VERSION ""

NS_ :

BS_:

BU_: SCM BC1 BC2 ECM PSC ABS Brakes__Drive_Axle_1 EPS IC GPS WCM VCM Seat_Control_1 ISC1 HCU IDT GMRS XM RH AUTON LHC CIM IMU BC3 IC2 EPC1 EPC2 EPC3 EPC4 BMC1 BMC2 APU2 APU1 SRVTOOL RHC RCM

BO_ 2566884352 Torque_Data_00: 8 ECM
 SG_ Message_Checksum : 61|4@1+ (1,0) [0|15] "count" Vector__XXX
 SG_ pEstimated_Torque : 16|16@1+ (0.03125,-1024) [-1024|3071] "Nm" Vector__XXX
 SG_ pCurrent_RPM_Rated_Torque : 0|16@1+ (0.03125,-1024) [-1024|3071] "Nm" Vector__XXX
 SG_ Brake_Switch : 56|2@1+ (1,0) [0|3] "bit" Vector__XXX
 SG_ Message_Counter : 58|4@1+ (1,0) [0|15] "count" Vector__XXX

BO_ 2566876928 pER1_00: 8 ECM
 SG_ pSecondary_Air_Valve_Control : 0|2@1+ (1,0) [0|3] "state" Vector__XXX

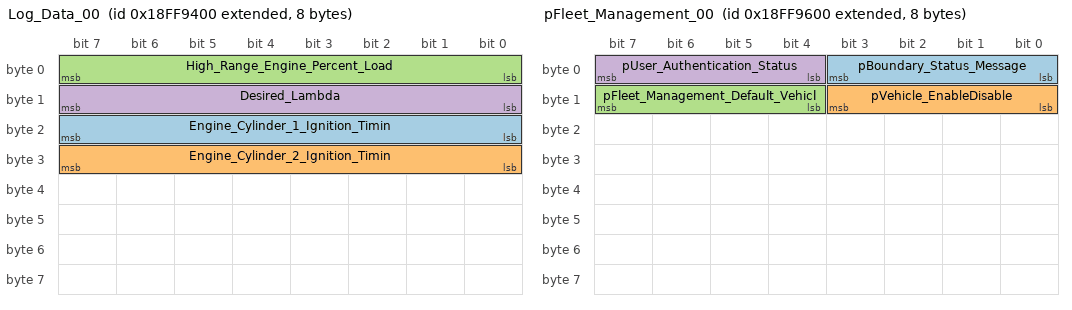
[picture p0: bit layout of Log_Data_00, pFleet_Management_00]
BO_ 2566886400 Log_Data_00: 8 ECM
 SG_ Engine_Cylinder_1_Ignition_Timin : 16|8@1+ (1,-128) [-128|383] "deg" Vector__XXX
 SG_ Engine_Cylinder_2_Ignition_Timin : 24|8@1+ (1,-128) [-128|383] "deg" Vector__XXX
 SG_ High_Range_Engine_Percent_Load : 0|8@1+ (2,0) [0|511] "%" Vector__XXX
 SG_ Desired_Lambda : 8|8@1+ (0.0078125,0) [0|1] "" Vector__XXX

BO_ 2566886912 pFleet_Management_00: 8 ECM
 SG_ pBoundary_Status_Message : 0|4@1+ (1,0) [0|15] "state" Vector__XXX
 SG_ pVehicle_EnableDisable : 8|4@1+ (1,0) [0|15] "state" Vector__XXX
 SG_ pFleet_Management_Default_Vehicl : 12|4@1+ (1,0) [0|15] "state" Vector__XXX
 SG_ pUser_Authentication_Status : 4|4@1+ (1,0) [0|15] "state" Vector__XXX

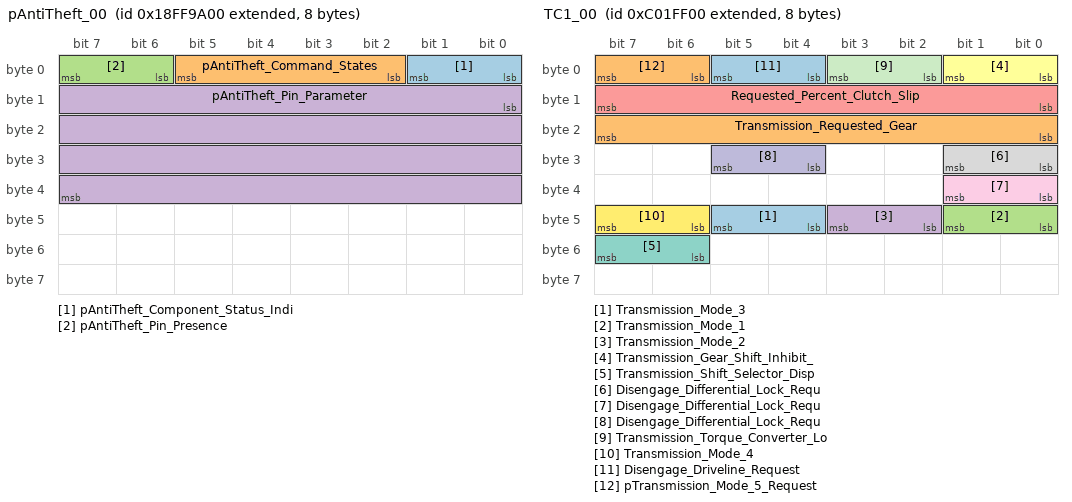
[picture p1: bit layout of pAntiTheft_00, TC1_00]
BO_ 2566887936 pAntiTheft_00: 8 ECM
 SG_ pAntiTheft_Component_Status_Indi : 0|2@1+ (1,0) [0|3] "state" Vector__XXX
 SG_ pAntiTheft_Command_States : 2|4@1+ (1,0) [0|15] "state" Vector__XXX
 SG_ pAntiTheft_Pin_Presence : 6|2@1+ (1,0) [0|3] "state" Vector__XXX
 SG_ pAntiTheft_Pin_Parameter : 8|32@1+ (1,0) [0|4294967295] "ASCII" Vector__XXX

BO_ 2348941056 TC1_00: 8 ECM
 SG_ Transmission_Mode_3 : 44|2@1+ (1,0) [0|3] "bit" TCM
 SG_ Transmission_Requested_Gear : 16|8@1+ (1,-125) [-125|380] "gear_value" TCM
 SG_ Transmission_Mode_1 : 40|2@1+ (1,0) [0|3] "bit" TCM
 SG_ Transmission_Mode_2 : 42|2@1+ (1,0) [0|3] "bit" TCM
 SG_ Requested_Percent_Clutch_Slip : 8|8@1+ (0.4,0) [0|101.4] "%" TCM
 SG_ Transmission_Gear_Shift_Inhibit_ : 0|2@1+ (1,0) [0|3] "bit" TCM
 SG_ Transmission_Shift_Selector_Disp : 54|2@1+ (1,0) [0|3] "bit" TCM
 SG_ Disengage_Differential_Lock_Requ : 24|2@1+ (1,0) [0|3] "bit" TCM
 SG_ Disengage_Differential_Lock_Requ : 32|2@1+ (1,0) [0|3] "bit" TCM
 SG_ Disengage_Differential_Lock_Requ : 28|2@1+ (1,0) [0|3] "bit" TCM
 SG_ Transmission_Torque_Converter_Lo : 2|2@1+ (1,0) [0|3] "bit" TCM
 SG_ Transmission_Mode_4 : 46|2@1+ (1,0) [0|3] "bit" TCM
 SG_ Disengage_Driveline_Request : 4|2@1+ (1,0) [0|3] "bit" TCM
 SG_ pTransmission_Mode_5_Request : 6|2@1+ (1,0) [0|3] "state" TCM

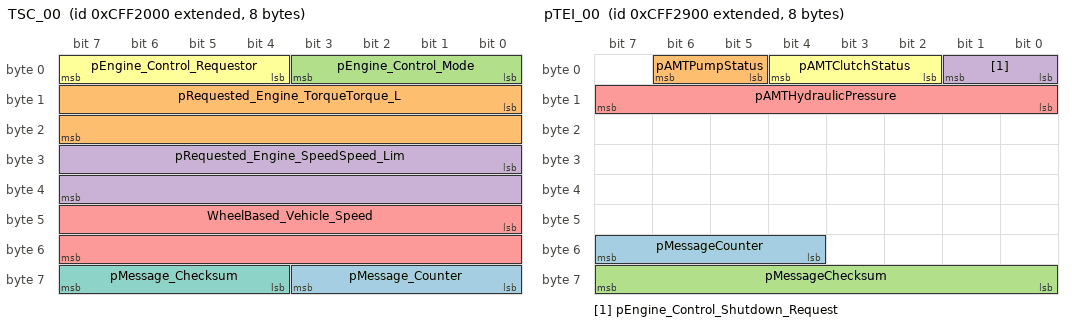
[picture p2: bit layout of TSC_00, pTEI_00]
BO_ 2365530112 TSC_00: 8 ECM
 SG_ pMessage_Counter : 56|4@1+ (1,0) [0|15] "count" TCM
 SG_ pRequested_Engine_TorqueTorque_L : 8|16@1+ (0.03125,-400) [-400|2447] "Nm" TCM
 SG_ pEngine_Control_Mode : 0|4@1+ (1,0) [0|15] "state" TCM
 SG_ pRequested_Engine_SpeedSpeed_Lim : 24|16@1+ (1,0) [0|65535] "rpm" TCM
 SG_ WheelBased_Vehicle_Speed : 40|16@1+ (0.00390625,0) [0|255] "km/h" TCM
 SG_ pEngine_Control_Requestor : 4|4@1+ (1,0) [0|15] "state" TCM
 SG_ pMessage_Checksum : 60|4@1+ (1,0) [0|15] "count" TCM

BO_ 2365532416 pTEI_00: 8 ECM
 SG_ pMessageCounter : 52|4@1+ (1,0) [0|15] "count" TCM
 SG_ pAMTPumpStatus : 5|2@1+ (1,0) [0|3] "state" TCM
 SG_ pMessageChecksum : 56|8@1+ (1,0) [0|255] "count" TCM
 SG_ pEngine_Control_Shutdown_Request : 0|2@1+ (1,0) [0|3] "state" TCM
 SG_ pAMTHydraulicPressure : 8|8@1+ (16,0) [0|4095] "kPa" TCM
 SG_ pAMTClutchStatus : 2|3@1+ (1,0) [0|7] "state" TCM

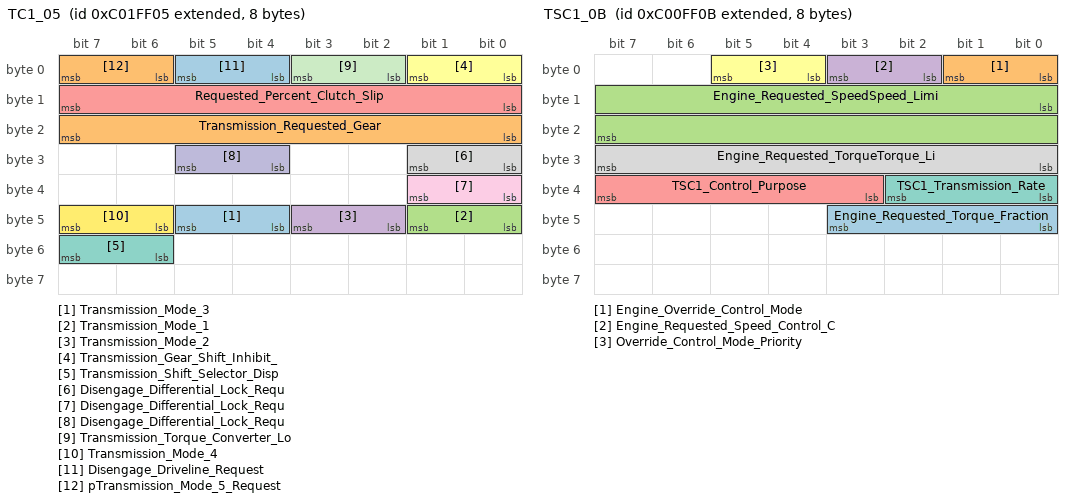
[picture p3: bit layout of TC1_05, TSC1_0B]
BO_ 2348941061 TC1_05: 8 PSC
 SG_ Transmission_Mode_3 : 44|2@1+ (1,0) [0|3] "bit" Vector__XXX
 SG_ Transmission_Requested_Gear : 16|8@1+ (1,-125) [-125|380] "gear_value" Vector__XXX
 SG_ Transmission_Mode_1 : 40|2@1+ (1,0) [0|3] "bit" Vector__XXX
 SG_ Transmission_Mode_2 : 42|2@1+ (1,0) [0|3] "bit" Vector__XXX
 SG_ Requested_Percent_Clutch_Slip : 8|8@1+ (0.4,0) [0|101.4] "%" Vector__XXX
 SG_ Transmission_Gear_Shift_Inhibit_ : 0|2@1+ (1,0) [0|3] "bit" Vector__XXX
 SG_ Transmission_Shift_Selector_Disp : 54|2@1+ (1,0) [0|3] "bit" Vector__XXX
 SG_ Disengage_Differential_Lock_Requ : 24|2@1+ (1,0) [0|3] "bit" Vector__XXX
 SG_ Disengage_Differential_Lock_Requ : 32|2@1+ (1,0) [0|3] "bit" Vector__XXX
 SG_ Disengage_Differential_Lock_Requ : 28|2@1+ (1,0) [0|3] "bit" Vector__XXX
 SG_ Transmission_Torque_Converter_Lo : 2|2@1+ (1,0) [0|3] "bit" Vector__XXX
 SG_ Transmission_Mode_4 : 46|2@1+ (1,0) [0|3] "bit" Vector__XXX
 SG_ Disengage_Driveline_Request : 4|2@1+ (1,0) [0|3] "bit" Vector__XXX
 SG_ pTransmission_Mode_5_Request : 6|2@1+ (1,0) [0|3] "state" Vector__XXX

BO_ 2348875531 TSC1_0B: 8 ABS
 SG_ Engine_Requested_Torque_Fraction : 40|4@1+ (0.125,0) [0|1] "%" Vector__XXX
 SG_ Engine_Override_Control_Mode : 0|2@1+ (1,0) [0|3] "bit" Vector__XXX
 SG_ Engine_Requested_SpeedSpeed_Limi : 8|16@1+ (0.125,0) [0|8191] "rpm" Vector__XXX
 SG_ Engine_Requested_Speed_Control_C : 2|2@1+ (1,0) [0|3] "bit" Vector__XXX
 SG_ TSC1_Control_Purpose : 35|5@1+ (1,0) [0|31] "bit" Vector__XXX
 SG_ Override_Control_Mode_Priority : 4|2@1+ (1,0) [0|3] "bit" Vector__XXX
 SG_ TSC1_Transmission_Rate : 32|3@1+ (1,0) [0|7] "bit" Vector__XXX
 SG_ Engine_Requested_TorqueTorque_Li : 24|8@1+ (1,-125) [-125|380] "%" Vector__XXX

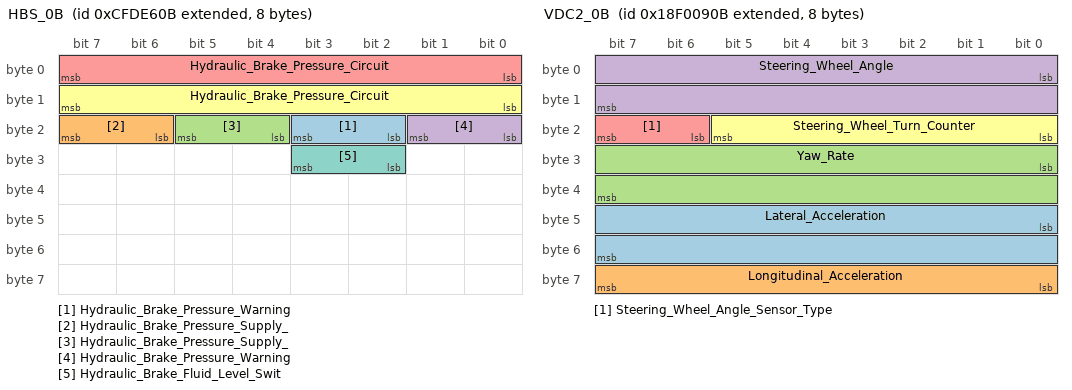
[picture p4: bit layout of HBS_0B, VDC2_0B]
BO_ 2365449739 HBS_0B: 8 ABS
 SG_ Hydraulic_Brake_Pressure_Warning : 18|2@1+ (1,0) [0|3] "bit" Vector__XXX
 SG_ Hydraulic_Brake_Pressure_Supply_ : 22|2@1+ (1,0) [0|3] "bit" Vector__XXX
 SG_ Hydraulic_Brake_Pressure_Supply_ : 20|2@1+ (1,0) [0|3] "bit" Vector__XXX
 SG_ Hydraulic_Brake_Pressure_Warning : 16|2@1+ (1,0) [0|3] "bit" Vector__XXX
 SG_ Hydraulic_Brake_Pressure_Circuit : 0|8@1+ (100,0) [0|25599] "kPa" Vector__XXX
 SG_ Hydraulic_Brake_Pressure_Circuit : 8|8@1+ (100,0) [0|25599] "kPa" Vector__XXX
 SG_ Hydraulic_Brake_Fluid_Level_Swit : 26|2@1+ (1,0) [0|3] "bit" Vector__XXX

BO_ 2565867787 VDC2_0B: 8 ABS
 SG_ Lateral_Acceleration : 40|16@1+ (0.00048828125,-15.687) [-15.687|46.687] "m/s2" Vector__XXX
 SG_ Longitudinal_Acceleration : 56|8@1+ (0.1,-12.5) [-12.5|37.1] "m/s2" Vector__XXX
 SG_ Yaw_Rate : 24|16@1+ (0.0001220703125,-3.92) [-3.92|10.92] "rad/s" Vector__XXX
 SG_ Steering_Wheel_Angle : 0|16@1+ (0.0009765625,-31.374) [-31.374|94.374] "rad" Vector__XXX
 SG_ Steering_Wheel_Angle_Sensor_Type : 22|2@1+ (1,0) [0|3] "bit" Vector__XXX
 SG_ Steering_Wheel_Turn_Counter : 16|6@1+ (1,-32) [-32|95] "turns" Vector__XXX

BO_ 2349465355 SRASI_0B: 8 ABS
 SG_ Static_Roll_Angle : 0|8@1+ (1,-125) [-125|380] "deg" Vector__XXX

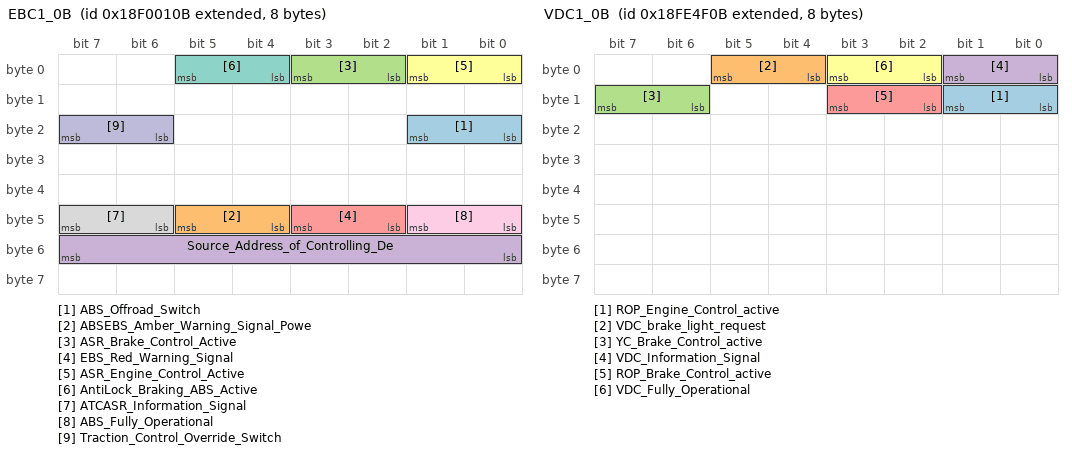
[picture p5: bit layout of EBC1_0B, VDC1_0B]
BO_ 2565865739 EBC1_0B: 8 ABS
 SG_ ABS_Offroad_Switch : 16|2@1+ (1,0) [0|3] "bit" Vector__XXX
 SG_ ABSEBS_Amber_Warning_Signal_Powe : 44|2@1+ (1,0) [0|3] "bit" Vector__XXX
 SG_ ASR_Brake_Control_Active : 2|2@1+ (1,0) [0|3] "bit" Vector__XXX
 SG_ Source_Address_of_Controlling_De : 48|8@1+ (1,0) [0|255] "SA" Vector__XXX
 SG_ EBS_Red_Warning_Signal : 42|2@1+ (1,0) [0|3] "bit" Vector__XXX
 SG_ ASR_Engine_Control_Active : 0|2@1+ (1,0) [0|3] "bit" Vector__XXX
 SG_ AntiLock_Braking_ABS_Active : 4|2@1+ (1,0) [0|3] "bit" Vector__XXX
 SG_ ATCASR_Information_Signal : 46|2@1+ (1,0) [0|3] "bit" Vector__XXX
 SG_ ABS_Fully_Operational : 40|2@1+ (1,0) [0|3] "bit" Vector__XXX
 SG_ Traction_Control_Override_Switch : 22|2@1+ (1,0) [0|3] "bit" Vector__XXX

BO_ 2566803211 VDC1_0B: 8 ABS
 SG_ ROP_Engine_Control_active : 8|2@1+ (1,0) [0|3] "bit" Vector__XXX
 SG_ VDC_brake_light_request : 4|2@1+ (1,0) [0|3] "bit" Vector__XXX
 SG_ YC_Brake_Control_active : 14|2@1+ (1,0) [0|3] "bit" Vector__XXX
 SG_ VDC_Information_Signal : 0|2@1+ (1,0) [0|3] "bit" Vector__XXX
 SG_ ROP_Brake_Control_active : 10|2@1+ (1,0) [0|3] "bit" Vector__XXX
 SG_ VDC_Fully_Operational : 2|2@1+ (1,0) [0|3] "bit" Vector__XXX

BO_ 2566834955 DM2_0B: 42 ABS
 SG_ Protect_Lamp_Status : 0|2@1+ (1,0) [0|3] "" Vector__XXX
 SG_ Amber_Warning_Lamp_Status : 2|2@1+ (1,0) [0|3] "" Vector__XXX
 SG_ Red_Stop_Lamp_Status : 4|2@1+ (1,0) [0|3] "" Vector__XXX
 SG_ Malfunction_Indicator_Lamp_Statu : 6|2@1+ (1,0) [0|3] "" Vector__XXX
 SG_ Flash_Protect_Lamp : 8|2@1+ (1,0) [0|3] "" Vector__XXX
 SG_ Flash_Amber_Warning_Lamp_AWL : 10|2@1+ (1,0) [0|3] "" Vector__XXX
 SG_ Flash_Red_Stop_Lamp_RSL : 12|2@1+ (1,0) [0|3] "" Vector__XXX
 SG_ Flash_Malfunction_Indicator_Lamp : 14|2@1+ (1,0) [0|3] "" Vector__XXX
 SG_ DTC_1 : 16|32@1+ (1,0) [0|4294967295] "value" Vector__XXX
 SG_ DTC_2 : 48|32@1+ (1,0) [0|4294967295] "value" Vector__XXX
 SG_ DTC_3 : 80|32@1+ (1,0) [0|4294967295] "value" Vector__XXX
 SG_ DTC_4 : 112|32@1+ (1,0) [0|4294967295] "value" Vector__XXX
 SG_ DTC_5 : 144|32@1+ (1,0) [0|4294967295] "value" Vector__XXX
 SG_ DTC_6 : 176|32@1+ (1,0) [0|4294967295] "value" Vector__XXX
 SG_ DTC_7 : 208|32@1+ (1,0) [0|4294967295] "value" Vector__XXX
 SG_ DTC_8 : 240|32@1+ (1,0) [0|4294967295] "value" Vector__XXX
 SG_ DTC_9 : 272|32@1+ (1,0) [0|4294967295] "value" Vector__XXX
 SG_ DTC_10 : 304|32@1+ (1,0) [0|4294967295] "value" Vector__XXX

BO_ 2566834699 DM1_0B: 42 ABS
 SG_ Flash_Malfunction_Indicator_Lamp : 14|2@1+ (1,0) [0|3] "" Vector__XXX
 SG_ Malfunction_Indicator_Lamp_Statu : 6|2@1+ (1,0) [0|3] "" Vector__XXX
 SG_ Red_Stop_Lamp_Status : 4|2@1+ (1,0) [0|3] "" Vector__XXX
 SG_ Amber_Warning_Lamp_Status : 2|2@1+ (1,0) [0|3] "" Vector__XXX
 SG_ Flash_Red_Stop_Lamp_RSL : 12|2@1+ (1,0) [0|3] "" Vector__XXX
 SG_ Flash_Amber_Warning_Lamp_AWL : 10|2@1+ (1,0) [0|3] "" Vector__XXX
 SG_ Flash_Protect_Lamp : 8|2@1+ (1,0) [0|3] "" Vector__XXX
 SG_ Protect_Lamp_Status : 0|2@1+ (1,0) [0|3] "" Vector__XXX
 SG_ DTC_1 : 16|32@1+ (1,0) [0|4294967295] "value" Vector__XXX
 SG_ DTC_2 : 48|32@1+ (1,0) [0|4294967295] "value" Vector__XXX
 SG_ DTC_3 : 80|32@1+ (1,0) [0|4294967295] "value" Vector__XXX
 SG_ DTC_4 : 112|32@1+ (1,0) [0|4294967295] "value" Vector__XXX
 SG_ DTC_5 : 144|32@1+ (1,0) [0|4294967295] "value" Vector__XXX
 SG_ DTC_6 : 176|32@1+ (1,0) [0|4294967295] "value" Vector__XXX
 SG_ DTC_7 : 208|32@1+ (1,0) [0|4294967295] "value" Vector__XXX
 SG_ DTC_8 : 240|32@1+ (1,0) [0|4294967295] "value" Vector__XXX
 SG_ DTC_9 : 272|32@1+ (1,0) [0|4294967295] "value" Vector__XXX
 SG_ DTC_10 : 304|32@1+ (1,0) [0|4294967295] "value" Vector__XXX

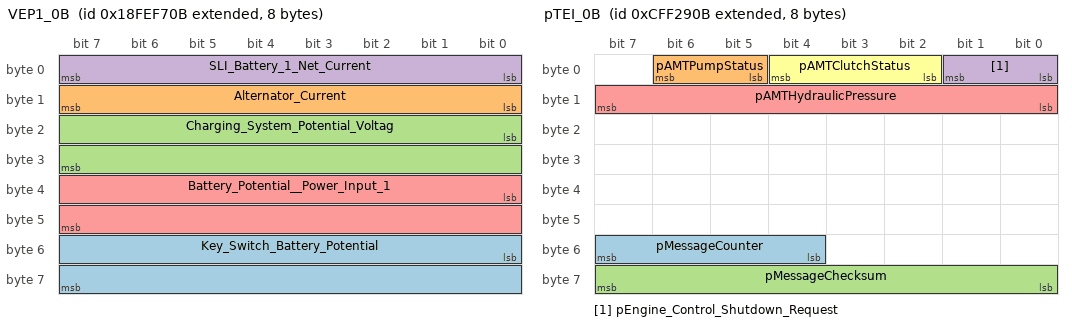
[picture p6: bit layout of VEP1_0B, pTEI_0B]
BO_ 2566846219 VEP1_0B: 8 ABS
 SG_ Key_Switch_Battery_Potential : 48|16@1+ (0.05,0) [0|3275.8] "V" Vector__XXX
 SG_ Alternator_Current : 8|8@1+ (1,0) [0|255] "A" Vector__XXX
 SG_ Charging_System_Potential_Voltag : 16|16@1+ (0.05,0) [0|3275.8] "V" Vector__XXX
 SG_ SLI_Battery_1_Net_Current : 0|8@1+ (1,-125) [-125|380] "A" Vector__XXX
 SG_ Battery_Potential__Power_Input_1 : 32|16@1+ (0.05,0) [0|3275.8] "V" Vector__XXX

BO_ 2365532427 pTEI_0B: 8 ABS
 SG_ pMessageCounter : 52|4@1+ (1,0) [0|15] "count" Vector__XXX
 SG_ pAMTPumpStatus : 5|2@1+ (1,0) [0|3] "state" Vector__XXX
 SG_ pMessageChecksum : 56|8@1+ (1,0) [0|255] "count" Vector__XXX
 SG_ pEngine_Control_Shutdown_Request : 0|2@1+ (1,0) [0|3] "state" Vector__XXX
 SG_ pAMTHydraulicPressure : 8|8@1+ (16,0) [0|4095] "kPa" Vector__XXX
 SG_ pAMTClutchStatus : 2|3@1+ (1,0) [0|7] "state" Vector__XXX

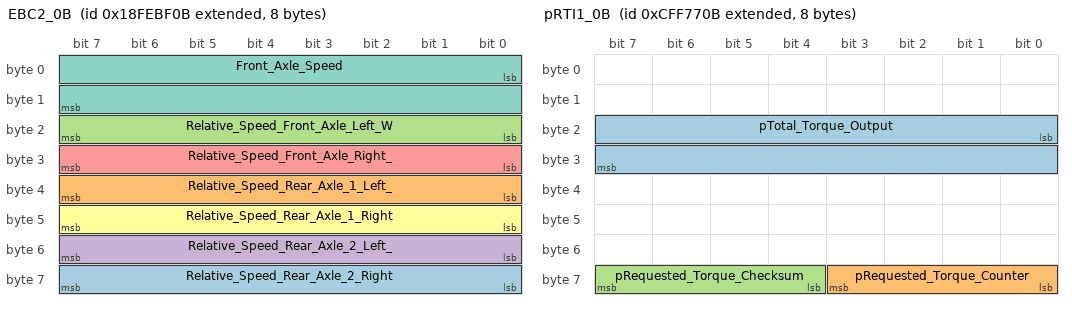
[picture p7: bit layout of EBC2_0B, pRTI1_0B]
BO_ 2566831883 EBC2_0B: 8 ABS
 SG_ Relative_Speed_Rear_Axle_2_Right : 56|8@1+ (0.0625,-7.8125) [-7.8125|22.8125] "km/h" Vector__XXX
 SG_ Relative_Speed_Rear_Axle_1_Left_ : 32|8@1+ (0.0625,-7.8125) [-7.8125|22.8125] "km/h" Vector__XXX
 SG_ Relative_Speed_Front_Axle_Left_W : 16|8@1+ (0.0625,-7.8125) [-7.8125|22.8125] "km/h" Vector__XXX
 SG_ Relative_Speed_Rear_Axle_2_Left_ : 48|8@1+ (0.0625,-7.8125) [-7.8125|22.8125] "km/h" Vector__XXX
 SG_ Relative_Speed_Front_Axle_Right_ : 24|8@1+ (0.0625,-7.8125) [-7.8125|22.8125] "km/h" Vector__XXX
 SG_ Relative_Speed_Rear_Axle_1_Right : 40|8@1+ (0.0625,-7.8125) [-7.8125|22.8125] "km/h" Vector__XXX
 SG_ Front_Axle_Speed : 0|16@1+ (0.00390625,0) [0|255] "km/h" Vector__XXX

BO_ 2566844683 CCVS1_0B: 8 ABS
 SG_ Cruise_Control_Set_Speed : 40|8@1+ (1,0) [0|255] "km/h" Vector__XXX
 SG_ Cruise_Control_Active : 24|2@1+ (1,0) [0|3] "bit" Vector__XXX
 SG_ Clutch_Switch : 30|2@1+ (1,0) [0|3] "bit" Vector__XXX
 SG_ Brake_Switch : 28|2@1+ (1,0) [0|3] "bit" Vector__XXX
 SG_ pCC_Message_Counter : 52|4@1+ (1,0) [0|15] "count" Vector__XXX
 SG_ Cruise_Control_Pause_Switch : 4|2@1+ (1,0) [0|3] "bit" Vector__XXX
 SG_ Cruise_Control_Set_Switch : 32|2@1+ (1,0) [0|3] "bit" Vector__XXX
 SG_ Two_Speed_Axle_Switch : 0|2@1+ (1,0) [0|3] "bit" Vector__XXX
 SG_ Cruise_Control_Enable_Switch : 26|2@1+ (1,0) [0|3] "bit" Vector__XXX
 SG_ pOdometer_Drive_Bit : 6|2@1+ (1,0) [0|3] "state" Vector__XXX
 SG_ pCC_Checksum : 56|8@1+ (1,0) [0|255] "" Vector__XXX
 SG_ WheelBased_Vehicle_Speed : 8|16@1+ (0.00390625,0) [0|255] "km/h" Vector__XXX
 SG_ Cruise_Control_Resume_Switch : 36|2@1+ (1,0) [0|3] "bit" Vector__XXX
 SG_ Cruise_Control_Accelerate_Switch : 38|2@1+ (1,0) [0|3] "bit" Vector__XXX
 SG_ pCruise_Enable_Status : 48|4@1+ (1,0) [0|15] "state" Vector__XXX
 SG_ Parking_Brake_Switch : 2|2@1+ (1,0) [0|3] "bit" Vector__XXX
 SG_ Cruise_Control_Coast_Decelerate_ : 34|2@1+ (1,0) [0|3] "bit" Vector__XXX

BO_ 2365552395 pRTI1_0B: 8 ABS
 SG_ pTotal_Torque_Output : 16|16@1+ (1,0) [0|65535] "Nm" Vector__XXX
 SG_ pRequested_Torque_Counter : 56|4@1+ (1,0) [0|15] "count" Vector__XXX
 SG_ pRequested_Torque_Checksum : 60|4@1+ (1,0) [0|15] "count" Vector__XXX

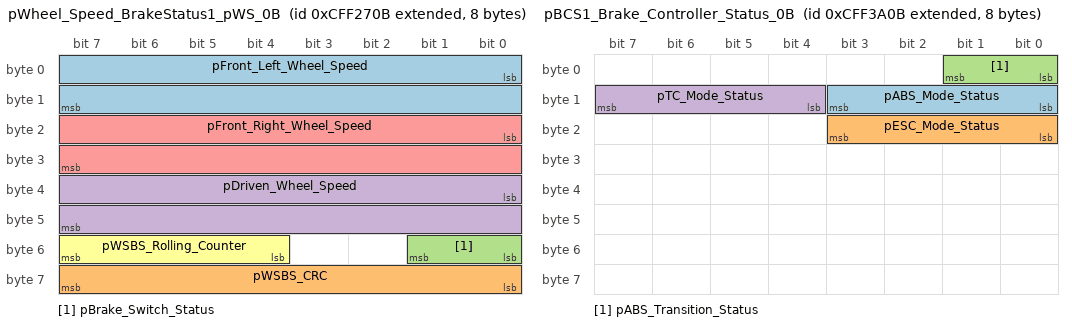
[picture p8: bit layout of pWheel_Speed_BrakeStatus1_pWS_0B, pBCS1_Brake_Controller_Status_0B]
BO_ 2365531915 pWheel_Speed_BrakeStatus1_pWS_0B: 8 ABS
 SG_ pFront_Left_Wheel_Speed : 0|16@1+ (0.1,0) [0|6552.6] "rpm" Vector__XXX
 SG_ pWSBS_CRC : 56|8@1+ (1,0) [0|255] "" Vector__XXX
 SG_ pBrake_Switch_Status : 48|2@1+ (1,0) [0|3] "state" Vector__XXX
 SG_ pDriven_Wheel_Speed : 32|16@1+ (0.1,0) [0|6552.6] "rpm" Vector__XXX
 SG_ pFront_Right_Wheel_Speed : 16|16@1+ (0.1,0) [0|6552.6] "rpm" Vector__XXX
 SG_ pWSBS_Rolling_Counter : 52|4@1+ (1,0) [0|15] "count" Vector__XXX

BO_ 2365536779 pBCS1_Brake_Controller_Status_0B: 8 ABS
 SG_ pABS_Mode_Status : 8|4@1+ (1,0) [0|15] "state" Vector__XXX
 SG_ pESC_Mode_Status : 16|4@1+ (1,0) [0|15] "state" Vector__XXX
 SG_ pABS_Transition_Status : 0|2@1+ (1,0) [0|3] "state" Vector__XXX
 SG_ pTC_Mode_Status : 12|4@1+ (1,0) [0|15] "state" Vector__XXX

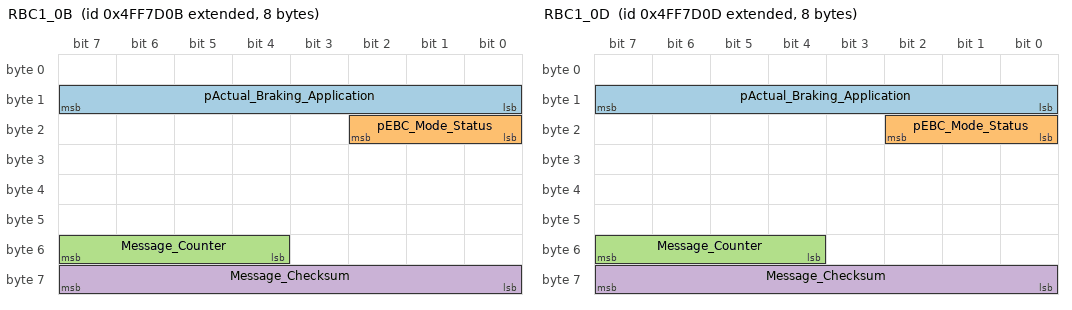
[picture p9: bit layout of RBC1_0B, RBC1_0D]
BO_ 2231336203 RBC1_0B: 8 ABS
 SG_ pActual_Braking_Application : 8|8@1+ (0.4,0) [0|101.4] "" Vector__XXX
 SG_ pEBC_Mode_Status : 16|3@1+ (1,0) [0|7] "state" Vector__XXX
 SG_ Message_Counter : 52|4@1+ (1,0) [0|15] "" Vector__XXX
 SG_ Message_Checksum : 56|8@1+ (1,0) [0|255] "" Vector__XXX

BO_ 2231336205 RBC1_0D: 8 Brakes__Drive_Axle_1
 SG_ pActual_Braking_Application : 8|8@1+ (0.4,0) [0|101.4] "" Vector__XXX
 SG_ pEBC_Mode_Status : 16|3@1+ (1,0) [0|7] "state" Vector__XXX
 SG_ Message_Counter : 52|4@1+ (1,0) [0|15] "" Vector__XXX
 SG_ Message_Checksum : 56|8@1+ (1,0) [0|255] "" Vector__XXX

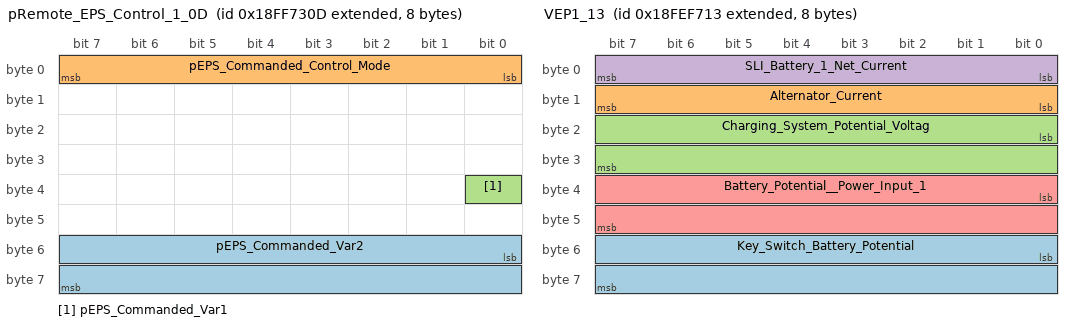
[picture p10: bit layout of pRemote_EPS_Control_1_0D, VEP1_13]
BO_ 2566877965 pRemote_EPS_Control_1_0D: 8 Brakes__Drive_Axle_1
 SG_ pEPS_Commanded_Var2 : 48|16@1+ (1,0) [0|65535] "" Vector__XXX
 SG_ pEPS_Commanded_Control_Mode : 0|8@1+ (1,0) [0|255] "state" Vector__XXX
 SG_ pEPS_Commanded_Var1 : 32|1@1+ (1,0) [0|0] "" Vector__XXX

BO_ 2566846227 VEP1_13: 8 EPS
 SG_ Key_Switch_Battery_Potential : 48|16@1+ (0.05,0) [0|3275.8] "V" Vector__XXX
 SG_ Alternator_Current : 8|8@1+ (1,0) [0|255] "A" Vector__XXX
 SG_ Charging_System_Potential_Voltag : 16|16@1+ (0.05,0) [0|3275.8] "V" Vector__XXX
 SG_ SLI_Battery_1_Net_Current : 0|8@1+ (1,-125) [-125|380] "A" Vector__XXX
 SG_ Battery_Potential__Power_Input_1 : 32|16@1+ (0.05,0) [0|3275.8] "V" Vector__XXX

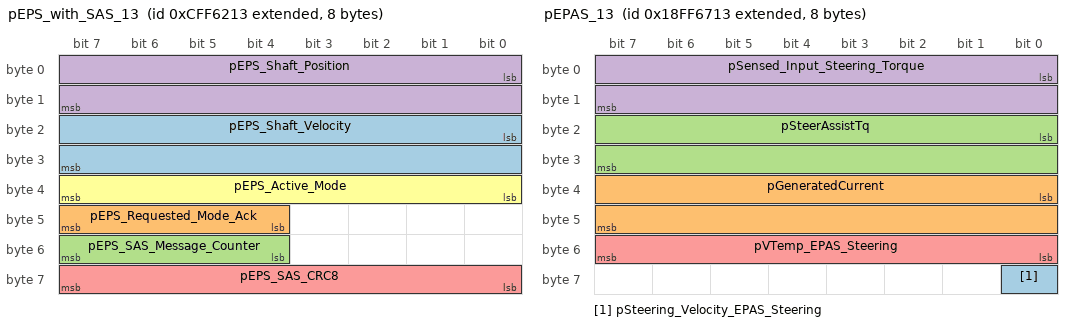
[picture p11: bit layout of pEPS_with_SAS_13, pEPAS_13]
BO_ 2365547027 pEPS_with_SAS_13: 8 EPS
 SG_ pEPS_Shaft_Velocity : 16|16@1+ (0.1,-3276.5) [-3276.5|9829.1] "deg/s" Vector__XXX
 SG_ pEPS_Requested_Mode_Ack : 44|4@1+ (1,0) [0|15] "state" Vector__XXX
 SG_ pEPS_SAS_Message_Counter : 52|4@1+ (1,0) [0|15] "state" Vector__XXX
 SG_ pEPS_Shaft_Position : 0|16@1+ (0.1,-3276.5) [-3276.5|9829.1] "deg" Vector__XXX
 SG_ pEPS_SAS_CRC8 : 56|8@1+ (1,0) [0|255] "count" Vector__XXX
 SG_ pEPS_Active_Mode : 32|8@1+ (1,0) [0|255] "state" Vector__XXX

BO_ 2566874899 pEPAS_13: 8 EPS
 SG_ pSteering_Velocity_EPAS_Steering : 56|1@1+ (1,0) [0|0] "" Vector__XXX
 SG_ pGeneratedCurrent : 32|16@1+ (0.003814697265625,-125) [-125|374] "A" Vector__XXX
 SG_ pSteerAssistTq : 16|16@1+ (0.1,-3200) [-3200|9752.6] "Nm" Vector__XXX
 SG_ pSensed_Input_Steering_Torque : 0|16@1+ (0.1,-3200) [-3200|9752.6] "Nm" Vector__XXX
 SG_ pVTemp_EPAS_Steering : 48|8@1+ (1,-40) [-40|295] "deg C" Vector__XXX

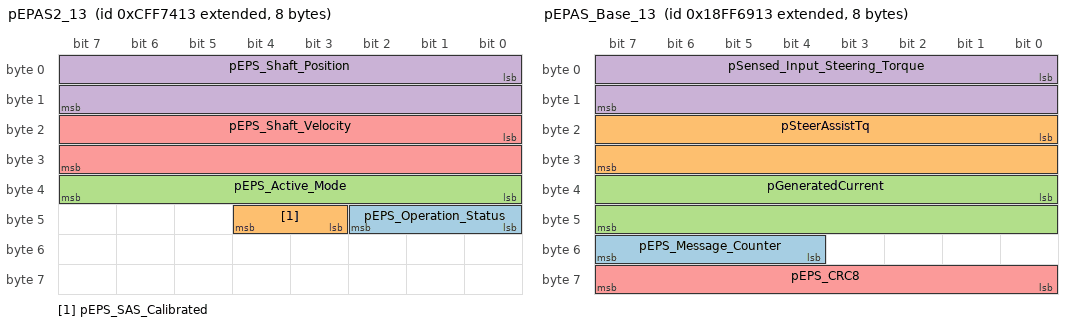
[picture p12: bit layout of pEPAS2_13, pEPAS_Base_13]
BO_ 2365551635 pEPAS2_13: 8 EPS
 SG_ pEPS_Operation_Status : 40|3@1+ (1,0) [0|7] "state" Vector__XXX
 SG_ pEPS_SAS_Calibrated : 43|2@1+ (1,0) [0|3] "state" Vector__XXX
 SG_ pEPS_Active_Mode : 32|8@1+ (1,0) [0|255] "state" Vector__XXX
 SG_ pEPS_Shaft_Position : 0|16@1+ (0.1,-3276.5) [-3276.5|9829.1] "deg" Vector__XXX
 SG_ pEPS_Shaft_Velocity : 16|16@1+ (0.1,-3276.5) [-3276.5|9829.1] "deg/s" Vector__XXX

BO_ 2566875411 pEPAS_Base_13: 8 EPS
 SG_ pEPS_Message_Counter : 52|4@1+ (1,0) [0|15] "" Vector__XXX
 SG_ pSteerAssistTq : 16|16@1+ (0.1,-3200) [-3200|9752.6] "Nm" Vector__XXX
 SG_ pGeneratedCurrent : 32|16@1+ (0.003814697265625,-125) [-125|374] "A" Vector__XXX
 SG_ pSensed_Input_Steering_Torque : 0|16@1+ (0.1,-3200) [-3200|9752.6] "Nm" Vector__XXX
 SG_ pEPS_CRC8 : 56|8@1+ (1,0) [0|255] "count" Vector__XXX

BO_ 2566834707 DM1_13: 42 EPS
 SG_ Flash_Malfunction_Indicator_Lamp : 14|2@1+ (1,0) [0|3] "" Vector__XXX
 SG_ Malfunction_Indicator_Lamp_Statu : 6|2@1+ (1,0) [0|3] "" Vector__XXX
 SG_ Red_Stop_Lamp_Status : 4|2@1+ (1,0) [0|3] "" Vector__XXX
 SG_ Amber_Warning_Lamp_Status : 2|2@1+ (1,0) [0|3] "" Vector__XXX
 SG_ Flash_Red_Stop_Lamp_RSL : 12|2@1+ (1,0) [0|3] "" Vector__XXX
 SG_ Flash_Amber_Warning_Lamp_AWL : 10|2@1+ (1,0) [0|3] "" Vector__XXX
 SG_ Flash_Protect_Lamp : 8|2@1+ (1,0) [0|3] "" Vector__XXX
 SG_ Protect_Lamp_Status : 0|2@1+ (1,0) [0|3] "" Vector__XXX
 SG_ DTC_1 : 16|32@1+ (1,0) [0|4294967295] "value" Vector__XXX
 SG_ DTC_2 : 48|32@1+ (1,0) [0|4294967295] "value" Vector__XXX
 SG_ DTC_3 : 80|32@1+ (1,0) [0|4294967295] "value" Vector__XXX
 SG_ DTC_4 : 112|32@1+ (1,0) [0|4294967295] "value" Vector__XXX
 SG_ DTC_5 : 144|32@1+ (1,0) [0|4294967295] "value" Vector__XXX
 SG_ DTC_6 : 176|32@1+ (1,0) [0|4294967295] "value" Vector__XXX
 SG_ DTC_7 : 208|32@1+ (1,0) [0|4294967295] "value" Vector__XXX
 SG_ DTC_8 : 240|32@1+ (1,0) [0|4294967295] "value" Vector__XXX
 SG_ DTC_9 : 272|32@1+ (1,0) [0|4294967295] "value" Vector__XXX
 SG_ DTC_10 : 304|32@1+ (1,0) [0|4294967295] "value" Vector__XXX

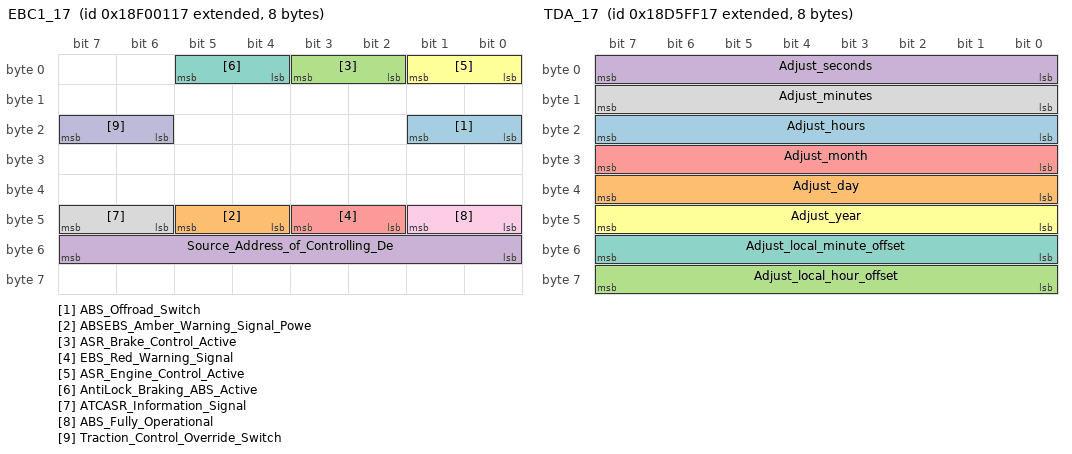
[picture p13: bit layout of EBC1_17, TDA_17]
BO_ 2565865751 EBC1_17: 8 IC
 SG_ ABS_Offroad_Switch : 16|2@1+ (1,0) [0|3] "bit" Vector__XXX
 SG_ ABSEBS_Amber_Warning_Signal_Powe : 44|2@1+ (1,0) [0|3] "bit" Vector__XXX
 SG_ ASR_Brake_Control_Active : 2|2@1+ (1,0) [0|3] "bit" Vector__XXX
 SG_ Source_Address_of_Controlling_De : 48|8@1+ (1,0) [0|255] "SA" Vector__XXX
 SG_ EBS_Red_Warning_Signal : 42|2@1+ (1,0) [0|3] "bit" Vector__XXX
 SG_ ASR_Engine_Control_Active : 0|2@1+ (1,0) [0|3] "bit" Vector__XXX
 SG_ AntiLock_Braking_ABS_Active : 4|2@1+ (1,0) [0|3] "bit" Vector__XXX
 SG_ ATCASR_Information_Signal : 46|2@1+ (1,0) [0|3] "bit" Vector__XXX
 SG_ ABS_Fully_Operational : 40|2@1+ (1,0) [0|3] "bit" Vector__XXX
 SG_ Traction_Control_Override_Switch : 22|2@1+ (1,0) [0|3] "bit" Vector__XXX

BO_ 2631859991 RESET_17: 8 IC
 SG_ Trip_Group_1 : 0|2@1+ (1,0) [0|3] "bit" Vector__XXX
 SG_ Trip_Group_2__Proprietary : 2|2@1+ (1,0) [0|3] "bit" Vector__XXX

BO_ 2566834711 DM1_17: 42 IC
 SG_ Flash_Malfunction_Indicator_Lamp : 14|2@1+ (1,0) [0|3] "" Vector__XXX
 SG_ Malfunction_Indicator_Lamp_Statu : 6|2@1+ (1,0) [0|3] "" Vector__XXX
 SG_ Red_Stop_Lamp_Status : 4|2@1+ (1,0) [0|3] "" Vector__XXX
 SG_ Amber_Warning_Lamp_Status : 2|2@1+ (1,0) [0|3] "" Vector__XXX
 SG_ Flash_Red_Stop_Lamp_RSL : 12|2@1+ (1,0) [0|3] "" Vector__XXX
 SG_ Flash_Amber_Warning_Lamp_AWL : 10|2@1+ (1,0) [0|3] "" Vector__XXX
 SG_ Flash_Protect_Lamp : 8|2@1+ (1,0) [0|3] "" Vector__XXX
 SG_ Protect_Lamp_Status : 0|2@1+ (1,0) [0|3] "" Vector__XXX
 SG_ DTC_1 : 16|32@1+ (1,0) [0|4294967295] "value" Vector__XXX
 SG_ DTC_2 : 48|32@1+ (1,0) [0|4294967295] "value" Vector__XXX
 SG_ DTC_3 : 80|32@1+ (1,0) [0|4294967295] "value" Vector__XXX
 SG_ DTC_4 : 112|32@1+ (1,0) [0|4294967295] "value" Vector__XXX
 SG_ DTC_5 : 144|32@1+ (1,0) [0|4294967295] "value" Vector__XXX
 SG_ DTC_6 : 176|32@1+ (1,0) [0|4294967295] "value" Vector__XXX
 SG_ DTC_7 : 208|32@1+ (1,0) [0|4294967295] "value" Vector__XXX
 SG_ DTC_8 : 240|32@1+ (1,0) [0|4294967295] "value" Vector__XXX
 SG_ DTC_9 : 272|32@1+ (1,0) [0|4294967295] "value" Vector__XXX
 SG_ DTC_10 : 304|32@1+ (1,0) [0|4294967295] "value" Vector__XXX

BO_ 2564161303 TDA_17: 8 IC
 SG_ Adjust_hours : 16|8@1+ (1,0) [0|255] "h" Vector__XXX
 SG_ Adjust_day : 32|8@1+ (0.25,0) [0|63] "days" Vector__XXX
 SG_ Adjust_local_hour_offset : 56|8@1+ (1,-125) [-125|380] "h" Vector__XXX
 SG_ Adjust_seconds : 0|8@1+ (0.25,0) [0|63] "s" Vector__XXX
 SG_ Adjust_month : 24|8@1+ (1,0) [0|255] "months" Vector__XXX
 SG_ Adjust_year : 40|8@1+ (1,1985) [1985|-1730] "years" Vector__XXX
 SG_ Adjust_local_minute_offset : 48|8@1+ (1,-125) [-125|380] "min" Vector__XXX
 SG_ Adjust_minutes : 8|8@1+ (1,0) [0|255] "min" Vector__XXX

BO_ 2563833623 CL_17: 8 IC
 SG_ Illumination_Brightness_Percent : 0|8@1+ (0.4,0) [0|101.4] "%" Vector__XXX

BO_ 2566832407 VDHR_17: 8 IC
 SG_ Total_Vehicle_Distance_High_Reso : 0|32@1+ (5,0) [0|21474836479] "m" Vector__XXX
 SG_ Trip_Distance_High_Resolution : 0|32@1+ (5,0) [0|21474836479] "m" Vector__XXX

BO_ 2566847511 DD_17: 8 IC
 SG_ Fuel_Level_1 : 8|8@1+ (0.4,0) [0|101.4] "%" Vector__XXX

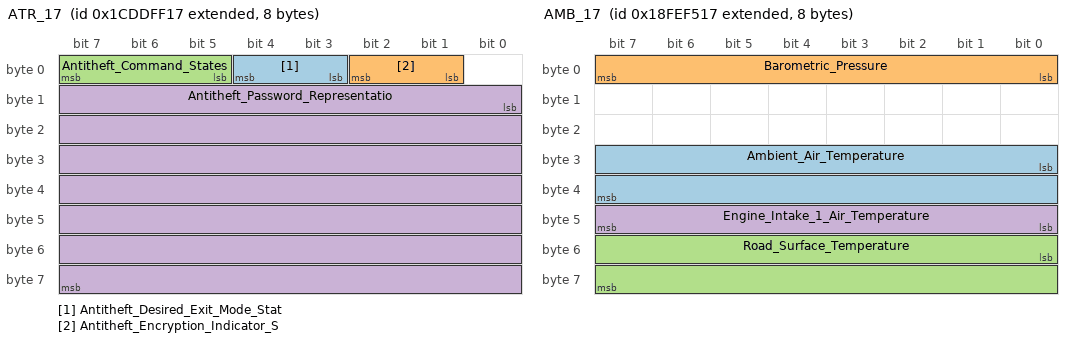
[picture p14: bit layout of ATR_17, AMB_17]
BO_ 2631794455 ATR_17: 8 IC
 SG_ Antitheft_Desired_Exit_Mode_Stat : 3|2@1+ (1,0) [0|3] "bit" Vector__XXX
 SG_ Antitheft_Encryption_Indicator_S : 1|2@1+ (1,0) [0|3] "bit" Vector__XXX
 SG_ Antitheft_Command_States : 5|3@1+ (1,0) [0|7] "bit" Vector__XXX
 SG_ Antitheft_Password_Representatio : 8|56@1+ (0,0) [0|-1] "ASCII" Vector__XXX

BO_ 2566845719 AMB_17: 8 IC
 SG_ Ambient_Air_Temperature : 24|16@1+ (0.03125,-273) [-273|2320] "deg C" Vector__XXX
 SG_ Barometric_Pressure : 0|8@1+ (0.5,0) [0|127] "kPa" Vector__XXX
 SG_ Road_Surface_Temperature : 48|16@1+ (0.03125,-273) [-273|2320] "deg C" Vector__XXX
 SG_ Engine_Intake_1_Air_Temperature : 40|8@1+ (1,-40) [-40|295] "deg C" Vector__XXX

BO_ 2432658455 pOSS2_17: 8 IC
 SG_ pFOCC_Checksum : 56|8@1+ (1,0) [0|255] "" Vector__XXX
 SG_ Drive_Mode__4 : 6|2@1+ (1,0) [0|3] "state" Vector__XXX
 SG_ Drive_Mode__2 : 2|2@1+ (1,0) [0|3] "state" Vector__XXX
 SG_ pFOCC_Message_Counter : 48|4@1+ (1,0) [0|15] "" Vector__XXX
 SG_ Drivers_Net_Engagement : 12|2@1+ (1,0) [0|3] "state" Vector__XXX
 SG_ Foot_On_Cruise_Control_Switch : 22|2@1+ (1,0) [0|3] "state" Vector__XXX
 SG_ Drive_Mode__1 : 0|2@1+ (1,0) [0|3] "state" Vector__XXX
 SG_ Momentary_Driveline_Left_Press : 24|2@1+ (1,0) [0|3] "state" Vector__XXX
 SG_ CylDeAc_Enable : 32|2@1+ (1,0) [0|3] "state" Vector__XXX
 SG_ Work_Group_Lock_Switch : 16|2@1+ (1,0) [0|3] "state" Vector__XXX
 SG_ Drivers_Seatbelt_Engagement : 10|2@1+ (1,0) [0|3] "state" Vector__XXX
 SG_ Drive_Mode__3 : 4|2@1+ (1,0) [0|3] "state" Vector__XXX
 SG_ Work_Mode_Switch : 20|2@1+ (1,0) [0|3] "state" Vector__XXX
 SG_ Momentary_Driveline_Right_Press : 26|2@1+ (1,0) [0|3] "state" Vector__XXX
 SG_ PTO_Mode_Switch_RPM_Control : 8|2@1+ (1,0) [0|3] "state" Vector__XXX
 SG_ Operator_Presence_Switch : 18|2@1+ (1,0) [0|3] "state" Vector__XXX
 SG_ Tilt_Lock_Switch : 14|2@1+ (1,0) [0|3] "state" Vector__XXX
 SG_ Engine_Brake_Enable : 34|2@1+ (1,0) [0|3] "state" Vector__XXX
 SG_ Accessory_Relay : 28|2@1+ (1,0) [0|3] "state" Vector__XXX

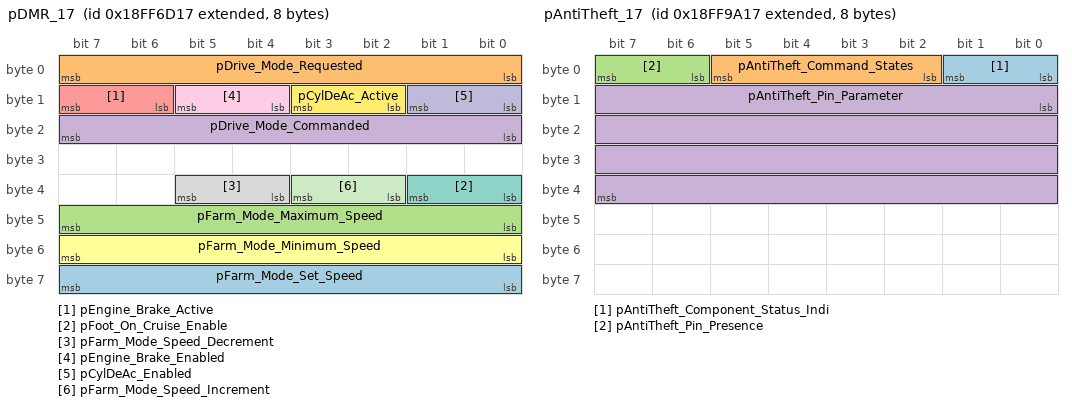
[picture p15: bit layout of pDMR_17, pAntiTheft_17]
BO_ 2566876439 pDMR_17: 8 IC
 SG_ pFarm_Mode_Set_Speed : 56|8@1+ (0.4,0) [0|101.4] "km/h" Vector__XXX
 SG_ pDrive_Mode_Requested : 0|8@1+ (1,0) [0|255] "ASCII" Vector__XXX
 SG_ pFarm_Mode_Maximum_Speed : 40|8@1+ (0.4,0) [0|101.4] "km/h" Vector__XXX
 SG_ pDrive_Mode_Commanded : 16|8@1+ (1,0) [0|255] "ASCII" Vector__XXX
 SG_ pEngine_Brake_Active : 14|2@1+ (1,0) [0|3] "state" Vector__XXX
 SG_ pFarm_Mode_Minimum_Speed : 48|8@1+ (0.4,0) [0|101.4] "km/h" Vector__XXX
 SG_ pFoot_On_Cruise_Enable : 32|2@1+ (1,0) [0|3] "state" Vector__XXX
 SG_ pFarm_Mode_Speed_Decrement : 36|2@1+ (0,0) [0|-1] "state" Vector__XXX
 SG_ pEngine_Brake_Enabled : 12|2@1+ (1,0) [0|3] "state" Vector__XXX
 SG_ pCylDeAc_Enabled : 8|2@1+ (1,0) [0|3] "state" Vector__XXX
 SG_ pFarm_Mode_Speed_Increment : 34|2@1+ (1,0) [0|3] "state" Vector__XXX
 SG_ pCylDeAc_Active : 10|2@1+ (1,0) [0|3] "state" Vector__XXX

BO_ 2566887959 pAntiTheft_17: 8 IC
 SG_ pAntiTheft_Component_Status_Indi : 0|2@1+ (1,0) [0|3] "state" Vector__XXX
 SG_ pAntiTheft_Command_States : 2|4@1+ (1,0) [0|15] "state" Vector__XXX
 SG_ pAntiTheft_Pin_Presence : 6|2@1+ (1,0) [0|3] "state" Vector__XXX
 SG_ pAntiTheft_Pin_Parameter : 8|32@1+ (1,0) [0|4294967295] "ASCII" Vector__XXX

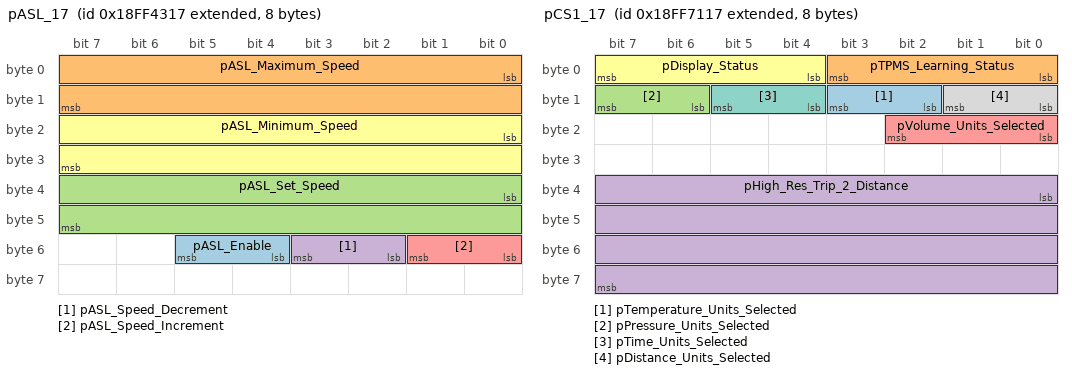
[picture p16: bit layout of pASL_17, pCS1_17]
BO_ 2566865687 pASL_17: 8 IC
 SG_ pASL_Enable : 52|2@1+ (1,0) [0|3] "state" Vector__XXX
 SG_ pASL_Maximum_Speed : 0|16@1+ (0.00390625,0) [0|255] "km/h" Vector__XXX
 SG_ pASL_Set_Speed : 32|16@1+ (0.00390625,0) [0|255] "km/h" Vector__XXX
 SG_ pASL_Speed_Decrement : 50|2@1+ (1,0) [0|3] "state" Vector__XXX
 SG_ pASL_Speed_Increment : 48|2@1+ (1,0) [0|3] "state" Vector__XXX
 SG_ pASL_Minimum_Speed : 16|16@1+ (0.00390625,0) [0|255] "km/h" Vector__XXX

BO_ 2566877463 pCS1_17: 8 IC
 SG_ pTemperature_Units_Selected : 10|2@1+ (1,0) [0|3] "state" Vector__XXX
 SG_ pTPMS_Learning_Status : 0|4@1+ (1,0) [0|15] "state" Vector__XXX
 SG_ pPressure_Units_Selected : 14|2@1+ (1,0) [0|3] "state" Vector__XXX
 SG_ pHigh_Res_Trip_2_Distance : 32|32@1+ (5,0) [0|21474836479] "km" Vector__XXX
 SG_ pVolume_Units_Selected : 16|3@1+ (1,0) [0|7] "state" Vector__XXX
 SG_ pDisplay_Status : 4|4@1+ (1,0) [0|15] "state" Vector__XXX
 SG_ pTime_Units_Selected : 12|2@1+ (1,0) [0|3] "state" Vector__XXX
 SG_ pDistance_Units_Selected : 8|2@1+ (1,0) [0|3] "state" Vector__XXX

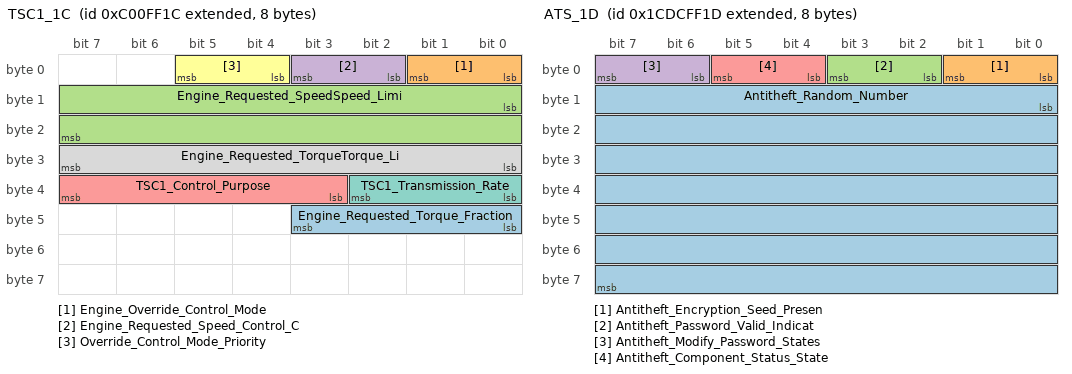
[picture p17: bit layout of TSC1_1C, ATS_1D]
BO_ 2348875548 TSC1_1C: 8 GPS
 SG_ Engine_Requested_Torque_Fraction : 40|4@1+ (0.125,0) [0|1] "%" Vector__XXX
 SG_ Engine_Override_Control_Mode : 0|2@1+ (1,0) [0|3] "bit" Vector__XXX
 SG_ Engine_Requested_SpeedSpeed_Limi : 8|16@1+ (0.125,0) [0|8191] "rpm" Vector__XXX
 SG_ Engine_Requested_Speed_Control_C : 2|2@1+ (1,0) [0|3] "bit" Vector__XXX
 SG_ TSC1_Control_Purpose : 35|5@1+ (1,0) [0|31] "bit" Vector__XXX
 SG_ Override_Control_Mode_Priority : 4|2@1+ (1,0) [0|3] "bit" Vector__XXX
 SG_ TSC1_Transmission_Rate : 32|3@1+ (1,0) [0|7] "bit" Vector__XXX
 SG_ Engine_Requested_TorqueTorque_Li : 24|8@1+ (1,-125) [-125|380] "%" Vector__XXX

BO_ 2566842396 VDS_1C: 8 GPS
 SG_ Compass_Bearing : 0|16@1+ (0.0078125,0) [0|511] "deg" Vector__XXX

BO_ 2631728925 ATS_1D: 8 WCM
 SG_ Antitheft_Random_Number : 8|56@1+ (0,0) [0|-1] "ASCII" Vector__XXX
 SG_ Antitheft_Encryption_Seed_Presen : 0|2@1+ (1,0) [0|3] "bit" Vector__XXX
 SG_ Antitheft_Password_Valid_Indicat : 2|2@1+ (1,0) [0|3] "bit" Vector__XXX
 SG_ Antitheft_Modify_Password_States : 6|2@1+ (1,0) [0|3] "bit" Vector__XXX
 SG_ Antitheft_Component_Status_State : 4|2@1+ (1,0) [0|3] "bit" Vector__XXX

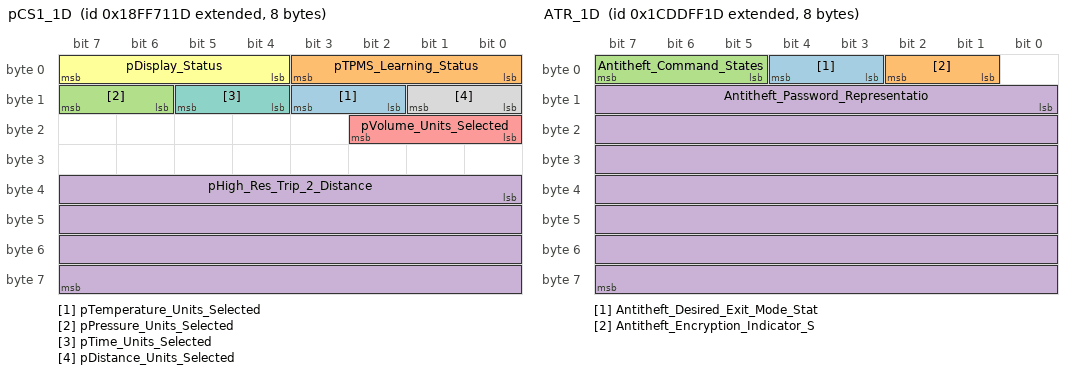
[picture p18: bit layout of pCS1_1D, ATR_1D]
BO_ 2566877469 pCS1_1D: 8 WCM
 SG_ pTemperature_Units_Selected : 10|2@1+ (1,0) [0|3] "state" Vector__XXX
 SG_ pTPMS_Learning_Status : 0|4@1+ (1,0) [0|15] "state" Vector__XXX
 SG_ pPressure_Units_Selected : 14|2@1+ (1,0) [0|3] "state" Vector__XXX
 SG_ pHigh_Res_Trip_2_Distance : 32|32@1+ (5,0) [0|21474836479] "km" Vector__XXX
 SG_ pVolume_Units_Selected : 16|3@1+ (1,0) [0|7] "state" Vector__XXX
 SG_ pDisplay_Status : 4|4@1+ (1,0) [0|15] "state" Vector__XXX
 SG_ pTime_Units_Selected : 12|2@1+ (1,0) [0|3] "state" Vector__XXX
 SG_ pDistance_Units_Selected : 8|2@1+ (1,0) [0|3] "state" Vector__XXX

BO_ 2633984541 pDSS_1D: 8 WCM
 SG_ pHeated_Grip_Enable : 48|2@1+ (1,0) [0|3] "state" Vector__XXX
 SG_ pUser_PIN_Access_Status : 26|2@1+ (1,0) [0|3] "state" Vector__XXX
 SG_ pActive_Descent_Control_ADC_Stat : 0|2@1+ (1,0) [0|3] "state" Vector__XXX
 SG_ pCruise_Control_Set_Status : 24|2@1+ (1,0) [0|3] "state" Vector__XXX
 SG_ pTether_Switch_Status : 46|2@1+ (1,0) [0|3] "state" Vector__XXX
 SG_ pHigh_Beam_Indicator_Status : 8|2@1+ (1,0) [0|3] "state" Vector__XXX
 SG_ pLow_Fuel_Indicator_Status : 10|2@1+ (1,0) [0|3] "state" Vector__XXX
 SG_ pHeated_Grips_Percentage : 16|8@1+ (0.4,0) [0|101.4] "%" Vector__XXX
 SG_ pSide_Stand_Status : 36|2@1+ (1,0) [0|3] "state" Vector__XXX
 SG_ pTurf_Mode_Requested : 28|2@1+ (1,0) [0|3] "state" Vector__XXX
 SG_ pEngine_Idle_Shutdown_Timer : 54|10@1+ (1,0) [0|1023] "state" Vector__XXX
 SG_ Operator_Not_in_Operating_Statio : 38|2@1+ (1,0) [0|3] "state" Vector__XXX
 SG_ pAWD_Mode_Requested : 32|2@1+ (1,0) [0|3] "state" Vector__XXX
 SG_ pHeated_Grips_Up_Switch_Status : 50|2@1+ (1,0) [0|3] "state" Vector__XXX
 SG_ pTreadle_Neutral_Status : 2|2@1+ (1,0) [0|3] "state" Vector__XXX
 SG_ pHeated_Grips_Down_Switch_Status : 52|2@1+ (1,0) [0|3] "state" Vector__XXX
 SG_ pPark_Brake_Indicator_Status : 40|3@1+ (1,0) [0|7] "state" Vector__XXX
 SG_ pRWD_Mode_Requested : 30|2@1+ (1,0) [0|3] "state" Vector__XXX
 SG_ pSeat_Belt_Indicator_Status : 12|3@1+ (1,0) [0|7] "state" Vector__XXX
 SG_ pSecurity_Light_Immobilizer_Stat : 6|2@1+ (1,0) [0|3] "state" Vector__XXX
 SG_ ECU_Security_Status : 43|3@1+ (1,0) [0|7] "state" Vector__XXX
 SG_ pActive_Decent_Control_ADC_Mode_ : 34|2@1+ (1,0) [0|3] "state" Vector__XXX
 SG_ pTreadle_Reverse_Status : 4|2@1+ (1,0) [0|3] "state" Vector__XXX

BO_ 2566834717 DM1_1D: 42 WCM
 SG_ Flash_Malfunction_Indicator_Lamp : 14|2@1+ (1,0) [0|3] "" Vector__XXX
 SG_ Malfunction_Indicator_Lamp_Statu : 6|2@1+ (1,0) [0|3] "" Vector__XXX
 SG_ Red_Stop_Lamp_Status : 4|2@1+ (1,0) [0|3] "" Vector__XXX
 SG_ Amber_Warning_Lamp_Status : 2|2@1+ (1,0) [0|3] "" Vector__XXX
 SG_ Flash_Red_Stop_Lamp_RSL : 12|2@1+ (1,0) [0|3] "" Vector__XXX
 SG_ Flash_Amber_Warning_Lamp_AWL : 10|2@1+ (1,0) [0|3] "" Vector__XXX
 SG_ Flash_Protect_Lamp : 8|2@1+ (1,0) [0|3] "" Vector__XXX
 SG_ Protect_Lamp_Status : 0|2@1+ (1,0) [0|3] "" Vector__XXX
 SG_ DTC_1 : 16|32@1+ (1,0) [0|4294967295] "value" Vector__XXX
 SG_ DTC_2 : 48|32@1+ (1,0) [0|4294967295] "value" Vector__XXX
 SG_ DTC_3 : 80|32@1+ (1,0) [0|4294967295] "value" Vector__XXX
 SG_ DTC_4 : 112|32@1+ (1,0) [0|4294967295] "value" Vector__XXX
 SG_ DTC_5 : 144|32@1+ (1,0) [0|4294967295] "value" Vector__XXX
 SG_ DTC_6 : 176|32@1+ (1,0) [0|4294967295] "value" Vector__XXX
 SG_ DTC_7 : 208|32@1+ (1,0) [0|4294967295] "value" Vector__XXX
 SG_ DTC_8 : 240|32@1+ (1,0) [0|4294967295] "value" Vector__XXX
 SG_ DTC_9 : 272|32@1+ (1,0) [0|4294967295] "value" Vector__XXX
 SG_ DTC_10 : 304|32@1+ (1,0) [0|4294967295] "value" Vector__XXX

BO_ 2631794461 ATR_1D: 8 WCM
 SG_ Antitheft_Desired_Exit_Mode_Stat : 3|2@1+ (1,0) [0|3] "bit" Vector__XXX
 SG_ Antitheft_Encryption_Indicator_S : 1|2@1+ (1,0) [0|3] "bit" Vector__XXX
 SG_ Antitheft_Command_States : 5|3@1+ (1,0) [0|7] "bit" Vector__XXX
 SG_ Antitheft_Password_Representatio : 8|56@1+ (0,0) [0|-1] "ASCII" Vector__XXX

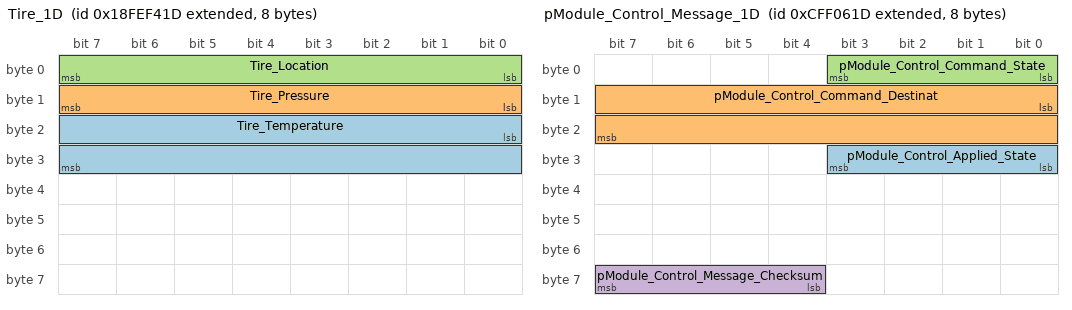
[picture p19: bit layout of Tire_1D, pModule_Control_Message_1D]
BO_ 2566845469 Tire_1D: 8 WCM
 SG_ Tire_Temperature : 16|16@1+ (0.03125,-273) [-273|2320] "deg C" Vector__XXX
 SG_ Tire_Pressure : 8|8@1+ (4,0) [0|1023] "kPa" Vector__XXX
 SG_ Tire_Location : 0|8@1+ (1,0) [0|255] "bit" Vector__XXX

BO_ 2365523485 pModule_Control_Message_1D: 8 WCM
 SG_ pModule_Control_Applied_State : 24|4@1+ (1,0) [0|15] "state" Vector__XXX
 SG_ pModule_Control_Command_Destinat : 8|16@1+ (1,0) [0|65535] "count" Vector__XXX
 SG_ pModule_Control_Command_State : 0|4@1+ (1,0) [0|15] "state" Vector__XXX
 SG_ pModule_Control_Message_Checksum : 60|4@1+ (1,0) [0|15] "bit" Vector__XXX

BO_ 2566834973 DM2_1D: 42 WCM
 SG_ Protect_Lamp_Status : 0|2@1+ (1,0) [0|3] "" Vector__XXX
 SG_ Amber_Warning_Lamp_Status : 2|2@1+ (1,0) [0|3] "" Vector__XXX
 SG_ Red_Stop_Lamp_Status : 4|2@1+ (1,0) [0|3] "" Vector__XXX
 SG_ Malfunction_Indicator_Lamp_Statu : 6|2@1+ (1,0) [0|3] "" Vector__XXX
 SG_ Flash_Protect_Lamp : 8|2@1+ (1,0) [0|3] "" Vector__XXX
 SG_ Flash_Amber_Warning_Lamp_AWL : 10|2@1+ (1,0) [0|3] "" Vector__XXX
 SG_ Flash_Red_Stop_Lamp_RSL : 12|2@1+ (1,0) [0|3] "" Vector__XXX
 SG_ Flash_Malfunction_Indicator_Lamp : 14|2@1+ (1,0) [0|3] "" Vector__XXX
 SG_ DTC_1 : 16|32@1+ (1,0) [0|4294967295] "value" Vector__XXX
 SG_ DTC_2 : 48|32@1+ (1,0) [0|4294967295] "value" Vector__XXX
 SG_ DTC_3 : 80|32@1+ (1,0) [0|4294967295] "value" Vector__XXX
 SG_ DTC_4 : 112|32@1+ (1,0) [0|4294967295] "value" Vector__XXX
 SG_ DTC_5 : 144|32@1+ (1,0) [0|4294967295] "value" Vector__XXX
 SG_ DTC_6 : 176|32@1+ (1,0) [0|4294967295] "value" Vector__XXX
 SG_ DTC_7 : 208|32@1+ (1,0) [0|4294967295] "value" Vector__XXX
 SG_ DTC_8 : 240|32@1+ (1,0) [0|4294967295] "value" Vector__XXX
 SG_ DTC_9 : 272|32@1+ (1,0) [0|4294967295] "value" Vector__XXX
 SG_ DTC_10 : 304|32@1+ (1,0) [0|4294967295] "value" Vector__XXX

BO_ 2432656669 pOSS1_1D: 8 WCM
 SG_ Key_Fob_Unlock_Button_Status : 30|2@1+ (1,0) [0|3] "state" Vector__XXX
 SG_ Homelink_2 : 44|2@1+ (1,0) [0|3] "state" Vector__XXX
 SG_ Side_Stand_Switch : 56|2@1+ (1,0) [0|3] "state" Vector__XXX
 SG_ Key_Fob_Lock_Button_Status : 32|2@1+ (1,0) [0|3] "state" Vector__XXX
 SG_ Windshield__2_Down : 50|2@1+ (1,0) [0|3] "state" Vector__XXX
 SG_ Turn__3_Cancel : 14|2@1+ (1,0) [0|3] "state" Vector__XXX
 SG_ Reverse : 40|2@1+ (1,0) [0|3] "state" Vector__XXX
 SG_ Hazard : 16|2@1+ (1,0) [0|3] "state" Vector__XXX
 SG_ Homelink_1 : 42|2@1+ (1,0) [0|3] "state" Vector__XXX
 SG_ Windshield__1_Up : 48|2@1+ (1,0) [0|3] "state" Vector__XXX
 SG_ Front_Brake_Switch : 52|2@1+ (1,0) [0|3] "state" Vector__XXX
 SG_ Instrument_Cluster_Control__2 : 2|2@1+ (1,0) [0|3] "state" Vector__XXX
 SG_ Chassis_Unlock_Button_Status : 34|2@1+ (1,0) [0|3] "state" Vector__XXX
 SG_ Power_Button : 58|2@1+ (1,0) [0|3] "state" Vector__XXX
 SG_ RunStop_Switch : 38|2@1+ (1,0) [0|3] "state" Vector__XXX
 SG_ Headlamp__2_High : 6|2@1+ (1,0) [0|3] "state" Vector__XXX
 SG_ Instrument_Cluster_Control__1 : 0|2@1+ (1,0) [0|3] "state" Vector__XXX
 SG_ Clutch_Switch : 54|2@1+ (1,0) [0|3] "state" Vector__XXX
 SG_ Start : 26|2@1+ (1,0) [0|3] "state" Vector__XXX
 SG_ Headlamp__3_Driving : 8|2@1+ (1,0) [0|3] "state" Vector__XXX
 SG_ Cruise__2_Set : 20|2@1+ (1,0) [0|3] "state" Vector__XXX
 SG_ Windshield_Wiper : 36|2@1+ (1,0) [0|3] "state" Vector__XXX
 SG_ Fog : 28|2@1+ (1,0) [0|3] "state" Vector__XXX
 SG_ Cruise__3_Accel : 22|2@1+ (1,0) [0|3] "state" Vector__XXX
 SG_ Horn : 24|2@1+ (1,0) [0|3] "state" Vector__XXX
 SG_ Turn__2_Right : 12|2@1+ (1,0) [0|3] "state" Vector__XXX
 SG_ Cruise__1_On : 18|2@1+ (1,0) [0|3] "state" Vector__XXX
 SG_ Turn__1_Left : 10|2@1+ (1,0) [0|3] "state" Vector__XXX
 SG_ Throttle_Safety_Switch__1 : 46|2@1+ (1,0) [0|3] "state" Vector__XXX
 SG_ Headlamp__1_Low : 4|2@1+ (1,0) [0|3] "state" Vector__XXX
 SG_ Chassis_Lock_Switch_Status : 62|2@1+ (1,0) [0|3] "unknown" Vector__XXX
 SG_ Fuel_Door_Unlock_Button_Status : 60|2@1+ (1,0) [0|3] "state" Vector__XXX

CM_ BO_ 2566884352 "Name: Torque Data
Description: Parsed from -014. ";
CM_ SG_ 2566884352 Message_Checksum "Description:The message checksum is used to verify the signal path from the transmitting device to the receiving device. The message checksum is calculated using the first 7 data bytes, the message counter and the bytes of the message id";
CM_ SG_ 2566884352 pEstimated_Torque "Description: Estimated torque value based on current engine conditions.
Could not parse SPN data type, please add:Type: Measured
Parsed from -014. ";
CM_ SG_ 2566884352 pCurrent_RPM_Rated_Torque "Description: Contains the rated torque for the current RPM (un-throttled and optimal spark).
Could not parse SPN data type, please add:Type: Measured
Parsed from -014. ";
CM_ SG_ 2566884352 Brake_Switch "Description:Switch signal which indicates that the driver operated brake foot pedal is being pressed. This brake foot pedal is controlling the vehicles' service brake (total vehicle braking application, not park brakes). It is necessary for ";
CM_ SG_ 2566884352 Message_Counter "Description:The message counter is used to detect situations where the transmitting ECU malfunction repeats the same frame all the time. The receiver of the information may use the counter parameter to detect this situation. The transmitt";
CM_ BO_ 2566876928 "Name: pEngine Requests 1
Description: Parsed from -014. ";
CM_ SG_ 2566876928 pSecondary_Air_Valve_Control "Description: ";
CM_ BO_ 2566886400 "Name: Log Data
Description: Parsed from -014. ";
CM_ SG_ 2566886400 Engine_Cylinder_1_Ignition_Timin "Description: Target ignition timing for cylinder 1.
Could not parse offset, please add:Offset: -128 deg
Could not parse SPN data type, please add:Type: Measured
Parsed from -014. ";
CM_ SG_ 2566886400 Engine_Cylinder_2_Ignition_Timin "Description: Target ignition timing for cylinder 2.
Could not parse offset, please add:Offset: -128 deg
Could not parse SPN data type, please add:Type: Measured
Parsed from -014. ";
CM_ SG_ 2566886400 High_Range_Engine_Percent_Load "Description: Percent engine load but with a range high enough to support boosted applications.
Could not parse SPN data type, please add:Type: Measured
Parsed from -014. ";
CM_ SG_ 2566886400 Desired_Lambda "Description: The target lambda value.
Could not parse SPN data type, please add:Type: Calculated
Parsed from -014. ";
CM_ BO_ 2566886912 "Name: pFleet Management
Description: Parsed from -014. ";
CM_ SG_ 2566886912 pBoundary_Status_Message "Description: Used to communicate information about boundary proximity ";
CM_ SG_ 2566886912 pVehicle_EnableDisable "Description: Used to command vehicle states; i.e. vehicle enabled or disabled. ";
CM_ SG_ 2566886912 pFleet_Management_Default_Vehicl "Description: This contains information as to what the default state of the vehicle will be before a vehicle command is received from the Fleet Management device or in the event of a communication error from the Fleet Mana";
CM_ SG_ 2566886912 pUser_Authentication_Status "Description: Used to indicate user authentication status ";
CM_ BO_ 2566887936 "Name: pAntiTheft
Description: Parsed from -014. ";
CM_ SG_ 2566887936 pAntiTheft_Component_Status_Indi "Description: This state signal is included in the lower functionality proprietary Anti-Theft implementation. The product team&rsquo;s specification did not line up with the J1939 standard Anti-Theft messages, nor the alre";
CM_ SG_ 2566887936 pAntiTheft_Command_States "Description: This command signal is included in the lower functionality proprietary Anti-Theft implementation. The product team&rsquo;s specification did not line up with the J1939 standard Anti-Theft messages, nor the already n";
CM_ SG_ 2566887936 pAntiTheft_Pin_Presence "Description: 
This parameter is used to indicate if a pin is being provided or requested to the component. ";
CM_ SG_ 2566887936 pAntiTheft_Pin_Parameter "Description: 
A four byte numeric code used to represent the user pin in response to a pin request or on pin change. This parameter is sent as a numeric value utilizing the full range of 0 to 0xFFFFFFFF. The most significant byt";
CM_ BO_ 2348941056 "Name: Transmission Control 1
Description: Parsed from -014. ";
CM_ SG_ 2348941056 Transmission_Mode_3 "Description:Indicates whether transmission mode 3 is enabled. Modes are manufacturer specific and are not necessarily mutually exclusive. See also SPN 2538. 00b = Disable 01b = Enable 10b = Reserved 11b = Take no action
Note: Parsed ";
CM_ SG_ 2348941056 Transmission_Requested_Gear "Description:Gear requested by the operator, ABS, or engine. Negative values are reverse gears, positive values are forward gears, zero is neutral, parameter specific indicators are listed below. Parameter specific values for t";
CM_ SG_ 2348941056 Transmission_Mode_1 "Description:Indicates whether transmission mode 1 is enabled. Modes are manufacturer specific and are not necessarily mutually exclusive. See also SPN 2536. 00b = Disable 01b = Enable 10b = Reserved 11b = Take no action
Note: Parsed ";
CM_ SG_ 2348941056 Transmission_Mode_2 "Description:Indicates whether transmission mode 2 is enabled. Modes are manufacturer specific and are not necessarily mutually exclusive. See also SPN 2537. 00b = Disable 01b = Enable 10b = Reserved 11b = Take no action
Note: Parsed ";
CM_ SG_ 2348941056 Requested_Percent_Clutch_Slip "Description:Parameter which represents the percent clutch slip requested by a device.
Note: Parsed from J1939DA.";
CM_ SG_ 2348941056 Transmission_Gear_Shift_Inhibit_ "Description:Command signal to inhibit gear shifts. 00b = Gear shifts are allowed (disable function) 01b = Gear shifts are inhibited (enable function) 10b = Reserved 11b = Take no action (leave function as is)
Note: Parse";
CM_ SG_ 2348941056 Transmission_Shift_Selector_Disp "Description:Status of the operator's switch used to 'toggle' through multiple display modes of a shift selector display. When a shift selector display is capable of displaying more than just range information, this switch";
CM_ SG_ 2348941056 Disengage_Differential_Lock_Requ "Description:Command signal used to disengage the various differential locks, e.g., to allow an undistributed individual wheel control by ABS. The differential locks are located as defined in Figure SPN564_A. 00b = Engage ";
CM_ SG_ 2348941056 Disengage_Differential_Lock_Requ "Description:Command signal used to disengage the various differential locks, e.g., to allow an undistributed individual wheel control by ABS. The differential locks are located as defined in Figure SPN564_A. 00b = Engage ";
CM_ SG_ 2348941056 Disengage_Differential_Lock_Requ "Description:Command signal used to disengage the various differential locks, e.g., to allow an undistributed individual wheel control by ABS. The differential locks are located as defined in Figure SPN564_A. 00b = Engage ";
CM_ SG_ 2348941056 Transmission_Torque_Converter_Lo "Description:Command signal to override normal transmission control of the torque converter lockup clutch. This command may be used to control lockup as needed for different operating modes or environmental conditions. For";
CM_ SG_ 2348941056 Transmission_Mode_4 "Description:Indicates whether transmission mode 4 is enabled. Modes are manufacturer specific and are not necessarily mutually exclusive. See also SPN 2539. 00b = Disable 01b = Enable 10b = Reserved 11b = Take no action
Note: Parsed ";
CM_ SG_ 2348941056 Disengage_Driveline_Request "Description:Command signal used to simply disengage the driveline, e.g., to prevent engine drag torque from causing high wheel slip on slippery surfaces. 00b = Allow driveline engagement 01b = Disengage driveline 10b = Reserve";
CM_ SG_ 2348941056 pTransmission_Mode_5_Request "Description: Indicates whether transmission mode 5 is to be enabled. Modes are manufacturer specific and not necessarily mutually exclusive. See also SPN 523997. ";
CM_ BO_ 2365530112 "Name: pTorque/Speed Control
Description: Used to request/limit torque and speed of an engine or motor. To be used with PGN 65313 and PGN 65314.
Parsed from -014. ";
CM_ SG_ 2365530112 pMessage_Counter "Description: Message counter that increments by one for each transmission from 0 to 15 and then rolls over.
Could not parse SPN data type, please add:Type: Status
Parsed from -014. ";
CM_ SG_ 2365530112 pRequested_Engine_TorqueTorque_L "Description: This is the value used when the pEngine Control Mode is in a torque request or limit mode. This value shall be ignored by the controller when pEngine Control Mode is set to No Control Request, Engine Speed Re";
CM_ SG_ 2365530112 pEngine_Control_Mode "Description: Used to tell the engine or motor controller the type of torque/speed request or limit to use. ";
CM_ SG_ 2365530112 pRequested_Engine_SpeedSpeed_Lim "Description: This is the value used when the pEngine Control Mode is in a speed request or limit mode. This value shall be ignored by the controller when pEngine Control Mode is set to No Control Request, Engine Torque Re";
CM_ SG_ 2365530112 WheelBased_Vehicle_Speed "Description:Speed of the vehicle as calculated from wheel or tailshaft speed.
Note: Parsed from J1939DA.";
CM_ SG_ 2365530112 pEngine_Control_Requestor "Description: Used to tell the engine or motor controller what function is the requestor of the torque/speed request or limit. ";
CM_ SG_ 2365530112 pMessage_Checksum "Description: Message checksum that is calculated as follows:
Intermediate Checksum =
Byte1 + Byte2 + Byte3 + Byte4 + Byte5 + Byte6 + Byte7 + (Message Counter & 0x0F) + Message ID Low Byte + Message ID Mid Low Byte + Message ID Mid Hig";
CM_ BO_ 2365532416 "Name: pTransmission Engine Interface
Description: Used to transmit request to ECM due to TCM errors and sfatey critical events.
Parsed from -014. ";
CM_ SG_ 2365532416 pMessageCounter "Description: Used to verify the signal path from Transmitter up to the Application Software layer of the Receiver.
Transmitter increments the count for every message transmission, automatically rolling over at 15.
Could not parse offset";
CM_ SG_ 2365532416 pAMTPumpStatus "Description: Used to send hydraulic pump status from AMT system. ";
CM_ SG_ 2365532416 pMessageChecksum "Description: Used to verify the signal path from Transmitter up to the Application Software layer of the Receiver.
Calculated using the CRC8 0xEA Polynomial formula. Data used in calculation is [Message ID][Data Bytes 1-7].
Could not p";
CM_ SG_ 2365532416 pEngine_Control_Shutdown_Request "Description: Used to send engine shutdown request with reducing speed from AMT system. ";
CM_ SG_ 2365532416 pAMTHydraulicPressure "Description: Used to send hydraulic pump pressure from AMT system.
Could not parse SPN data type, please add:Type: Calculated
Parsed from -014. ";
CM_ SG_ 2365532416 pAMTClutchStatus "Description: Used to send electronic clutch status from AMT system. ";
CM_ BO_ 2348941061 "Name: Transmission Control 1
Description: Parsed from -014. ";
CM_ SG_ 2348941061 Transmission_Mode_3 "Description:Indicates whether transmission mode 3 is enabled. Modes are manufacturer specific and are not necessarily mutually exclusive. See also SPN 2538. 00b = Disable 01b = Enable 10b = Reserved 11b = Take no action
Note: Parsed ";
CM_ SG_ 2348941061 Transmission_Requested_Gear "Description:Gear requested by the operator, ABS, or engine. Negative values are reverse gears, positive values are forward gears, zero is neutral, parameter specific indicators are listed below. Parameter specific values for t";
CM_ SG_ 2348941061 Transmission_Mode_1 "Description:Indicates whether transmission mode 1 is enabled. Modes are manufacturer specific and are not necessarily mutually exclusive. See also SPN 2536. 00b = Disable 01b = Enable 10b = Reserved 11b = Take no action
Note: Parsed ";
CM_ SG_ 2348941061 Transmission_Mode_2 "Description:Indicates whether transmission mode 2 is enabled. Modes are manufacturer specific and are not necessarily mutually exclusive. See also SPN 2537. 00b = Disable 01b = Enable 10b = Reserved 11b = Take no action
Note: Parsed ";
CM_ SG_ 2348941061 Requested_Percent_Clutch_Slip "Description:Parameter which represents the percent clutch slip requested by a device.
Note: Parsed from J1939DA.";
CM_ SG_ 2348941061 Transmission_Gear_Shift_Inhibit_ "Description:Command signal to inhibit gear shifts. 00b = Gear shifts are allowed (disable function) 01b = Gear shifts are inhibited (enable function) 10b = Reserved 11b = Take no action (leave function as is)
Note: Parse";
CM_ SG_ 2348941061 Transmission_Shift_Selector_Disp "Description:Status of the operator's switch used to 'toggle' through multiple display modes of a shift selector display. When a shift selector display is capable of displaying more than just range information, this switch";
CM_ SG_ 2348941061 Disengage_Differential_Lock_Requ "Description:Command signal used to disengage the various differential locks, e.g., to allow an undistributed individual wheel control by ABS. The differential locks are located as defined in Figure SPN564_A. 00b = Engage ";
CM_ SG_ 2348941061 Disengage_Differential_Lock_Requ "Description:Command signal used to disengage the various differential locks, e.g., to allow an undistributed individual wheel control by ABS. The differential locks are located as defined in Figure SPN564_A. 00b = Engage ";
CM_ SG_ 2348941061 Disengage_Differential_Lock_Requ "Description:Command signal used to disengage the various differential locks, e.g., to allow an undistributed individual wheel control by ABS. The differential locks are located as defined in Figure SPN564_A. 00b = Engage ";
CM_ SG_ 2348941061 Transmission_Torque_Converter_Lo "Description:Command signal to override normal transmission control of the torque converter lockup clutch. This command may be used to control lockup as needed for different operating modes or environmental conditions. For";
CM_ SG_ 2348941061 Transmission_Mode_4 "Description:Indicates whether transmission mode 4 is enabled. Modes are manufacturer specific and are not necessarily mutually exclusive. See also SPN 2539. 00b = Disable 01b = Enable 10b = Reserved 11b = Take no action
Note: Parsed ";
CM_ SG_ 2348941061 Disengage_Driveline_Request "Description:Command signal used to simply disengage the driveline, e.g., to prevent engine drag torque from causing high wheel slip on slippery surfaces. 00b = Allow driveline engagement 01b = Disengage driveline 10b = Reserve";
CM_ SG_ 2348941061 pTransmission_Mode_5_Request "Description: Indicates whether transmission mode 5 is to be enabled. Modes are manufacturer specific and not necessarily mutually exclusive. See also SPN 523997. ";
CM_ BO_ 2348875531 "Name: Torque/Speed Control 1
Description: Parsed from -014. ";
CM_ SG_ 2348875531 Engine_Requested_Torque_Fraction "Description:This parameter displays an additional torque in percent of the reference engine torque. When the MSB is set to 1, this parameter is not available. When the MSB is set to 0, bits 1 to 3 indicate the desired tor";
CM_ SG_ 2348875531 Engine_Override_Control_Mode "Description:The override control mode defines which sort of command is used: 00b = Override disabled - Disable any existing control commanded by the source of this command. 01b = Speed control - Govern speed to the included d";
CM_ SG_ 2348875531 Engine_Requested_SpeedSpeed_Limi "Description:Parameter provided to the engine from external sources in the torque/speed control message. This is the engine speed which the engine is expected to operate at if the speed control mode is active or the engine";
CM_ SG_ 2348875531 Engine_Requested_Speed_Control_C "Description:This mode tells the engine control system the governor characteristics that are desired during speed control. The four characteristics defined are: 00b = Transient Optimized for driveline disengaged and non-lo";
CM_ SG_ 2348875531 TSC1_Control_Purpose "Description:State signal which indicates which control mode the sending device is using to generate the TSC1 command. Note that the modes are not in prioritized order. Not all modes may be relevant for a given device. Some devices ma";
CM_ SG_ 2348875531 Override_Control_Mode_Priority "Description:This field is used as an input to the engine or retarder to determine the priority of the Override Control Mode received in the Torque/Speed Control message (see PGN 0). The default is 11b (Low priority). It is ";
CM_ SG_ 2348875531 TSC1_Transmission_Rate "Description:This parameter indicates the transmission rate at which the sending device will transmit the TSC1 message. The engine shall adjust its timeout for TSC1 messages accordingly. Variable TSC1 transmission rates shall only a";
CM_ SG_ 2348875531 Engine_Requested_TorqueTorque_Li "Description:Parameter provided to the engine or retarder in the torque/speed control message for controlling or limiting the output torque. Requested torque to the engine is measured in indicated torque as a percentage of";
CM_ BO_ 2365449739 "Name: Hydraulic Braking System
Description: Parsed from -014. ";
CM_ SG_ 2365449739 Hydraulic_Brake_Pressure_Warning "Description:Signal which indicates whether the hydraulic brake pressure of circuit 2 is below the warning level 00b = Pressure level sufficient 01b = Pressure level below warning level 10b = Error indicator 11b = Not avai";
CM_ SG_ 2365449739 Hydraulic_Brake_Pressure_Supply_ "Description:Signal which indicates whether the hydraulic brake pressure supply of circuit 2 is reliable; that is, able to support continued braking. 00b = Supply is not reliable 01b = Supply is reliable 10b = Error indica";
CM_ SG_ 2365449739 Hydraulic_Brake_Pressure_Supply_ "Description:Signal which indicates whether the hydraulic brake pressure supply of circuit 1 is reliable; that is, able to support continued braking. 00b = Supply is not reliable 01b = Supply is reliable 10b = Error indica";
CM_ SG_ 2365449739 Hydraulic_Brake_Pressure_Warning "Description:Signal which indicates whether the hydraulic brake pressure of circuit 1 is below the warning level 00b = Pressure level sufficient 01b = Pressure level below warning level 10b = Error indicator 11b = Not avai";
CM_ SG_ 2365449739 Hydraulic_Brake_Pressure_Circuit "Description:Gage hydraulic pressure in circuit 1 of the hydraulic brake system
Note: Parsed from J1939DA.";
CM_ SG_ 2365449739 Hydraulic_Brake_Pressure_Circuit "Description:Gage hydraulic pressure in circuit 2 of the hydraulic brake system
Note: Parsed from J1939DA.";
CM_ SG_ 2365449739 Hydraulic_Brake_Fluid_Level_Swit "Description:Signal which indicates whether the hydraulic fluid level in the reservoir(s) is sufficient. 00b = Fluid level is not sufficient 01b = Fluid level is sufficient 10b = Error indicator 11b = Not available
Note: ";
CM_ BO_ 2565867787 "Name: Vehicle Dynamic Stability Control
Description: Parsed from -014. ";
CM_ SG_ 2565867787 Lateral_Acceleration "Description:Indicates a lateral acceleration of the vehicle (the component of vehicle acceleration vector along the Y-axis). A positive lateral acceleration signal results when the vehicle is accelerated to the left. This parameter i";
CM_ SG_ 2565867787 Longitudinal_Acceleration "Description:Indicates the longitudinal acceleration of the vehicle. A positive longitudinal acceleration signal results when the vehicle speed increases, regardless of driving the vehicle forward or backward. This parameter is a";
CM_ SG_ 2565867787 Yaw_Rate "Description:Indicates the rate of rotation about the vertical axis (i.e. the z-axis). A positive yaw rate signal results when the vehicle turns counter-clockwise. This parameter is defined according to a Z-Up axis system and the sign of the valu";
CM_ SG_ 2565867787 Steering_Wheel_Angle "Description:The main operator`s steering wheel angle (on the steering column, not the actual wheel angle). The vehicle being steered to the left (counterclockwise) results in a positive steering wheel angle. This is the yaw angle of ";
CM_ SG_ 2565867787 Steering_Wheel_Angle_Sensor_Type "Description:Indicates whether the steering wheel angle sensor is capable of absolute measuring of the number of steering wheel turns or not (relative measuring to position at ignition on). 00b = Relative measuring princip";
CM_ SG_ 2565867787 Steering_Wheel_Turn_Counter "Description:Indicates number of steering wheel turns, absolute position or relative position at ignition on. Positive values indicate left turns.
Note: Parsed from J1939DA.";
CM_ BO_ 2349465355 "Name: Static Roll Angle Sensor Information
Description: Parsed from -014. ";
CM_ SG_ 2349465355 Static_Roll_Angle "Description:The measured static roll angle between the vehicle y-axis and the ground plane about the X-axis. The sign of the roll angle is determined in accordance to the right-hand rule about the X-axis, as specified in SAE J670. Roll ";
CM_ BO_ 2565865739 "Name: Electronics Brake Controller 1
Description: Parsed from -014. ";
CM_ SG_ 2565865739 ABS_Offroad_Switch "Description:Switch signal which indicates the position of the ABS off-road switch. 00b = ABS off-road switch passive 01b = ABS off-road switch active 10b = Error 11b = Not available
Note: Parsed from J1939DA.";
CM_ SG_ 2565865739 ABSEBS_Amber_Warning_Signal_Powe "Description:This parameter commands the ABS/EBS amber/yellow optical warning signal 00b = Off 01b = On 10b = Reserved 11b = Take no action
Note: Parsed from J1939DA.";
CM_ SG_ 2565865739 ASR_Brake_Control_Active "Description:State signal which indicates that ASR brake control is active. Active means that ASR actually controls wheel brake pressure at one or more wheels of the driven axle(s). 00b = ASR brake control passive but installed 01";
CM_ SG_ 2565865739 Source_Address_of_Controlling_De "Description:The source address of the SAE J1939 device currently controlling the brake system. Its value may be the source address of the ECU transmitting the message (which means that no external SAE J1939 message is pro";
CM_ SG_ 2565865739 EBS_Red_Warning_Signal "Description:This parameter commands the EBS red optical warning signal 00b = Off 01b = On 10b = Reserved 11b = Take no action
Note: Parsed from J1939DA.";
CM_ SG_ 2565865739 ASR_Engine_Control_Active "Description:State signal which indicates that ASR engine control has been commanded to be active. Active means that ASR actually tries to control the engine. This state signal is independent of other control commands to the engi";
CM_ SG_ 2565865739 AntiLock_Braking_ABS_Active "Description:State signal which indicates that the ABS is active. The signal is set active when wheel brake pressure actually starts to be modulated by ABS and is reset to passive when all wheels are in a stable condition for a";
CM_ SG_ 2565865739 ATCASR_Information_Signal "Description:This parameter commands the ATC/ASR driver information signal, for example a dash lamp. 00b = Off 01b = On 10b = Reserved 11b = Take no action
Note: Parsed from J1939DA.";
CM_ SG_ 2565865739 ABS_Fully_Operational "Description:Signal which indicates whether an ABS system is fully operational or whether its functionality is reduced by a defect or by an intended action (e.g., by activation of an ABS-off-road switch or during special diagnostic p";
CM_ SG_ 2565865739 Traction_Control_Override_Switch "Description:Switch signal which indicates the position of the traction control override switch. The traction control override signal disables the automatic traction control function allowing the wheels to spin. 00b = Off ";
CM_ BO_ 2566803211 "Name: Vehicle Dynamic Stability Control 1
Description: Parsed from -014. ";
CM_ SG_ 2566803211 ROP_Engine_Control_active "Description:State Signal which indicates that the Roll Over Prevention (ROP) has commanded engine control to be active. Within the physical limits, ROP attempts to prevent rolling over of the vehicle. Active means that ROP actua";
CM_ SG_ 2566803211 VDC_brake_light_request "Description:Indicates whether VDC requests to turn the vehicle brake lights on 00b = Turn brake light not on 01b = Turn brake light on 10b = Reserved 11b = Don't care/Take no action
Note: Parsed from J1939DA.";
CM_ SG_ 2566803211 YC_Brake_Control_active "Description:State signal which indicates that Yaw Control (YC) has activated brake control. Active means that YC actually controls wheel brake pressure at one or more wheels of the vehicle or vehicle combination. Within the physic";
CM_ SG_ 2566803211 VDC_Information_Signal "Description:This parameter commands the VDC information signal, for example a dash lamp. 00b = Off 01b = On 10b = Reserved 11b = Don't care/Take no action
Note: Parsed from J1939DA.";
CM_ SG_ 2566803211 ROP_Brake_Control_active "Description:State signal which indicates that Roll over Prevention (ROP) has activated brake control. Active means that ROP actually controls wheel brake pressure at one or more wheels of the vehicle or vehicle combination. Withi";
CM_ SG_ 2566803211 VDC_Fully_Operational "Description:Signal that indicates whether VDC is fully operational or whether its functionality is reduced by a permanent or temporary (e.g. low voltage) defect, by intended action (e.g. disabled by a switch or during special diagno";
CM_ BO_ 2566834955 "Name: Previously Active Diagnostic Trouble Codes
Description:When supported, DM2 provides a list of all previously active (previously detected) DTCs. The list of DTCs must include
all the emissions-related previously active DTCs provided in the device’";
CM_ SG_ 2566834955 Protect_Lamp_Status "Description:Used to relay trouble code information that is reporting a problem with a vehicle system that is most probably not electronic subsystem related. For instance, engine coolant temperature is exceeding its prescribed temperat";
CM_ SG_ 2566834955 Amber_Warning_Lamp_Status "Description:Used to relay trouble code information that is reporting a problem with the vehicle system but the vehicle need not be immediately stopped.
See J1939-71 for complete reference

Parsed from -014.";
CM_ SG_ 2566834955 Red_Stop_Lamp_Status "Description:Used to relay trouble code information that is of a severe enough condition that it warrants stopping the vehicle.
See J1939-71 for complete reference

Parsed from -014.";
CM_ SG_ 2566834955 Malfunction_Indicator_Lamp_Statu "Description:Used to relay only emissions-related trouble code information. This lamp is only illuminated when there is an emission-related trouble code active.
See J1939-71 for complete reference

Parsed from -014.";
CM_ SG_ 2566834955 Flash_Protect_Lamp "Description:This parameter provides the capability to flash the protect lamp. 
See J1939-73 for complete reference
Parsed from -014.";
CM_ SG_ 2566834955 Flash_Amber_Warning_Lamp_AWL "Description:This parameter provides the capability to flash the AWL. 
See J1939-73 for complete reference
Parsed from -014.";
CM_ SG_ 2566834955 Flash_Red_Stop_Lamp_RSL "Description:This parameter provides the capability to flash the RSL.
See J1939-73 for complete reference
Parsed from -014.";
CM_ SG_ 2566834955 Flash_Malfunction_Indicator_Lamp "Description:This parameter provides the capability to flash the MIL. For OBD systems which are required to flash the SPN for specific malfunctions shall use the “slow flash” rate. 
See J1939-73 for complete reference
Pa";
CM_ SG_ 2566834955 DTC_1 "Description:This signal is a combination of 4 SPNs. To decode this signal, navigate to MCS tools.
Byte: 1 bits 8-1 SPN, 8 least significant bits of SPN (most significant at bit 8, SPN 1214)
Byte: 2 bits 8-1 SPN, second byte of SPN (most significa";
CM_ SG_ 2566834955 DTC_2 "Description:This signal is a combination of 4 SPNs. To decode this signal, navigate to MCS tools.
Byte: 1 bits 8-1 SPN, 8 least significant bits of SPN (most significant at bit 8, SPN 1214)
Byte: 2 bits 8-1 SPN, second byte of SPN (most significa";
CM_ SG_ 2566834955 DTC_3 "Description:This signal is a combination of 4 SPNs. To decode this signal, navigate to MCS tools.
Byte: 1 bits 8-1 SPN, 8 least significant bits of SPN (most significant at bit 8, SPN 1214)
Byte: 2 bits 8-1 SPN, second byte of SPN (most significa";
CM_ SG_ 2566834955 DTC_4 "Description:This signal is a combination of 4 SPNs. To decode this signal, navigate to MCS tools.
Byte: 1 bits 8-1 SPN, 8 least significant bits of SPN (most significant at bit 8, SPN 1214)
Byte: 2 bits 8-1 SPN, second byte of SPN (most significa";
CM_ SG_ 2566834955 DTC_5 "Description:This signal is a combination of 4 SPNs. To decode this signal, navigate to MCS tools.
Byte: 1 bits 8-1 SPN, 8 least significant bits of SPN (most significant at bit 8, SPN 1214)
Byte: 2 bits 8-1 SPN, second byte of SPN (most significa";
CM_ SG_ 2566834955 DTC_6 "Description:This signal is a combination of 4 SPNs. To decode this signal, navigate to MCS tools.
Byte: 1 bits 8-1 SPN, 8 least significant bits of SPN (most significant at bit 8, SPN 1214)
Byte: 2 bits 8-1 SPN, second byte of SPN (most significa";
CM_ SG_ 2566834955 DTC_7 "Description:This signal is a combination of 4 SPNs. To decode this signal, navigate to MCS tools.
Byte: 1 bits 8-1 SPN, 8 least significant bits of SPN (most significant at bit 8, SPN 1214)
Byte: 2 bits 8-1 SPN, second byte of SPN (most significa";
CM_ SG_ 2566834955 DTC_8 "Description:This signal is a combination of 4 SPNs. To decode this signal, navigate to MCS tools.
Byte: 1 bits 8-1 SPN, 8 least significant bits of SPN (most significant at bit 8, SPN 1214)
Byte: 2 bits 8-1 SPN, second byte of SPN (most significa";
CM_ SG_ 2566834955 DTC_9 "Description:This signal is a combination of 4 SPNs. To decode this signal, navigate to MCS tools.
Byte: 1 bits 8-1 SPN, 8 least significant bits of SPN (most significant at bit 8, SPN 1214)
Byte: 2 bits 8-1 SPN, second byte of SPN (most significa";
CM_ SG_ 2566834955 DTC_10 "Description:This signal is a combination of 4 SPNs. To decode this signal, navigate to MCS tools.
Byte: 1 bits 8-1 SPN, 8 least significant bits of SPN (most significant at bit 8, SPN 1214)
Byte: 2 bits 8-1 SPN, second byte of SPN (most signific";
CM_ BO_ 2566834699 "Name: Active Diagnostic Trouble Codes
Description:DM1 provides diagnostic lamp status and Diagnostic Trouble Codes (DTCs). Together, the lamp and DTC information
convey the diagnostic condition of the transmitting electronic component to other componen";
CM_ SG_ 2566834699 Flash_Malfunction_Indicator_Lamp "Description:This parameter provides the capability to flash the MIL. For OBD systems which are required to flash the SPN for specific malfunctions shall use the “slow flash” rate. 
See J1939-73 for complete reference
Pa";
CM_ SG_ 2566834699 Malfunction_Indicator_Lamp_Statu "Description:Used to relay only emissions-related trouble code information. This lamp is only illuminated when there is an emission-related trouble code active.
See J1939-71 for complete reference

Parsed from -014.";
CM_ SG_ 2566834699 Red_Stop_Lamp_Status "Description:Used to relay trouble code information that is of a severe enough condition that it warrants stopping the vehicle.
See J1939-71 for complete reference

Parsed from -014.";
CM_ SG_ 2566834699 Amber_Warning_Lamp_Status "Description:Used to relay trouble code information that is reporting a problem with the vehicle system but the vehicle need not be immediately stopped.
See J1939-71 for complete reference

Parsed from -014.";
CM_ SG_ 2566834699 Flash_Red_Stop_Lamp_RSL "Description:This parameter provides the capability to flash the RSL.
See J1939-73 for complete reference
Parsed from -014.";
CM_ SG_ 2566834699 Flash_Amber_Warning_Lamp_AWL "Description:This parameter provides the capability to flash the AWL. 
See J1939-73 for complete reference
Parsed from -014.";
CM_ SG_ 2566834699 Flash_Protect_Lamp "Description:This parameter provides the capability to flash the protect lamp. 
See J1939-73 for complete reference
Parsed from -014.";
CM_ SG_ 2566834699 Protect_Lamp_Status "Description:Used to relay trouble code information that is reporting a problem with a vehicle system that is most probably not electronic subsystem related. For instance, engine coolant temperature is exceeding its prescribed temperat";
CM_ SG_ 2566834699 DTC_1 "Description:This signal is a combination of 4 SPNs. To decode this signal, navigate to MCS tools.
Byte: 1 bits 8-1 SPN, 8 least significant bits of SPN (most significant at bit 8, SPN 1214)
Byte: 2 bits 8-1 SPN, second byte of SPN (most significa";
CM_ SG_ 2566834699 DTC_2 "Description:This signal is a combination of 4 SPNs. To decode this signal, navigate to MCS tools.
Byte: 1 bits 8-1 SPN, 8 least significant bits of SPN (most significant at bit 8, SPN 1214)
Byte: 2 bits 8-1 SPN, second byte of SPN (most significa";
CM_ SG_ 2566834699 DTC_3 "Description:This signal is a combination of 4 SPNs. To decode this signal, navigate to MCS tools.
Byte: 1 bits 8-1 SPN, 8 least significant bits of SPN (most significant at bit 8, SPN 1214)
Byte: 2 bits 8-1 SPN, second byte of SPN (most significa";
CM_ SG_ 2566834699 DTC_4 "Description:This signal is a combination of 4 SPNs. To decode this signal, navigate to MCS tools.
Byte: 1 bits 8-1 SPN, 8 least significant bits of SPN (most significant at bit 8, SPN 1214)
Byte: 2 bits 8-1 SPN, second byte of SPN (most significa";
CM_ SG_ 2566834699 DTC_5 "Description:This signal is a combination of 4 SPNs. To decode this signal, navigate to MCS tools.
Byte: 1 bits 8-1 SPN, 8 least significant bits of SPN (most significant at bit 8, SPN 1214)
Byte: 2 bits 8-1 SPN, second byte of SPN (most significa";
CM_ SG_ 2566834699 DTC_6 "Description:This signal is a combination of 4 SPNs. To decode this signal, navigate to MCS tools.
Byte: 1 bits 8-1 SPN, 8 least significant bits of SPN (most significant at bit 8, SPN 1214)
Byte: 2 bits 8-1 SPN, second byte of SPN (most significa";
CM_ SG_ 2566834699 DTC_7 "Description:This signal is a combination of 4 SPNs. To decode this signal, navigate to MCS tools.
Byte: 1 bits 8-1 SPN, 8 least significant bits of SPN (most significant at bit 8, SPN 1214)
Byte: 2 bits 8-1 SPN, second byte of SPN (most significa";
CM_ SG_ 2566834699 DTC_8 "Description:This signal is a combination of 4 SPNs. To decode this signal, navigate to MCS tools.
Byte: 1 bits 8-1 SPN, 8 least significant bits of SPN (most significant at bit 8, SPN 1214)
Byte: 2 bits 8-1 SPN, second byte of SPN (most significa";
CM_ SG_ 2566834699 DTC_9 "Description:This signal is a combination of 4 SPNs. To decode this signal, navigate to MCS tools.
Byte: 1 bits 8-1 SPN, 8 least significant bits of SPN (most significant at bit 8, SPN 1214)
Byte: 2 bits 8-1 SPN, second byte of SPN (most significa";
CM_ SG_ 2566834699 DTC_10 "Description:This signal is a combination of 4 SPNs. To decode this signal, navigate to MCS tools.
Byte: 1 bits 8-1 SPN, 8 least significant bits of SPN (most significant at bit 8, SPN 1214)
Byte: 2 bits 8-1 SPN, second byte of SPN (most signific";
CM_ BO_ 2566846219 "Name: Vehicle Electrical Power 1
Description: Parsed from -014. ";
CM_ SG_ 2566846219 Key_Switch_Battery_Potential "Description:Battery potential measured at the input of the electronic control unit supplied through a key switch or similar switching device.
Note: Parsed from J1939DA.";
CM_ SG_ 2566846219 Alternator_Current "Description:Measure of electrical current flow from the alternator. Alternator Current (High Range/Resolution) parameter SPN 1795 has a higher range and resolution of the same parameter.
Note: Parsed from J1939DA.";
CM_ SG_ 2566846219 Charging_System_Potential_Voltag "Description:Electrical potential measured at the charging system output. The charging system may be any device charging the batteries. This includes alternators, generators, solid state charger and other charging devices.";
CM_ SG_ 2566846219 SLI_Battery_1_Net_Current "Description:Net flow of electrical current into/out of the first battery or first set of batteries used for starting the engine, for lighting, and for ignition (SLI). If more than one battery is included in the first set of batt";
CM_ SG_ 2566846219 Battery_Potential__Power_Input_1 "Description:This parameter measures the first source of battery potential as measured at the input of the ECU/actuator etc. coming from one or more batteries, irrespective of the distance between the component and the bat";
CM_ BO_ 2365532427 "Name: pTransmission Engine Interface
Description: Used to transmit request to ECM due to TCM errors and sfatey critical events.
Parsed from -014. ";
CM_ SG_ 2365532427 pMessageCounter "Description: Used to verify the signal path from Transmitter up to the Application Software layer of the Receiver.
Transmitter increments the count for every message transmission, automatically rolling over at 15.
Could not parse offset";
CM_ SG_ 2365532427 pAMTPumpStatus "Description: Used to send hydraulic pump status from AMT system. ";
CM_ SG_ 2365532427 pMessageChecksum "Description: Used to verify the signal path from Transmitter up to the Application Software layer of the Receiver.
Calculated using the CRC8 0xEA Polynomial formula. Data used in calculation is [Message ID][Data Bytes 1-7].
Could not p";
CM_ SG_ 2365532427 pEngine_Control_Shutdown_Request "Description: Used to send engine shutdown request with reducing speed from AMT system. ";
CM_ SG_ 2365532427 pAMTHydraulicPressure "Description: Used to send hydraulic pump pressure from AMT system.
Could not parse SPN data type, please add:Type: Calculated
Parsed from -014. ";
CM_ SG_ 2365532427 pAMTClutchStatus "Description: Used to send electronic clutch status from AMT system. ";
CM_ BO_ 2566831883 "Name: Wheel Speed Information
Description: Parsed from -014. ";
CM_ SG_ 2566831883 Relative_Speed_Rear_Axle_2_Right "Description:The speed of the rear axle #2, right wheel relative to the front axle speed, SPN 904.
Note: Parsed from J1939DA.";
CM_ SG_ 2566831883 Relative_Speed_Rear_Axle_1_Left_ "Description:The speed of the rear axle #1, left wheel relative to the front axle speed, SPN 904.
Note: Parsed from J1939DA.";
CM_ SG_ 2566831883 Relative_Speed_Front_Axle_Left_W "Description:The speed of the front axle, left wheel relative to the front axle speed, SPN 904.
Note: Parsed from J1939DA.";
CM_ SG_ 2566831883 Relative_Speed_Rear_Axle_2_Left_ "Description:The speed of the rear axle #2, left wheel relative to the front axle speed, SPN 904.
Note: Parsed from J1939DA.";
CM_ SG_ 2566831883 Relative_Speed_Front_Axle_Right_ "Description:The speed of the front axle, right wheel relative to the front axle speed, SPN 904.
Note: Parsed from J1939DA.";
CM_ SG_ 2566831883 Relative_Speed_Rear_Axle_1_Right "Description:The speed of the rear axle #1, right wheel relative to the front axle speed, SPN 904.
Note: Parsed from J1939DA.";
CM_ SG_ 2566831883 Front_Axle_Speed "Description:The average speed of the two front wheels.
Note: Parsed from J1939DA.";
CM_ BO_ 2566844683 "Name: Cruise Control Vehicle Speed 1
Description: Parsed from -014. ";
CM_ SG_ 2566844683 Cruise_Control_Set_Speed "Description:Value of set (chosen) velocity of velocity control system. See SPN 6809 for an alternate resolution. If an algorithm that can modify the cruise control set point exists in the system, such as Predictive Cruise Control";
CM_ SG_ 2566844683 Cruise_Control_Active "Description:Cruise control is switched on. It is not ensured that the engine is controlled by cruise control, as in the case of a large driver's demand the engine is controlled by the driver while cruise control is active (maximum s";
CM_ SG_ 2566844683 Clutch_Switch "Description:Switch signal which indicates that the clutch pedal is being pressed. It is necessary for a safe drivetrain behavior that the clutch switch is set before the clutch is opened (cruise control function). 00b = Clutch pedal release";
CM_ SG_ 2566844683 Brake_Switch "Description:Switch signal which indicates that the driver operated brake foot pedal is being pressed. This brake foot pedal is controlling the vehicles' service brake (total vehicle braking application, not park brakes). It is necessary for ";
CM_ SG_ 2566844683 pCC_Message_Counter "Description: Rolling Counter (ensures updated message is used).
Could not parse SPN data type, please add:Type: Status
Parsed from -014. ";
CM_ SG_ 2566844683 Cruise_Control_Pause_Switch "Description:Switch signal which indicates the position of the Cruise Control Pause Switch used on Remote Cruise Control applications. The Cruise Control Pause Switch signal temporarily disables the Cruise Control function. 00b";
CM_ SG_ 2566844683 Cruise_Control_Set_Switch "Description:Switch signal of the cruise control activator which indicates that the activator is in the position set. 00b = Cruise control activator not in the position set 01b = Cruise control activator in position set 10b = Err";
CM_ SG_ 2566844683 Two_Speed_Axle_Switch "Description:Switch signal which indicates the current axle range. 00b = Low speed range 01b = High speed range 10b = Error 11b = Not available
Note: Parsed from J1939DA.";
CM_ SG_ 2566844683 Cruise_Control_Enable_Switch "Description:Switch signal which indicates that it is possible to manage the cruise control function. 00b = Cruise control disabled 01b = Cruise control enabled 10b = Error 11b = Not available
Note: Parsed from J1939DA.";
CM_ SG_ 2566844683 pOdometer_Drive_Bit "Description: Each State A->B or B->A change indicates the vehicle has moved 40 m since the previous one. However, since the message is sent at regular 100 ms intervals, State A and B each occur multiple times consecutively (a minimum ";
CM_ SG_ 2566844683 pCC_Checksum "Description: XOR of bytes 0-6 (ensures data is valid before use). 
Could not parse SPN data type, please add:Type: Status
Parsed from -014. ";
CM_ SG_ 2566844683 WheelBased_Vehicle_Speed "Description:Speed of the vehicle as calculated from wheel or tailshaft speed.
Note: Parsed from J1939DA.";
CM_ SG_ 2566844683 Cruise_Control_Resume_Switch "Description:Switch signal of the cruise control activator which indicates that the activator is in the position resume. 00b = Cruise control activator not in the position resume 01b = Cruise control activator in position resu";
CM_ SG_ 2566844683 Cruise_Control_Accelerate_Switch "Description:Switch signal of the cruise control activator which indicates that the activator is in the position accelerate. 00b = Cruise control activator not in the position accelerate 01b = Cruise control activator in p";
CM_ SG_ 2566844683 pCruise_Enable_Status "Description: The Cruise Control System has been enabled by the operator. (Amber Light) ";
CM_ SG_ 2566844683 Parking_Brake_Switch "Description:Switch signal which indicates when the parking brake is set. In general the switch actuated by the operator's park brake control, whether a pedal, lever or other control mechanism (see also SPN 619 and 5275). 00b = Parkin";
CM_ SG_ 2566844683 Cruise_Control_Coast_Decelerate_ "Description:Switch signal of the cruise control activator which indicates that the activator is in the position coast (decelerate). 00b = Cruise control activator not in the position coast 01b = Cruise control activator i";
CM_ BO_ 2365552395 "Name: pRequested Torque Increase 1
Description: Used to allow an external module to request an increase in torque from an engine or motor controller
Parsed from -014. ";
CM_ SG_ 2365552395 pTotal_Torque_Output "Description: Used to transmit the torque being generated by the engine or motor. This signal shall be calculated and sent by the controller that is controlling the engine or motor
Could not parse SPN data type, please add:Type: Meas";
CM_ SG_ 2365552395 pRequested_Torque_Counter "Description: Used to detect situations where the transmitting ECU malfunctions and repeats the same frame all the time.
Could not parse SPN data type, please add:Type: Measured
Parsed from -014. ";
CM_ SG_ 2365552395 pRequested_Torque_Checksum "Description: Used to verify the signal path from the transmitting device to the receiving device. The message checksum is calculated using the first 7 data bytes, the message counter and the bytes of the message identifier
Cou";
CM_ BO_ 2365531915 "Name: pWheel Speed_BrakeStatus1 (pWSBS1)
Description: Used to broadcast High Resolution Wheel Speed Data with Counter and CRC.
Parsed from -014. ";
CM_ SG_ 2365531915 pFront_Left_Wheel_Speed "Description: Measured High Resolution Front Left Wheel Speed Data
Could not parse SPN data type, please add:Type: Measured
Parsed from -014. ";
CM_ SG_ 2365531915 pWSBS_CRC "Description: Used to verify the signal path from Transmitter up to the Application Software layer of the Receiver.
Calculated using the CRC8 0xEA Polynomial formula. Data used in calculation is [Message ID][Data Bytes 1-7].
Could not parse SP";
CM_ SG_ 2365531915 pBrake_Switch_Status "Description: Proprietary High Speed Brake Status signal determined through ESP/ABS Module ";
CM_ SG_ 2365531915 pDriven_Wheel_Speed "Description: Measured High Resolution Driven Wheel Speed Data (In case of only 1 rear wheel, rear wheel speed data)
Could not parse SPN data type, please add:Type: Measured
Parsed from -014. ";
CM_ SG_ 2365531915 pFront_Right_Wheel_Speed "Description: Measured High Resolution Front Right Wheel Speed Data
Could not parse SPN data type, please add:Type: Measured
Parsed from -014. ";
CM_ SG_ 2365531915 pWSBS_Rolling_Counter "Description: Wheel Speed PGN Rolling Counter (ensures updated message is used).
Could not parse SPN data type, please add:Type: Status
Parsed from -014. ";
CM_ BO_ 2365536779 "Name: pBCS1 (Brake Controller Status)
Description: Brake Controller Status Information Message
Parsed from -014. ";
CM_ SG_ 2365536779 pABS_Mode_Status "Description: Status Message used by the ABS Module to broadcast status of the ABS functionality  ";
CM_ SG_ 2365536779 pESC_Mode_Status "Description: Status Message used by the ABS Module to broadcast status of the ESC functionality  ";
CM_ SG_ 2365536779 pABS_Transition_Status "Description: Status Message used by the ABS Module to broadcast permission for the Display to allow user to press ABS OFF/ON ";
CM_ SG_ 2365536779 pTC_Mode_Status "Description: Status Message used by the ABS Module to broadcast status of the TC functionality  ";
CM_ BO_ 2231336203 "Name: Remote Brake Control 1
Description:Communicated on the vehicle communication bus.  Contains signals to command the vehicle’s braking system.";
CM_ SG_ 2231336203 pActual_Braking_Application "Description:Signal to provide information about the current applied braking. 0% is no braking; 100% is full braking.
Units:			%Could not parse offset, please add:Offset:		0
Could not parse SPN data type, please add:Type:			Mea";
CM_ SG_ 2231336203 pEBC_Mode_Status "Description:Signal to provide the current state of the EBC Controller. Parsed from Confidential 014.";
CM_ SG_ 2231336203 Message_Counter "Description:Input Description: The message counter is used to detect situations where the transmitting ECU malfunction repeats the same frame all the time.Could not parse offset, please add:Offset:		0
Could not parse SPN data type, please";
CM_ SG_ 2231336203 Message_Checksum "Description:Used to verify the signal path from Transmitter up to the Application Software layer of the Receiver.
Calculated using the following formula:
<INSERT FORMULA>Could not parse offset, please add:Offset:		0
Could not parse SPN d";
CM_ BO_ 2231336205 "Name: Remote Brake Control 1
Description:Communicated on the vehicle communication bus.  Contains signals to command the vehicle’s braking system.";
CM_ SG_ 2231336205 pActual_Braking_Application "Description:Signal to provide information about the current applied braking. 0% is no braking; 100% is full braking.
Units:			%Could not parse offset, please add:Offset:		0
Could not parse SPN data type, please add:Type:			Mea";
CM_ SG_ 2231336205 pEBC_Mode_Status "Description:Signal to provide the current state of the EBC Controller. Parsed from Confidential 014.";
CM_ SG_ 2231336205 Message_Counter "Description:Input Description: The message counter is used to detect situations where the transmitting ECU malfunction repeats the same frame all the time.Could not parse offset, please add:Offset:		0
Could not parse SPN data type, please";
CM_ SG_ 2231336205 Message_Checksum "Description:Used to verify the signal path from Transmitter up to the Application Software layer of the Receiver.
Calculated using the following formula:
<INSERT FORMULA>Could not parse offset, please add:Offset:		0
Could not parse SPN d";
CM_ BO_ 2566877965 "Name: pRemote EPS Control 1
Description: Information regarding the command mode of an Electric Power Steering Unit (EPS). This contains the mode in which the EPS is commanded as well as two variables pertaining to each individual commanded mode.
Parsed";
CM_ SG_ 2566877965 pEPS_Commanded_Var2 "Description: This is the power steering command variable 2. **Note &ndash; The interpretation of this variable changes based on the EPS commanded control mode, SPN 524111.

For all interpretations:
Could not parse SPN data type, pl";
CM_ SG_ 2566877965 pEPS_Commanded_Control_Mode "Description: The commanded control mode that the EPS unit will operate in. ";
CM_ SG_ 2566877965 pEPS_Commanded_Var1 "Description: This is the power steering command variable 1. **Note &ndash; The interpretation of this variable changes based on the EPS commanded control mode, SPN 524111.

Parsed from -014. SPN 524111 - Mode 3(0x03) Variable Descri";
CM_ BO_ 2566846227 "Name: Vehicle Electrical Power 1
Description: Parsed from -014. ";
CM_ SG_ 2566846227 Key_Switch_Battery_Potential "Description:Battery potential measured at the input of the electronic control unit supplied through a key switch or similar switching device.
Note: Parsed from J1939DA.";
CM_ SG_ 2566846227 Alternator_Current "Description:Measure of electrical current flow from the alternator. Alternator Current (High Range/Resolution) parameter SPN 1795 has a higher range and resolution of the same parameter.
Note: Parsed from J1939DA.";
CM_ SG_ 2566846227 Charging_System_Potential_Voltag "Description:Electrical potential measured at the charging system output. The charging system may be any device charging the batteries. This includes alternators, generators, solid state charger and other charging devices.";
CM_ SG_ 2566846227 SLI_Battery_1_Net_Current "Description:Net flow of electrical current into/out of the first battery or first set of batteries used for starting the engine, for lighting, and for ignition (SLI). If more than one battery is included in the first set of batt";
CM_ SG_ 2566846227 Battery_Potential__Power_Input_1 "Description:This parameter measures the first source of battery potential as measured at the input of the ECU/actuator etc. coming from one or more batteries, irrespective of the distance between the component and the bat";
CM_ BO_ 2365547027 "Name: pEPS with SAS
Description: Contains information which relates to a power steering unit with a steering angle sensor. 
Parsed from -014. ";
CM_ SG_ 2365547027 pEPS_Shaft_Velocity "Description:The rotational velocity of the power steering shaft, positive values when steering to the right";
CM_ SG_ 2365547027 pEPS_Requested_Mode_Ack "Description: This signal represents the commanded Electronic Power Steering functional mode. ";
CM_ SG_ 2365547027 pEPS_SAS_Message_Counter "Description: Message counter to allow detection of data integrity issues.
See J1939-71 for complete reference.
Could not parse SPN data type, please add:Type: Status
Parsed from -014. ";
CM_ SG_ 2365547027 pEPS_Shaft_Position "Description:The position (steering angle) of the EPS output shaft relative to the calibrated center position. Right-of-center positions are positive, per SAE J670 Z-Down coordinate system";
CM_ SG_ 2365547027 pEPS_SAS_CRC8 "Description: Used to verify the signal path from Transmitter up to the Application Software layer of the Receiver.
Calculated using the following formula:

Could not parse offset, please add:Offset:0
Could not parse SPN data type, pleas";
CM_ SG_ 2365547027 pEPS_Active_Mode "Description: The mode that the power steering unit is currently functioning in. ";
CM_ BO_ 2566874899 "Name: pElectric Power Assisted Steering
Description: Parsed from -014. ";
CM_ SG_ 2566874899 pSteering_Velocity_EPAS_Steering "Description: NO LONGER ACTIVE BITS SET to 128
Steering velocity for the EPAS steering motor driver 
Parsed from -014. ";
CM_ SG_ 2566874899 pGeneratedCurrent "Description:Measured current generated by the motor driver 
";
CM_ SG_ 2566874899 pSteerAssistTq "Description: Commanded output torque of the EPAS steering system Type: Calculated

 ";
CM_ SG_ 2566874899 pSensed_Input_Steering_Torque "Description:pMeasured EPS input torque";
CM_ SG_ 2566874899 pVTemp_EPAS_Steering "Description: Temperature of the inverter for the EPAS steering motor driver 
Could not parse SPN data type, please add:Type: Measured
Parsed from -014. ";
CM_ BO_ 2365551635 "Name: pElectronic Power Steering 2
Description: Contains information which relates to a power steering unit with a steering angle sensor. 
Parsed from -014. ";
CM_ SG_ 2365551635 pEPS_Operation_Status "Description: The operational stutas of the EPS unit. ";
CM_ SG_ 2365551635 pEPS_SAS_Calibrated "Description: Indicates the calibration status of the EPS steering angle sensor. ";
CM_ SG_ 2365551635 pEPS_Active_Mode "Description: The mode that the power steering unit is currently functioning in. ";
CM_ SG_ 2365551635 pEPS_Shaft_Position "Description:The position (steering angle) of the EPS output shaft relative to the calibrated center position. Right-of-center positions are positive, per SAE J670 Z-Down coordinate system";
CM_ SG_ 2365551635 pEPS_Shaft_Velocity "Description:The rotational velocity of the power steering shaft, positive values when steering to the right";
CM_ BO_ 2566875411 "Name: pElectric Power Assisted Steering
Description: Parsed from -014. ";
CM_ SG_ 2566875411 pEPS_Message_Counter "Description:Message counter to allow detection of data integrity issues.
See J1939-71 for complete reference.
Could not parse SPN data type, please add:Type: Status
Parsed from -014.";
CM_ SG_ 2566875411 pSteerAssistTq "Description: Commanded output torque of the EPAS steering system Type: Calculated

 ";
CM_ SG_ 2566875411 pGeneratedCurrent "Description:Measured current generated by the motor driver 
";
CM_ SG_ 2566875411 pSensed_Input_Steering_Torque "Description:pMeasured EPS input torque";
CM_ SG_ 2566875411 pEPS_CRC8 "Description: Used to verify the signal path from Transmitter up to the Application Software layer of the Receiver.
Calculated using the following formula:

Could not parse offset, please add:Offset: 0
Could not parse SPN data type, please a";
CM_ BO_ 2566834707 "Name: Active Diagnostic Trouble Codes
Description:DM1 provides diagnostic lamp status and Diagnostic Trouble Codes (DTCs). Together, the lamp and DTC information
convey the diagnostic condition of the transmitting electronic component to other componen";
CM_ SG_ 2566834707 Flash_Malfunction_Indicator_Lamp "Description:This parameter provides the capability to flash the MIL. For OBD systems which are required to flash the SPN for specific malfunctions shall use the “slow flash” rate. 
See J1939-73 for complete reference
Pa";
CM_ SG_ 2566834707 Malfunction_Indicator_Lamp_Statu "Description:Used to relay only emissions-related trouble code information. This lamp is only illuminated when there is an emission-related trouble code active.
See J1939-71 for complete reference

Parsed from -014.";
CM_ SG_ 2566834707 Red_Stop_Lamp_Status "Description:Used to relay trouble code information that is of a severe enough condition that it warrants stopping the vehicle.
See J1939-71 for complete reference

Parsed from -014.";
CM_ SG_ 2566834707 Amber_Warning_Lamp_Status "Description:Used to relay trouble code information that is reporting a problem with the vehicle system but the vehicle need not be immediately stopped.
See J1939-71 for complete reference

Parsed from -014.";
CM_ SG_ 2566834707 Flash_Red_Stop_Lamp_RSL "Description:This parameter provides the capability to flash the RSL.
See J1939-73 for complete reference
Parsed from -014.";
CM_ SG_ 2566834707 Flash_Amber_Warning_Lamp_AWL "Description:This parameter provides the capability to flash the AWL. 
See J1939-73 for complete reference
Parsed from -014.";
CM_ SG_ 2566834707 Flash_Protect_Lamp "Description:This parameter provides the capability to flash the protect lamp. 
See J1939-73 for complete reference
Parsed from -014.";
CM_ SG_ 2566834707 Protect_Lamp_Status "Description:Used to relay trouble code information that is reporting a problem with a vehicle system that is most probably not electronic subsystem related. For instance, engine coolant temperature is exceeding its prescribed temperat";
CM_ SG_ 2566834707 DTC_1 "Description:This signal is a combination of 4 SPNs. To decode this signal, navigate to MCS tools.
Byte: 1 bits 8-1 SPN, 8 least significant bits of SPN (most significant at bit 8, SPN 1214)
Byte: 2 bits 8-1 SPN, second byte of SPN (most significa";
CM_ SG_ 2566834707 DTC_2 "Description:This signal is a combination of 4 SPNs. To decode this signal, navigate to MCS tools.
Byte: 1 bits 8-1 SPN, 8 least significant bits of SPN (most significant at bit 8, SPN 1214)
Byte: 2 bits 8-1 SPN, second byte of SPN (most significa";
CM_ SG_ 2566834707 DTC_3 "Description:This signal is a combination of 4 SPNs. To decode this signal, navigate to MCS tools.
Byte: 1 bits 8-1 SPN, 8 least significant bits of SPN (most significant at bit 8, SPN 1214)
Byte: 2 bits 8-1 SPN, second byte of SPN (most significa";
CM_ SG_ 2566834707 DTC_4 "Description:This signal is a combination of 4 SPNs. To decode this signal, navigate to MCS tools.
Byte: 1 bits 8-1 SPN, 8 least significant bits of SPN (most significant at bit 8, SPN 1214)
Byte: 2 bits 8-1 SPN, second byte of SPN (most significa";
CM_ SG_ 2566834707 DTC_5 "Description:This signal is a combination of 4 SPNs. To decode this signal, navigate to MCS tools.
Byte: 1 bits 8-1 SPN, 8 least significant bits of SPN (most significant at bit 8, SPN 1214)
Byte: 2 bits 8-1 SPN, second byte of SPN (most significa";
CM_ SG_ 2566834707 DTC_6 "Description:This signal is a combination of 4 SPNs. To decode this signal, navigate to MCS tools.
Byte: 1 bits 8-1 SPN, 8 least significant bits of SPN (most significant at bit 8, SPN 1214)
Byte: 2 bits 8-1 SPN, second byte of SPN (most significa";
CM_ SG_ 2566834707 DTC_7 "Description:This signal is a combination of 4 SPNs. To decode this signal, navigate to MCS tools.
Byte: 1 bits 8-1 SPN, 8 least significant bits of SPN (most significant at bit 8, SPN 1214)
Byte: 2 bits 8-1 SPN, second byte of SPN (most significa";
CM_ SG_ 2566834707 DTC_8 "Description:This signal is a combination of 4 SPNs. To decode this signal, navigate to MCS tools.
Byte: 1 bits 8-1 SPN, 8 least significant bits of SPN (most significant at bit 8, SPN 1214)
Byte: 2 bits 8-1 SPN, second byte of SPN (most significa";
CM_ SG_ 2566834707 DTC_9 "Description:This signal is a combination of 4 SPNs. To decode this signal, navigate to MCS tools.
Byte: 1 bits 8-1 SPN, 8 least significant bits of SPN (most significant at bit 8, SPN 1214)
Byte: 2 bits 8-1 SPN, second byte of SPN (most significa";
CM_ SG_ 2566834707 DTC_10 "Description:This signal is a combination of 4 SPNs. To decode this signal, navigate to MCS tools.
Byte: 1 bits 8-1 SPN, 8 least significant bits of SPN (most significant at bit 8, SPN 1214)
Byte: 2 bits 8-1 SPN, second byte of SPN (most signific";
CM_ BO_ 2565865751 "Name: Electronics Brake Controller 1
Description: Parsed from -014. ";
CM_ SG_ 2565865751 ABS_Offroad_Switch "Description:Switch signal which indicates the position of the ABS off-road switch. 00b = ABS off-road switch passive 01b = ABS off-road switch active 10b = Error 11b = Not available
Note: Parsed from J1939DA.";
CM_ SG_ 2565865751 ABSEBS_Amber_Warning_Signal_Powe "Description:This parameter commands the ABS/EBS amber/yellow optical warning signal 00b = Off 01b = On 10b = Reserved 11b = Take no action
Note: Parsed from J1939DA.";
CM_ SG_ 2565865751 ASR_Brake_Control_Active "Description:State signal which indicates that ASR brake control is active. Active means that ASR actually controls wheel brake pressure at one or more wheels of the driven axle(s). 00b = ASR brake control passive but installed 01";
CM_ SG_ 2565865751 Source_Address_of_Controlling_De "Description:The source address of the SAE J1939 device currently controlling the brake system. Its value may be the source address of the ECU transmitting the message (which means that no external SAE J1939 message is pro";
CM_ SG_ 2565865751 EBS_Red_Warning_Signal "Description:This parameter commands the EBS red optical warning signal 00b = Off 01b = On 10b = Reserved 11b = Take no action
Note: Parsed from J1939DA.";
CM_ SG_ 2565865751 ASR_Engine_Control_Active "Description:State signal which indicates that ASR engine control has been commanded to be active. Active means that ASR actually tries to control the engine. This state signal is independent of other control commands to the engi";
CM_ SG_ 2565865751 AntiLock_Braking_ABS_Active "Description:State signal which indicates that the ABS is active. The signal is set active when wheel brake pressure actually starts to be modulated by ABS and is reset to passive when all wheels are in a stable condition for a";
CM_ SG_ 2565865751 ATCASR_Information_Signal "Description:This parameter commands the ATC/ASR driver information signal, for example a dash lamp. 00b = Off 01b = On 10b = Reserved 11b = Take no action
Note: Parsed from J1939DA.";
CM_ SG_ 2565865751 ABS_Fully_Operational "Description:Signal which indicates whether an ABS system is fully operational or whether its functionality is reduced by a defect or by an intended action (e.g., by activation of an ABS-off-road switch or during special diagnostic p";
CM_ SG_ 2565865751 Traction_Control_Override_Switch "Description:Switch signal which indicates the position of the traction control override switch. The traction control override signal disables the automatic traction control function allowing the wheels to spin. 00b = Off ";
CM_ BO_ 2631859991 "Name: Reset
Description:Parsed from -014.";
CM_ SG_ 2631859991 Trip_Group_1 "Description:Command signal used to reset the PGs and parameters as defined in Table SPN988_A. 00b = Take no action 01b = Reset 10b = Reserved 11b = Not applicable
Note: Parsed from J1939DA.";
CM_ SG_ 2631859991 Trip_Group_2__Proprietary "Description:Command signal used to reset proprietary parameters associated with a trip but not defined within this document. 00b = Take no action 01b = Reset 10b = Reserved 11b = Not applicable
Note: Parsed from J1939DA.";
CM_ BO_ 2566834711 "Name: Active Diagnostic Trouble Codes
Description:DM1 provides diagnostic lamp status and Diagnostic Trouble Codes (DTCs). Together, the lamp and DTC information
convey the diagnostic condition of the transmitting electronic component to other componen";
CM_ SG_ 2566834711 Flash_Malfunction_Indicator_Lamp "Description:This parameter provides the capability to flash the MIL. For OBD systems which are required to flash the SPN for specific malfunctions shall use the “slow flash” rate. 
See J1939-73 for complete reference
Pa";
CM_ SG_ 2566834711 Malfunction_Indicator_Lamp_Statu "Description:Used to relay only emissions-related trouble code information. This lamp is only illuminated when there is an emission-related trouble code active.
See J1939-71 for complete reference

Parsed from -014.";
CM_ SG_ 2566834711 Red_Stop_Lamp_Status "Description:Used to relay trouble code information that is of a severe enough condition that it warrants stopping the vehicle.
See J1939-71 for complete reference

Parsed from -014.";
CM_ SG_ 2566834711 Amber_Warning_Lamp_Status "Description:Used to relay trouble code information that is reporting a problem with the vehicle system but the vehicle need not be immediately stopped.
See J1939-71 for complete reference

Parsed from -014.";
CM_ SG_ 2566834711 Flash_Red_Stop_Lamp_RSL "Description:This parameter provides the capability to flash the RSL.
See J1939-73 for complete reference
Parsed from -014.";
CM_ SG_ 2566834711 Flash_Amber_Warning_Lamp_AWL "Description:This parameter provides the capability to flash the AWL. 
See J1939-73 for complete reference
Parsed from -014.";
CM_ SG_ 2566834711 Flash_Protect_Lamp "Description:This parameter provides the capability to flash the protect lamp. 
See J1939-73 for complete reference
Parsed from -014.";
CM_ SG_ 2566834711 Protect_Lamp_Status "Description:Used to relay trouble code information that is reporting a problem with a vehicle system that is most probably not electronic subsystem related. For instance, engine coolant temperature is exceeding its prescribed temperat";
CM_ SG_ 2566834711 DTC_1 "Description:This signal is a combination of 4 SPNs. To decode this signal, navigate to MCS tools.
Byte: 1 bits 8-1 SPN, 8 least significant bits of SPN (most significant at bit 8, SPN 1214)
Byte: 2 bits 8-1 SPN, second byte of SPN (most significa";
CM_ SG_ 2566834711 DTC_2 "Description:This signal is a combination of 4 SPNs. To decode this signal, navigate to MCS tools.
Byte: 1 bits 8-1 SPN, 8 least significant bits of SPN (most significant at bit 8, SPN 1214)
Byte: 2 bits 8-1 SPN, second byte of SPN (most significa";
CM_ SG_ 2566834711 DTC_3 "Description:This signal is a combination of 4 SPNs. To decode this signal, navigate to MCS tools.
Byte: 1 bits 8-1 SPN, 8 least significant bits of SPN (most significant at bit 8, SPN 1214)
Byte: 2 bits 8-1 SPN, second byte of SPN (most significa";
CM_ SG_ 2566834711 DTC_4 "Description:This signal is a combination of 4 SPNs. To decode this signal, navigate to MCS tools.
Byte: 1 bits 8-1 SPN, 8 least significant bits of SPN (most significant at bit 8, SPN 1214)
Byte: 2 bits 8-1 SPN, second byte of SPN (most significa";
CM_ SG_ 2566834711 DTC_5 "Description:This signal is a combination of 4 SPNs. To decode this signal, navigate to MCS tools.
Byte: 1 bits 8-1 SPN, 8 least significant bits of SPN (most significant at bit 8, SPN 1214)
Byte: 2 bits 8-1 SPN, second byte of SPN (most significa";
CM_ SG_ 2566834711 DTC_6 "Description:This signal is a combination of 4 SPNs. To decode this signal, navigate to MCS tools.
Byte: 1 bits 8-1 SPN, 8 least significant bits of SPN (most significant at bit 8, SPN 1214)
Byte: 2 bits 8-1 SPN, second byte of SPN (most significa";
CM_ SG_ 2566834711 DTC_7 "Description:This signal is a combination of 4 SPNs. To decode this signal, navigate to MCS tools.
Byte: 1 bits 8-1 SPN, 8 least significant bits of SPN (most significant at bit 8, SPN 1214)
Byte: 2 bits 8-1 SPN, second byte of SPN (most significa";
CM_ SG_ 2566834711 DTC_8 "Description:This signal is a combination of 4 SPNs. To decode this signal, navigate to MCS tools.
Byte: 1 bits 8-1 SPN, 8 least significant bits of SPN (most significant at bit 8, SPN 1214)
Byte: 2 bits 8-1 SPN, second byte of SPN (most significa";
CM_ SG_ 2566834711 DTC_9 "Description:This signal is a combination of 4 SPNs. To decode this signal, navigate to MCS tools.
Byte: 1 bits 8-1 SPN, 8 least significant bits of SPN (most significant at bit 8, SPN 1214)
Byte: 2 bits 8-1 SPN, second byte of SPN (most significa";
CM_ SG_ 2566834711 DTC_10 "Description:This signal is a combination of 4 SPNs. To decode this signal, navigate to MCS tools.
Byte: 1 bits 8-1 SPN, 8 least significant bits of SPN (most significant at bit 8, SPN 1214)
Byte: 2 bits 8-1 SPN, second byte of SPN (most signific";
CM_ BO_ 2564161303 "Name: Time/Date Adjust
Description: Parsed from -014. ";
CM_ SG_ 2564161303 Adjust_hours "Description:The hours component for setting the current time of day. This should be reported as the hours component of the current time according to the time of day standard indicated with the Local Hour Offset parameter (SPN 1602). The time";
CM_ SG_ 2564161303 Adjust_day "Description:The day component for setting the current calendar date. This should be reported as the day component of the current date according to the calendar date standard indicated with the Local Hour Offset parameter (SPN 1602). The calend";
CM_ SG_ 2564161303 Adjust_local_hour_offset "Description:The hour component for setting the offset between the UTC (Universal Time Coordinate) time and date and a the local time zone time and date. This is the number of minutes to add to UTC, a.k.a. GMT, time and date to co";
CM_ SG_ 2564161303 Adjust_seconds "Description:The seconds component for setting the current time of day. This should be reported as the seconds component of the current time according to the time of day standard indicated with the Local Hour Offset parameter (SPN 1602). Th";
CM_ SG_ 2564161303 Adjust_month "Description:The month component for setting the current calendar date. This should be reported as the month component of the current date according to the calendar date standard indicated with the Local Hour Offset parameter (SPN 1602). The ";
CM_ SG_ 2564161303 Adjust_year "Description:The year component for setting the current calendar date. This should be reported as the year component of the current date according to the calendar date standard indicated with the Local Hour Offset parameter (SPN 1602). The cal";
CM_ SG_ 2564161303 Adjust_local_minute_offset "Description:The minute component for setting the offset between the UTC (Universal Time Coordinate) time and date and a the local time zone time and date. This is the number of minutes to add to UTC, a.k.a. GMT, time and date t";
CM_ SG_ 2564161303 Adjust_minutes "Description:The minutes component for setting the current time of day. This should be reported as the minutes component of the current time according to the time of day standard indicated with the Local Hour Offset parameter (SPN 1602). Th";
CM_ BO_ 2563833623 "Name: Cab Illumination Message
Description: Parsed from -014. ";
CM_ SG_ 2563833623 Illumination_Brightness_Percent "Description:Commanded backlight brightness level for all cab displays. Note: If a separate device is used to independently control the switch backlight brightness level, see SPN 5532.
Note: Parsed from J1939DA.";
CM_ BO_ 2566832407 "Name: High Resolution Vehicle Distance
Description: Parsed from -014. ";
CM_ SG_ 2566832407 Total_Vehicle_Distance_High_Reso "Description:Accumulated distance traveled by the vehicle during its operation. NOTE - See SPN 245 for alternate resolution.
Note: Parsed from J1939DA.";
CM_ SG_ 2566832407 Trip_Distance_High_Resolution "Description:Distance traveled during all or part of a journey. NOTE - See SPN 244 for alternate resolution.
Note: Parsed from J1939DA.";
CM_ BO_ 2566847511 "Name: Dash Display
Description: Parsed from -014. ";
CM_ SG_ 2566847511 Fuel_Level_1 "Description:Ratio of volume of fuel to the total volume of fuel storage container. When Fuel Level 2 (SPN 38) is not used, Fuel Level 1 represents the total fuel in all fuel storage containers. When Fuel Level 2 is used, Fuel Level 1 represe";
CM_ BO_ 2631794455 "Name: Anti-Theft Request
Description: Parsed from -014. ";
CM_ SG_ 2631794455 Antitheft_Desired_Exit_Mode_Stat "Description:This parameter is used to specify the desired triggers that are to be used by the component in deciding when to transition to the Locked state. 00b = Lock_Upon_Operator_Request 01b = Lock_When_Key_Off 10b = No";
CM_ SG_ 2631794455 Antitheft_Encryption_Indicator_S "Description:This parameter is used to indicate if a random number seed is being requested, or if an encrypted password is being provided to the component. 00b = Encryption_Seed_Request 01b = Encrypted_Code_Present 10b = N";
CM_ SG_ 2631794455 Antitheft_Command_States "Description:This parameter is used to identify the specific requests being sent to the component. 000b = Add_Password 001b = Delete_Password 010b = Change_Password 011b = Lock_or_Unlock 100b = Check_Status 101b = Login 110b = Not";
CM_ SG_ 2631794455 Antitheft_Password_Representatio "Description:This parameter is the seven byte numeric code (i.e., 'encrypted password' or 'key') that is generated based on the encryption algorithm, the password supplied by the end user, and the random number seed given ";
CM_ BO_ 2566845719 "Name: Ambient Conditions
Description: Parsed from -014. ";
CM_ SG_ 2566845719 Ambient_Air_Temperature "Description:Temperature of air surrounding vehicle.
Note: Parsed from J1939DA.";
CM_ SG_ 2566845719 Barometric_Pressure "Description:Absolute air pressure of the atmosphere.
Note: Parsed from J1939DA.";
CM_ SG_ 2566845719 Road_Surface_Temperature "Description:Indicated temperature of road surface over which vehicle is operating.
Note: Parsed from J1939DA.";
CM_ SG_ 2566845719 Engine_Intake_1_Air_Temperature "Description:Temperature of air entering vehicle air induction system.
Note: Parsed from J1939DA.";
CM_ BO_ 2432658455 "Name: pOperator Switch Status
Description: Parsed from -014. ";
CM_ SG_ 2432658455 pFOCC_Checksum "Description: XOR of bytes 0-6 (ensures data is valid before use). 
Could not parse SPN data type, please add:Type: Status
Parsed from -014. ";
CM_ SG_ 2432658455 Drive_Mode__4 "Description: Broadcasting the status of the operator switch.  ";
CM_ SG_ 2432658455 Drive_Mode__2 "Description: Broadcasting the status of the operator switch.  ";
CM_ SG_ 2432658455 pFOCC_Message_Counter "Description: Rolling Counter (ensures updated message is used).
Could not parse SPN data type, please add:Type: Status
Parsed from -014. ";
CM_ SG_ 2432658455 Drivers_Net_Engagement "Description: Broadcasting the status of the operator switch.  ";
CM_ SG_ 2432658455 Foot_On_Cruise_Control_Switch "Description: Broadcasting the status of the operator switch.  ";
CM_ SG_ 2432658455 Drive_Mode__1 "Description: Broadcasting the status of the operator switch.  ";
CM_ SG_ 2432658455 Momentary_Driveline_Left_Press "Description: Broadcasting the status of the operator switch.  ";
CM_ SG_ 2432658455 CylDeAc_Enable "Description: Broadcasting the status of the operator switch for CylDeAc. ";
CM_ SG_ 2432658455 Work_Group_Lock_Switch "Description: Broadcasting the status of the operator switch.  ";
CM_ SG_ 2432658455 Drivers_Seatbelt_Engagement "Description: Broadcasting the status of the operator switch.  ";
CM_ SG_ 2432658455 Drive_Mode__3 "Description: Broadcasting the status of the operator switch.  ";
CM_ SG_ 2432658455 Work_Mode_Switch "Description: Broadcasting the status of the operator switch.  ";
CM_ SG_ 2432658455 Momentary_Driveline_Right_Press "Description: Broadcasting the status of the operator switch.  ";
CM_ SG_ 2432658455 PTO_Mode_Switch_RPM_Control "Description: Broadcasting the status of the operator switch.  ";
CM_ SG_ 2432658455 Operator_Presence_Switch "Description: Broadcasting the status of the operator switch.  ";
CM_ SG_ 2432658455 Tilt_Lock_Switch "Description: Broadcasting the status of the operator switch.  ";
CM_ SG_ 2432658455 Engine_Brake_Enable "Description: Broadcasting the status of the operator switch for Engine Brake. ";
CM_ SG_ 2432658455 Accessory_Relay "Description: ";
CM_ BO_ 2566876439 "Name: pDrive Mode (ETC)
Description: Parsed from -014. ";
CM_ SG_ 2566876439 pFarm_Mode_Set_Speed "Description: The current speed limit when work mode is active as measured in km/h/bit.
Could not parse SPN data type, please add:Type: Measured
Parsed from -014. ";
CM_ SG_ 2566876439 pDrive_Mode_Requested "Description: ASCII Representation of Drive Mode Requested. 
Could not parse SPN data type, please add:Type: Measured
Parsed from -014. ";
CM_ SG_ 2566876439 pFarm_Mode_Maximum_Speed "Description: The maximum set speed allowed by work mode as measured in km/h/bit.
Could not parse SPN data type, please add:Type: Measured
Parsed from -014. ";
CM_ SG_ 2566876439 pDrive_Mode_Commanded "Description: ASCII Representation of Drive Mode Commanded.
Could not parse SPN data type, please add:Type: Status
Parsed from -014. ";
CM_ SG_ 2566876439 pEngine_Brake_Active "Description: Indicates whether or not the engine control module is in engine braking mode. ";
CM_ SG_ 2566876439 pFarm_Mode_Minimum_Speed "Description: The minimum set speed allowed by work mode as measured in km/h/bit.
Could not parse SPN data type, please add:Type: Measured
Parsed from -014. ";
CM_ SG_ 2566876439 pFoot_On_Cruise_Enable "Description: Indicates whether or not the Foot on Cruise has been enabled. ";
CM_ SG_ 2566876439 pFarm_Mode_Speed_Decrement "Description: Signal to decrement the speed value saved in the ECM. ";
CM_ SG_ 2566876439 pEngine_Brake_Enabled "Description: Indicates whether or not Engine Braking has been enabled. ";
CM_ SG_ 2566876439 pCylDeAc_Enabled "Description: Indicates whether or not CylDeAc has been enabled. ";
CM_ SG_ 2566876439 pFarm_Mode_Speed_Increment "Description: Signal to increment the speed value saved in the ECM. ";
CM_ SG_ 2566876439 pCylDeAc_Active "Description: Indicates whether or not the engine control module has deliberately deactivated cylinder(s). ";
CM_ BO_ 2566887959 "Name: pAntiTheft
Description: Parsed from -014. ";
CM_ SG_ 2566887959 pAntiTheft_Component_Status_Indi "Description: This state signal is included in the lower functionality proprietary Anti-Theft implementation. The product team&rsquo;s specification did not line up with the J1939 standard Anti-Theft messages, nor the alre";
CM_ SG_ 2566887959 pAntiTheft_Command_States "Description: This command signal is included in the lower functionality proprietary Anti-Theft implementation. The product team&rsquo;s specification did not line up with the J1939 standard Anti-Theft messages, nor the already n";
CM_ SG_ 2566887959 pAntiTheft_Pin_Presence "Description: 
This parameter is used to indicate if a pin is being provided or requested to the component. ";
CM_ SG_ 2566887959 pAntiTheft_Pin_Parameter "Description: 
A four byte numeric code used to represent the user pin in response to a pin request or on pin change. This parameter is sent as a numeric value utilizing the full range of 0 to 0xFFFFFFFF. The most significant byt";
CM_ BO_ 2566865687 "Name: pAdjusted Speed Limit (ASL)
Description: 
Parsed from -014. ";
CM_ SG_ 2566865687 pASL_Enable "Description: Indicates whether or not the ASL has been enabled. ";
CM_ SG_ 2566865687 pASL_Maximum_Speed "Description: The maximum set speed allowed by ASL feature as measured in km/h/bit.
Could not parse SPN data type, please add:Type: Measured
Parsed from -014. ";
CM_ SG_ 2566865687 pASL_Set_Speed "Description: The current speed limit when ASL is active as measured in km/h/bit.
Could not parse SPN data type, please add:Type: Measured
Parsed from -014. ";
CM_ SG_ 2566865687 pASL_Speed_Decrement "Description: Signal to decrement the speed value saved in the ECM. ";
CM_ SG_ 2566865687 pASL_Speed_Increment "Description: Signal to increment the speed value saved in the ECM. ";
CM_ SG_ 2566865687 pASL_Minimum_Speed "Description: The minimum set speed allowed by ASL feature as measured in km/h/bit.
Could not parse SPN data type, please add:Type: Measured
Parsed from -014. ";
CM_ BO_ 2566877463 "Name: pCluster Status 1
Description: Parsed from -014. ";
CM_ SG_ 2566877463 pTemperature_Units_Selected "Description: Active display temperature units beased on user selection or auto-configuration. ";
CM_ SG_ 2566877463 pTPMS_Learning_Status "Description: Indicates the status of the tire pressure monitoring sensor learning process. ";
CM_ SG_ 2566877463 pPressure_Units_Selected "Description: Active display pressure units beased on user selection or auto-configuration. ";
CM_ SG_ 2566877463 pHigh_Res_Trip_2_Distance "Description: Secondary distance travled during all or part of a journey.
Could not parse SPN data type, please add:Type: Measured
Parsed from -014. ";
CM_ SG_ 2566877463 pVolume_Units_Selected "Description: Active display volume units beased on user selection or auto-configuration. ";
CM_ SG_ 2566877463 pDisplay_Status "Description: Status of display. ";
CM_ SG_ 2566877463 pTime_Units_Selected "Description: Active display time units beased on user selection or auto-configuration. ";
CM_ SG_ 2566877463 pDistance_Units_Selected "Description: Active display distance units beased on user selection or auto-configuration. ";
CM_ BO_ 2348875548 "Name: Torque/Speed Control 1
Description: Parsed from -014. ";
CM_ SG_ 2348875548 Engine_Requested_Torque_Fraction "Description:This parameter displays an additional torque in percent of the reference engine torque. When the MSB is set to 1, this parameter is not available. When the MSB is set to 0, bits 1 to 3 indicate the desired tor";
CM_ SG_ 2348875548 Engine_Override_Control_Mode "Description:The override control mode defines which sort of command is used: 00b = Override disabled - Disable any existing control commanded by the source of this command. 01b = Speed control - Govern speed to the included d";
CM_ SG_ 2348875548 Engine_Requested_SpeedSpeed_Limi "Description:Parameter provided to the engine from external sources in the torque/speed control message. This is the engine speed which the engine is expected to operate at if the speed control mode is active or the engine";
CM_ SG_ 2348875548 Engine_Requested_Speed_Control_C "Description:This mode tells the engine control system the governor characteristics that are desired during speed control. The four characteristics defined are: 00b = Transient Optimized for driveline disengaged and non-lo";
CM_ SG_ 2348875548 TSC1_Control_Purpose "Description:State signal which indicates which control mode the sending device is using to generate the TSC1 command. Note that the modes are not in prioritized order. Not all modes may be relevant for a given device. Some devices ma";
CM_ SG_ 2348875548 Override_Control_Mode_Priority "Description:This field is used as an input to the engine or retarder to determine the priority of the Override Control Mode received in the Torque/Speed Control message (see PGN 0). The default is 11b (Low priority). It is ";
CM_ SG_ 2348875548 TSC1_Transmission_Rate "Description:This parameter indicates the transmission rate at which the sending device will transmit the TSC1 message. The engine shall adjust its timeout for TSC1 messages accordingly. Variable TSC1 transmission rates shall only a";
CM_ SG_ 2348875548 Engine_Requested_TorqueTorque_Li "Description:Parameter provided to the engine or retarder in the torque/speed control message for controlling or limiting the output torque. Requested torque to the engine is measured in indicated torque as a percentage of";
CM_ BO_ 2566842396 "Name: Vehicle Direction/Speed
Description: Parsed from -014. ";
CM_ SG_ 2566842396 Compass_Bearing "Description:Present compass bearing of vehicle.
Note: Parsed from J1939DA.";
CM_ BO_ 2631728925 "Name: Anti-Theft Staus
Description: Parsed from -014. ";
CM_ SG_ 2631728925 Antitheft_Random_Number "Description:A seven byte random numeric code provided by the component in response to an anti-theft request. This parameter is sent as a numeric value utilizing the full range of 0 to FFFFFFFFFFFFFFh. The most significant byte is ";
CM_ SG_ 2631728925 Antitheft_Encryption_Seed_Presen "Description:Indicates the presence of the encryption seed random number. 00b = Random number is not present 01b = Random number is present 10b = Error 11b = Not available
Note: Parsed from J1939DA.";
CM_ SG_ 2631728925 Antitheft_Password_Valid_Indicat "Description:Indicates the presence of a validated password. 00b = Password is not a validated password 01b = Password is a validated password 10b = Error 11b = Not available
Note: Parsed from J1939DA.";
CM_ SG_ 2631728925 Antitheft_Modify_Password_States "Description:This parameter is used to indicate whether a password request was successfully performed, or if the request could not be perform due to system constraints or if the request was not a valid request. 00b = Ok 01";
CM_ SG_ 2631728925 Antitheft_Component_Status_State "Description:Indicates whether or not the component can be started. 00b = Unlocked 01b = Locked 10b = Blocked 11b = Not defined 00b - Unlocked = This state indicates that the component can be started without the end user b";
CM_ BO_ 2566877469 "Name: pCluster Status 1
Description: Parsed from -014. ";
CM_ SG_ 2566877469 pTemperature_Units_Selected "Description: Active display temperature units beased on user selection or auto-configuration. ";
CM_ SG_ 2566877469 pTPMS_Learning_Status "Description: Indicates the status of the tire pressure monitoring sensor learning process. ";
CM_ SG_ 2566877469 pPressure_Units_Selected "Description: Active display pressure units beased on user selection or auto-configuration. ";
CM_ SG_ 2566877469 pHigh_Res_Trip_2_Distance "Description: Secondary distance travled during all or part of a journey.
Could not parse SPN data type, please add:Type: Measured
Parsed from -014. ";
CM_ SG_ 2566877469 pVolume_Units_Selected "Description: Active display volume units beased on user selection or auto-configuration. ";
CM_ SG_ 2566877469 pDisplay_Status "Description: Status of display. ";
CM_ SG_ 2566877469 pTime_Units_Selected "Description: Active display time units beased on user selection or auto-configuration. ";
CM_ SG_ 2566877469 pDistance_Units_Selected "Description: Active display distance units beased on user selection or auto-configuration. ";
CM_ BO_ 2633984541 "Name: pDrive System Status
Description: Parsed from -014. ";
CM_ SG_ 2633984541 pHeated_Grip_Enable "Description: This signal indicates the status of the Heated Grip Enable switch. ";
CM_ SG_ 2633984541 pUser_PIN_Access_Status "Description: This signal indicates if the display/gauge should show the User PIN screen, which allows the user the option of unlocking the vehicle security through the PIN code entry function.  ";
CM_ SG_ 2633984541 pActive_Descent_Control_ADC_Stat "Description: Broadcasting the status of the ADC (active indicates the solenoid is powered). ";
CM_ SG_ 2633984541 pCruise_Control_Set_Status "Description: Broadcasting the status of the Cruise Control Set Status for user indication  ";
CM_ SG_ 2633984541 pTether_Switch_Status "Description: Status of the Tether Switch ";
CM_ SG_ 2633984541 pHigh_Beam_Indicator_Status "Description: Broadcasting the status of the high beam headlight for user indication. ";
CM_ SG_ 2633984541 pLow_Fuel_Indicator_Status "Description: Broadcasting the status of the fuel level for user indication. ";
CM_ SG_ 2633984541 pHeated_Grips_Percentage "Description: Heated Grips Percent On, 0% is Off and 100% is the maximum heat
Could not parse SPN data type, please add:Type: Status
Parsed from -014. ";
CM_ SG_ 2633984541 pSide_Stand_Status "Description: Position of the side stand position when installed on a vehicle. ";
CM_ SG_ 2633984541 pTurf_Mode_Requested "Description: Broadcasting the status of the users request for TURF mode ";
CM_ SG_ 2633984541 pEngine_Idle_Shutdown_Timer "Description: This signal indicates the the amount of time left before the engine is shutdown due to the unattended vehicle engine idle shutdown function.
10-bit Timer:
0 &ndash; 1021 seconds
1022 - Error
1023 - Not Availab";
CM_ SG_ 2633984541 Operator_Not_in_Operating_Statio "Description: The Operator Presence Detection System indicates the operator is not in the correct operating station. ";
CM_ SG_ 2633984541 pAWD_Mode_Requested "Description: Broadcasting the status of the users request for AWD mode ";
CM_ SG_ 2633984541 pHeated_Grips_Up_Switch_Status "Description: This signal indicates the status of the Heated Grip Up switch. ";
CM_ SG_ 2633984541 pTreadle_Neutral_Status "Description: Broadcasting the status of the switch indicating the treadle is/is not in the Neutral position.  ";
CM_ SG_ 2633984541 pHeated_Grips_Down_Switch_Status "Description: This signal indicates the status of the Heated Grip Down switch. ";
CM_ SG_ 2633984541 pPark_Brake_Indicator_Status "Description: Broadcasting the status of the park brake for user indication ";
CM_ SG_ 2633984541 pRWD_Mode_Requested "Description: Broadcasting the status of the users request for RWD mode ";
CM_ SG_ 2633984541 pSeat_Belt_Indicator_Status "Description: Broadcasting the status of the seat belt for user indication ";
CM_ SG_ 2633984541 pSecurity_Light_Immobilizer_Stat "Description: Broadcasting the status of the security system for user indication.  ";
CM_ SG_ 2633984541 ECU_Security_Status "Description: Security Status of an ECU. ";
CM_ SG_ 2633984541 pActive_Decent_Control_ADC_Mode_ "Description: Broadcasting the status of the users request for ADC mode ";
CM_ SG_ 2633984541 pTreadle_Reverse_Status "Description: Broadcasting the status of the switch indicating the treadle is/is not in the Reverse position.  ";
CM_ BO_ 2566834717 "Name: Active Diagnostic Trouble Codes
Description:DM1 provides diagnostic lamp status and Diagnostic Trouble Codes (DTCs). Together, the lamp and DTC information
convey the diagnostic condition of the transmitting electronic component to other componen";
CM_ SG_ 2566834717 Flash_Malfunction_Indicator_Lamp "Description:This parameter provides the capability to flash the MIL. For OBD systems which are required to flash the SPN for specific malfunctions shall use the “slow flash” rate. 
See J1939-73 for complete reference
Pa";
CM_ SG_ 2566834717 Malfunction_Indicator_Lamp_Statu "Description:Used to relay only emissions-related trouble code information. This lamp is only illuminated when there is an emission-related trouble code active.
See J1939-71 for complete reference

Parsed from -014.";
CM_ SG_ 2566834717 Red_Stop_Lamp_Status "Description:Used to relay trouble code information that is of a severe enough condition that it warrants stopping the vehicle.
See J1939-71 for complete reference

Parsed from -014.";
CM_ SG_ 2566834717 Amber_Warning_Lamp_Status "Description:Used to relay trouble code information that is reporting a problem with the vehicle system but the vehicle need not be immediately stopped.
See J1939-71 for complete reference

Parsed from -014.";
CM_ SG_ 2566834717 Flash_Red_Stop_Lamp_RSL "Description:This parameter provides the capability to flash the RSL.
See J1939-73 for complete reference
Parsed from -014.";
CM_ SG_ 2566834717 Flash_Amber_Warning_Lamp_AWL "Description:This parameter provides the capability to flash the AWL. 
See J1939-73 for complete reference
Parsed from -014.";
CM_ SG_ 2566834717 Flash_Protect_Lamp "Description:This parameter provides the capability to flash the protect lamp. 
See J1939-73 for complete reference
Parsed from -014.";
CM_ SG_ 2566834717 Protect_Lamp_Status "Description:Used to relay trouble code information that is reporting a problem with a vehicle system that is most probably not electronic subsystem related. For instance, engine coolant temperature is exceeding its prescribed temperat";
CM_ SG_ 2566834717 DTC_1 "Description:This signal is a combination of 4 SPNs. To decode this signal, navigate to MCS tools.
Byte: 1 bits 8-1 SPN, 8 least significant bits of SPN (most significant at bit 8, SPN 1214)
Byte: 2 bits 8-1 SPN, second byte of SPN (most significa";
CM_ SG_ 2566834717 DTC_2 "Description:This signal is a combination of 4 SPNs. To decode this signal, navigate to MCS tools.
Byte: 1 bits 8-1 SPN, 8 least significant bits of SPN (most significant at bit 8, SPN 1214)
Byte: 2 bits 8-1 SPN, second byte of SPN (most significa";
CM_ SG_ 2566834717 DTC_3 "Description:This signal is a combination of 4 SPNs. To decode this signal, navigate to MCS tools.
Byte: 1 bits 8-1 SPN, 8 least significant bits of SPN (most significant at bit 8, SPN 1214)
Byte: 2 bits 8-1 SPN, second byte of SPN (most significa";
CM_ SG_ 2566834717 DTC_4 "Description:This signal is a combination of 4 SPNs. To decode this signal, navigate to MCS tools.
Byte: 1 bits 8-1 SPN, 8 least significant bits of SPN (most significant at bit 8, SPN 1214)
Byte: 2 bits 8-1 SPN, second byte of SPN (most significa";
CM_ SG_ 2566834717 DTC_5 "Description:This signal is a combination of 4 SPNs. To decode this signal, navigate to MCS tools.
Byte: 1 bits 8-1 SPN, 8 least significant bits of SPN (most significant at bit 8, SPN 1214)
Byte: 2 bits 8-1 SPN, second byte of SPN (most significa";
CM_ SG_ 2566834717 DTC_6 "Description:This signal is a combination of 4 SPNs. To decode this signal, navigate to MCS tools.
Byte: 1 bits 8-1 SPN, 8 least significant bits of SPN (most significant at bit 8, SPN 1214)
Byte: 2 bits 8-1 SPN, second byte of SPN (most significa";
CM_ SG_ 2566834717 DTC_7 "Description:This signal is a combination of 4 SPNs. To decode this signal, navigate to MCS tools.
Byte: 1 bits 8-1 SPN, 8 least significant bits of SPN (most significant at bit 8, SPN 1214)
Byte: 2 bits 8-1 SPN, second byte of SPN (most significa";
CM_ SG_ 2566834717 DTC_8 "Description:This signal is a combination of 4 SPNs. To decode this signal, navigate to MCS tools.
Byte: 1 bits 8-1 SPN, 8 least significant bits of SPN (most significant at bit 8, SPN 1214)
Byte: 2 bits 8-1 SPN, second byte of SPN (most significa";
CM_ SG_ 2566834717 DTC_9 "Description:This signal is a combination of 4 SPNs. To decode this signal, navigate to MCS tools.
Byte: 1 bits 8-1 SPN, 8 least significant bits of SPN (most significant at bit 8, SPN 1214)
Byte: 2 bits 8-1 SPN, second byte of SPN (most significa";
CM_ SG_ 2566834717 DTC_10 "Description:This signal is a combination of 4 SPNs. To decode this signal, navigate to MCS tools.
Byte: 1 bits 8-1 SPN, 8 least significant bits of SPN (most significant at bit 8, SPN 1214)
Byte: 2 bits 8-1 SPN, second byte of SPN (most signific";
CM_ BO_ 2631794461 "Name: Anti-Theft Request
Description: Parsed from -014. ";
CM_ SG_ 2631794461 Antitheft_Desired_Exit_Mode_Stat "Description:This parameter is used to specify the desired triggers that are to be used by the component in deciding when to transition to the Locked state. 00b = Lock_Upon_Operator_Request 01b = Lock_When_Key_Off 10b = No";
CM_ SG_ 2631794461 Antitheft_Encryption_Indicator_S "Description:This parameter is used to indicate if a random number seed is being requested, or if an encrypted password is being provided to the component. 00b = Encryption_Seed_Request 01b = Encrypted_Code_Present 10b = N";
CM_ SG_ 2631794461 Antitheft_Command_States "Description:This parameter is used to identify the specific requests being sent to the component. 000b = Add_Password 001b = Delete_Password 010b = Change_Password 011b = Lock_or_Unlock 100b = Check_Status 101b = Login 110b = Not";
CM_ SG_ 2631794461 Antitheft_Password_Representatio "Description:This parameter is the seven byte numeric code (i.e., 'encrypted password' or 'key') that is generated based on the encryption algorithm, the password supplied by the end user, and the random number seed given ";
CM_ BO_ 2566845469 "Name: Tire Condition
Description: Parsed from -014. ";
CM_ SG_ 2566845469 Tire_Temperature "Description:Temperature at the surface of the tire sidewall.
Note: Parsed from J1939DA.";
CM_ SG_ 2566845469 Tire_Pressure "Description:Pressure at which air is contained in cavity formed by tire and rim.
Note: Parsed from J1939DA.";
CM_ SG_ 2566845469 Tire_Location "Description:Identifies which tire is associated with the parametric data in this PG. The low order 4 bits represent a position number, counting left to right when facing in the direction of normal vehicle travel (forward). The high order 4 ";
CM_ BO_ 2365523485 "Name: pModule Control Message
Description: Parsed from -014. ";
CM_ SG_ 2365523485 pModule_Control_Applied_State "Description: Indicates the requester&rsquo;s command to control wake state of other modules. Partial Wakeup and Full Wakeup are to be defined per each module.

 ";
CM_ SG_ 2365523485 pModule_Control_Command_Destinat "Description: Indicates which source address the requester is commanding. Destination address FFh is used to indicate that all source addresses should obey the Module Control Command State signal. FFFFh indicates &ldquo;no";
CM_ SG_ 2365523485 pModule_Control_Command_State "Description: Indicates the requester&rsquo;s command to control wake state of other modules. Each state to be defined per each module. ";
CM_ SG_ 2365523485 pModule_Control_Message_Checksum "Description: Message checksum that is calculated as follows:
Intermediate Checksum =
Byte1 + Byte2 + Byte3 + Byte4 + Byte5 + Byte6 + Byte7 + (8.1 Nibble & 0x0F) + Message ID Low Byte + Message ID Mid Low Byte + Message ";
CM_ BO_ 2566834973 "Name: Previously Active Diagnostic Trouble Codes
Description:When supported, DM2 provides a list of all previously active (previously detected) DTCs. The list of DTCs must include
all the emissions-related previously active DTCs provided in the device’";
CM_ SG_ 2566834973 Protect_Lamp_Status "Description:Used to relay trouble code information that is reporting a problem with a vehicle system that is most probably not electronic subsystem related. For instance, engine coolant temperature is exceeding its prescribed temperat";
CM_ SG_ 2566834973 Amber_Warning_Lamp_Status "Description:Used to relay trouble code information that is reporting a problem with the vehicle system but the vehicle need not be immediately stopped.
See J1939-71 for complete reference

Parsed from -014.";
CM_ SG_ 2566834973 Red_Stop_Lamp_Status "Description:Used to relay trouble code information that is of a severe enough condition that it warrants stopping the vehicle.
See J1939-71 for complete reference

Parsed from -014.";
CM_ SG_ 2566834973 Malfunction_Indicator_Lamp_Statu "Description:Used to relay only emissions-related trouble code information. This lamp is only illuminated when there is an emission-related trouble code active.
See J1939-71 for complete reference

Parsed from -014.";
CM_ SG_ 2566834973 Flash_Protect_Lamp "Description:This parameter provides the capability to flash the protect lamp. 
See J1939-73 for complete reference
Parsed from -014.";
CM_ SG_ 2566834973 Flash_Amber_Warning_Lamp_AWL "Description:This parameter provides the capability to flash the AWL. 
See J1939-73 for complete reference
Parsed from -014.";
CM_ SG_ 2566834973 Flash_Red_Stop_Lamp_RSL "Description:This parameter provides the capability to flash the RSL.
See J1939-73 for complete reference
Parsed from -014.";
CM_ SG_ 2566834973 Flash_Malfunction_Indicator_Lamp "Description:This parameter provides the capability to flash the MIL. For OBD systems which are required to flash the SPN for specific malfunctions shall use the “slow flash” rate. 
See J1939-73 for complete reference
Pa";
CM_ SG_ 2566834973 DTC_1 "Description:This signal is a combination of 4 SPNs. To decode this signal, navigate to MCS tools.
Byte: 1 bits 8-1 SPN, 8 least significant bits of SPN (most significant at bit 8, SPN 1214)
Byte: 2 bits 8-1 SPN, second byte of SPN (most significa";
CM_ SG_ 2566834973 DTC_2 "Description:This signal is a combination of 4 SPNs. To decode this signal, navigate to MCS tools.
Byte: 1 bits 8-1 SPN, 8 least significant bits of SPN (most significant at bit 8, SPN 1214)
Byte: 2 bits 8-1 SPN, second byte of SPN (most significa";
CM_ SG_ 2566834973 DTC_3 "Description:This signal is a combination of 4 SPNs. To decode this signal, navigate to MCS tools.
Byte: 1 bits 8-1 SPN, 8 least significant bits of SPN (most significant at bit 8, SPN 1214)
Byte: 2 bits 8-1 SPN, second byte of SPN (most significa";
CM_ SG_ 2566834973 DTC_4 "Description:This signal is a combination of 4 SPNs. To decode this signal, navigate to MCS tools.
Byte: 1 bits 8-1 SPN, 8 least significant bits of SPN (most significant at bit 8, SPN 1214)
Byte: 2 bits 8-1 SPN, second byte of SPN (most significa";
CM_ SG_ 2566834973 DTC_5 "Description:This signal is a combination of 4 SPNs. To decode this signal, navigate to MCS tools.
Byte: 1 bits 8-1 SPN, 8 least significant bits of SPN (most significant at bit 8, SPN 1214)
Byte: 2 bits 8-1 SPN, second byte of SPN (most significa";
CM_ SG_ 2566834973 DTC_6 "Description:This signal is a combination of 4 SPNs. To decode this signal, navigate to MCS tools.
Byte: 1 bits 8-1 SPN, 8 least significant bits of SPN (most significant at bit 8, SPN 1214)
Byte: 2 bits 8-1 SPN, second byte of SPN (most significa";
CM_ SG_ 2566834973 DTC_7 "Description:This signal is a combination of 4 SPNs. To decode this signal, navigate to MCS tools.
Byte: 1 bits 8-1 SPN, 8 least significant bits of SPN (most significant at bit 8, SPN 1214)
Byte: 2 bits 8-1 SPN, second byte of SPN (most significa";
CM_ SG_ 2566834973 DTC_8 "Description:This signal is a combination of 4 SPNs. To decode this signal, navigate to MCS tools.
Byte: 1 bits 8-1 SPN, 8 least significant bits of SPN (most significant at bit 8, SPN 1214)
Byte: 2 bits 8-1 SPN, second byte of SPN (most significa";
CM_ SG_ 2566834973 DTC_9 "Description:This signal is a combination of 4 SPNs. To decode this signal, navigate to MCS tools.
Byte: 1 bits 8-1 SPN, 8 least significant bits of SPN (most significant at bit 8, SPN 1214)
Byte: 2 bits 8-1 SPN, second byte of SPN (most significa";
CM_ SG_ 2566834973 DTC_10 "Description:This signal is a combination of 4 SPNs. To decode this signal, navigate to MCS tools.
Byte: 1 bits 8-1 SPN, 8 least significant bits of SPN (most significant at bit 8, SPN 1214)
Byte: 2 bits 8-1 SPN, second byte of SPN (most signific";
CM_ BO_ 2432656669 "Name: pOperator Switch Status
Description: Parsed from -014. ";
CM_ SG_ 2432656669 Key_Fob_Unlock_Button_Status "Description: These group of SPN&rsquo;s contain the information for the Operator Switches. See PGN 65380 breakdown for definition of each button. ";
CM_ SG_ 2432656669 Homelink_2 "Description: These group of SPN&rsquo;s contain the information for the Operator Switches. See PGN 65380 breakdown for definition of each button. ";
CM_ SG_ 2432656669 Side_Stand_Switch "Description: ";
CM_ SG_ 2432656669 Key_Fob_Lock_Button_Status "Description: These group of SPN&rsquo;s contain the information for the Operator Switches. See PGN 65380 breakdown for definition of each button. ";
CM_ SG_ 2432656669 Windshield__2_Down "Description: These group of SPN&rsquo;s contain the information for the Operator Switches. See PGN 65380 breakdown for definition of each button. ";
CM_ SG_ 2432656669 Turn__3_Cancel "Description: These group of SPN&rsquo;s contain the information for the Operator Switches. See PGN 65380 breakdown for definition of each button. ";
CM_ SG_ 2432656669 Reverse "Description: These group of SPN&rsquo;s contain the information for the Operator Switches. See PGN 65380 breakdown for definition of each button. ";
CM_ SG_ 2432656669 Hazard "Description: These group of SPN&rsquo;s contain the information for the Operator Switches. See PGN 65380 breakdown for definition of each button. ";
CM_ SG_ 2432656669 Homelink_1 "Description: These group of SPN&rsquo;s contain the information for the Operator Switches. See PGN 65380 breakdown for definition of each button. ";
CM_ SG_ 2432656669 Windshield__1_Up "Description: These group of SPN&rsquo;s contain the information for the Operator Switches. See PGN 65380 breakdown for definition of each button. ";
CM_ SG_ 2432656669 Front_Brake_Switch "Description: Indicates the status of the front brake switch ";
CM_ SG_ 2432656669 Instrument_Cluster_Control__2 "Description: These group of SPN&rsquo;s contain the information for the Operator Switches. See PGN 65380 breakdown for definition of each button. ";
CM_ SG_ 2432656669 Chassis_Unlock_Button_Status "Description: These group of SPN&rsquo;s contain the information for the Operator Switches. See PGN 65380 breakdown for definition of each button. ";
CM_ SG_ 2432656669 Power_Button "Description: These group of SPN&rsquo;s contain the information for the Operator Switches. See PGN 65380 breakdown for definition of each button. ";
CM_ SG_ 2432656669 RunStop_Switch "Description: These group of SPN&rsquo;s contain the information for the Operator Switches. See PGN 65380 breakdown for definition of each button. ";
CM_ SG_ 2432656669 Headlamp__2_High "Description: These group of SPN&rsquo;s contain the information for the Operator Switches. See PGN 65380 breakdown for definition of each button. ";
CM_ SG_ 2432656669 Instrument_Cluster_Control__1 "Description: These group of SPN&rsquo;s contain the information for the Operator Switches. See PGN 65380 breakdown for definition of each button. ";
CM_ SG_ 2432656669 Clutch_Switch "Description: These group of SPN&rsquo;s contain the information for the Operator Switches. See PGN 65380 breakdown for definition of each button. ";
CM_ SG_ 2432656669 Start "Description: These group of SPN&rsquo;s contain the information for the Operator Switches. See PGN 65380 breakdown for definition of each button. ";
CM_ SG_ 2432656669 Headlamp__3_Driving "Description: These group of SPN&rsquo;s contain the information for the Operator Switches. See PGN 65380 breakdown for definition of each button. ";
CM_ SG_ 2432656669 Cruise__2_Set "Description: These group of SPN&rsquo;s contain the information for the Operator Switches. See PGN 65380 breakdown for definition of each button. ";
CM_ SG_ 2432656669 Windshield_Wiper "Description: These group of SPN&rsquo;s contain the information for the Operator Switches. See PGN 65380 breakdown for definition of each button. ";
CM_ SG_ 2432656669 Fog "Description: These group of SPN&rsquo;s contain the information for the Operator Switches. See PGN 65380 breakdown for definition of each button. ";
CM_ SG_ 2432656669 Cruise__3_Accel "Description: These group of SPN&rsquo;s contain the information for the Operator Switches. See PGN 65380 breakdown for definition of each button. ";
CM_ SG_ 2432656669 Horn "Description: These group of SPN&rsquo;s contain the information for the Operator Switches. See PGN 65380 breakdown for definition of each button. ";
CM_ SG_ 2432656669 Turn__2_Right "Description: These group of SPN&rsquo;s contain the information for the Operator Switches. See PGN 65380 breakdown for definition of each button. ";
CM_ SG_ 2432656669 Cruise__1_On "Description: These group of SPN&rsquo;s contain the information for the Operator Switches. See PGN 65380 breakdown for definition of each button. ";
CM_ SG_ 2432656669 Turn__1_Left "Description: These group of SPN&rsquo;s contain the information for the Operator Switches. See PGN 65380 breakdown for definition of each button. ";
CM_ SG_ 2432656669 Throttle_Safety_Switch__1 "Description: These group of SPN&rsquo;s contain the information for the Operator Switches. See PGN 65380 breakdown for definition of each button. ";
CM_ SG_ 2432656669 Headlamp__1_Low "Description: These group of SPN&rsquo;s contain the information for the Operator Switches. See PGN 65380 breakdown for definition of each button. ";
CM_ SG_ 2432656669 Chassis_Lock_Switch_Status "Description:Created due to CMS fault code using this SPN";
CM_ SG_ 2432656669 Fuel_Door_Unlock_Button_Status "Description:Displays the status of the Fuel Door Unlock button. See PGN 65380 breakdown for the definition of each button.";
BA_DEF_ SG_  "SigType" ENUM  "Default","Range","RangeSigned","ASCII","Discrete","Control","ReferencePGN","DTC","StringDelimiter","StringLength","StringLengthControl";
BA_DEF_ SG_  "GenSigEVName" STRING ;
BA_DEF_ SG_  "GenSigILSupport" ENUM  "No","Yes";
BA_DEF_ SG_  "GenSigSendType" ENUM  "Cyclic","OnWrite","OnWriteWithRepetition","OnChange","OnChangeWithRepetition","IfActive","IfActiveWithRepetition","NoSigSendType";
BA_DEF_ BO_  "GenMsgCycleTimeFast" INT 0 3600000;
BA_DEF_ BO_  "GenMsgILSupport" ENUM  "No","Yes";
BA_DEF_ BO_  "GenMsgSendType" ENUM  "cyclic","spontaneous","cyclicIfActive","spontaneousWithDelay","cyclicAndSpontaneous","cyclicAndSpontaneousWithDelay","spontaneousWithRepetition","cyclicIfActiveAndSpontaneousWD","OnRequest";
BA_DEF_ BO_  "GenMsgRequestable" INT 0 1;
BA_DEF_ BO_  "GenMsgCycleTime" INT 0 3600000;
BA_DEF_ SG_  "SPN" INT 0 524287;
BA_DEF_ BO_  "VFrameFormat" ENUM  "StandardCAN","ExtendedCAN","reserved","J1939PG";
BA_DEF_DEF_  "SigType" "Default";
BA_DEF_DEF_  "GenSigEVName" "Env@Nodename_@Signame";
BA_DEF_DEF_  "GenSigILSupport" "Yes";
BA_DEF_DEF_  "GenSigSendType" "NoSigSendType";
BA_DEF_DEF_  "GenMsgCycleTimeFast" 0;
BA_DEF_DEF_  "GenMsgILSupport" "Yes";
BA_DEF_DEF_  "GenMsgSendType" "noMsgSendType";
BA_DEF_DEF_  "GenMsgRequestable" 1;
BA_DEF_DEF_  "GenMsgCycleTime" 0;
BA_DEF_DEF_  "SPN" 0;
BA_DEF_DEF_  "VFrameFormat" "J1939PG";
BA_ "SPN" SG_ 2566884352 Message_Checksum 4207;
BA_ "SPN" SG_ 2566884352 pEstimated_Torque 520246;
BA_ "SPN" SG_ 2566884352 pCurrent_RPM_Rated_Torque 520245;
BA_ "SPN" SG_ 2566884352 Brake_Switch 597;
BA_ "SPN" SG_ 2566884352 Message_Counter 4206;
BA_ "SPN" SG_ 2566876928 pSecondary_Air_Valve_Control 524083;
BA_ "SPN" SG_ 2566886400 Engine_Cylinder_1_Ignition_Timin 520534;
BA_ "SPN" SG_ 2566886400 Engine_Cylinder_2_Ignition_Timin 520535;
BA_ "SPN" SG_ 2566886400 High_Range_Engine_Percent_Load 520532;
BA_ "SPN" SG_ 2566886400 Desired_Lambda 520533;
BA_ "SPN" SG_ 2566886912 pBoundary_Status_Message 520635;
BA_ "SPN" SG_ 2566886912 pVehicle_EnableDisable 520637;
BA_ "SPN" SG_ 2566886912 pFleet_Management_Default_Vehicl 520638;
BA_ "SPN" SG_ 2566886912 pUser_Authentication_Status 520636;
BA_ "SPN" SG_ 2566887936 pAntiTheft_Component_Status_Indi 521196;
BA_ "SPN" SG_ 2566887936 pAntiTheft_Command_States 521201;
BA_ "SPN" SG_ 2566887936 pAntiTheft_Pin_Presence 516227;
BA_ "SPN" SG_ 2566887936 pAntiTheft_Pin_Parameter 516228;
BA_ "SPN" SG_ 2348941056 Transmission_Mode_3 1854;
BA_ "SPN" SG_ 2348941056 Transmission_Requested_Gear 525;
BA_ "SPN" SG_ 2348941056 Transmission_Mode_1 1852;
BA_ "SPN" SG_ 2348941056 Transmission_Mode_2 1853;
BA_ "SPN" SG_ 2348941056 Requested_Percent_Clutch_Slip 684;
BA_ "SPN" SG_ 2348941056 Transmission_Gear_Shift_Inhibit_ 681;
BA_ "SPN" SG_ 2348941056 Transmission_Shift_Selector_Disp 2985;
BA_ "SPN" SG_ 2348941056 Disengage_Differential_Lock_Requ 685;
BA_ "SPN" SG_ 2348941056 Disengage_Differential_Lock_Requ 689;
BA_ "SPN" SG_ 2348941056 Disengage_Differential_Lock_Requ 687;
BA_ "SPN" SG_ 2348941056 Transmission_Torque_Converter_Lo 682;
BA_ "SPN" SG_ 2348941056 Transmission_Mode_4 1855;
BA_ "SPN" SG_ 2348941056 Disengage_Driveline_Request 683;
BA_ "SPN" SG_ 2348941056 pTransmission_Mode_5_Request 523998;
BA_ "SPN" SG_ 2365530112 pMessage_Counter 520564;
BA_ "SPN" SG_ 2365530112 pRequested_Engine_TorqueTorque_L 520562;
BA_ "SPN" SG_ 2365530112 pEngine_Control_Mode 520560;
BA_ "SPN" SG_ 2365530112 pRequested_Engine_SpeedSpeed_Lim 520563;
BA_ "SPN" SG_ 2365530112 WheelBased_Vehicle_Speed 84;
BA_ "SPN" SG_ 2365530112 pEngine_Control_Requestor 520561;
BA_ "SPN" SG_ 2365530112 pMessage_Checksum 520565;
BA_ "SPN" SG_ 2365532416 pMessageCounter 516164;
BA_ "SPN" SG_ 2365532416 pAMTPumpStatus 516193;
BA_ "SPN" SG_ 2365532416 pMessageChecksum 516165;
BA_ "SPN" SG_ 2365532416 pEngine_Control_Shutdown_Request 516163;
BA_ "SPN" SG_ 2365532416 pAMTHydraulicPressure 516250;
BA_ "SPN" SG_ 2365532416 pAMTClutchStatus 516192;
BA_ "SPN" SG_ 2348941061 Transmission_Mode_3 1854;
BA_ "SPN" SG_ 2348941061 Transmission_Requested_Gear 525;
BA_ "SPN" SG_ 2348941061 Transmission_Mode_1 1852;
BA_ "SPN" SG_ 2348941061 Transmission_Mode_2 1853;
BA_ "SPN" SG_ 2348941061 Requested_Percent_Clutch_Slip 684;
BA_ "SPN" SG_ 2348941061 Transmission_Gear_Shift_Inhibit_ 681;
BA_ "SPN" SG_ 2348941061 Transmission_Shift_Selector_Disp 2985;
BA_ "SPN" SG_ 2348941061 Disengage_Differential_Lock_Requ 685;
BA_ "SPN" SG_ 2348941061 Disengage_Differential_Lock_Requ 689;
BA_ "SPN" SG_ 2348941061 Disengage_Differential_Lock_Requ 687;
BA_ "SPN" SG_ 2348941061 Transmission_Torque_Converter_Lo 682;
BA_ "SPN" SG_ 2348941061 Transmission_Mode_4 1855;
BA_ "SPN" SG_ 2348941061 Disengage_Driveline_Request 683;
BA_ "SPN" SG_ 2348941061 pTransmission_Mode_5_Request 523998;
BA_ "SPN" SG_ 2348875531 Engine_Requested_Torque_Fraction 4191;
BA_ "SPN" SG_ 2348875531 Engine_Override_Control_Mode 695;
BA_ "SPN" SG_ 2348875531 Engine_Requested_SpeedSpeed_Limi 898;
BA_ "SPN" SG_ 2348875531 Engine_Requested_Speed_Control_C 696;
BA_ "SPN" SG_ 2348875531 TSC1_Control_Purpose 3350;
BA_ "SPN" SG_ 2348875531 Override_Control_Mode_Priority 897;
BA_ "SPN" SG_ 2348875531 TSC1_Transmission_Rate 3349;
BA_ "SPN" SG_ 2348875531 Engine_Requested_TorqueTorque_Li 518;
BA_ "SPN" SG_ 2365449739 Hydraulic_Brake_Pressure_Warning 2585;
BA_ "SPN" SG_ 2365449739 Hydraulic_Brake_Pressure_Supply_ 2583;
BA_ "SPN" SG_ 2365449739 Hydraulic_Brake_Pressure_Supply_ 2582;
BA_ "SPN" SG_ 2365449739 Hydraulic_Brake_Pressure_Warning 2584;
BA_ "SPN" SG_ 2365449739 Hydraulic_Brake_Pressure_Circuit 2580;
BA_ "SPN" SG_ 2365449739 Hydraulic_Brake_Pressure_Circuit 2581;
BA_ "SPN" SG_ 2365449739 Hydraulic_Brake_Fluid_Level_Swit 2931;
BA_ "SPN" SG_ 2565867787 Lateral_Acceleration 1809;
BA_ "SPN" SG_ 2565867787 Longitudinal_Acceleration 1810;
BA_ "SPN" SG_ 2565867787 Yaw_Rate 1808;
BA_ "SPN" SG_ 2565867787 Steering_Wheel_Angle 1807;
BA_ "SPN" SG_ 2565867787 Steering_Wheel_Angle_Sensor_Type 1812;
BA_ "SPN" SG_ 2565867787 Steering_Wheel_Turn_Counter 1811;
BA_ "SPN" SG_ 2349465355 Static_Roll_Angle 5582;
BA_ "SPN" SG_ 2565865739 ABS_Offroad_Switch 575;
BA_ "SPN" SG_ 2565865739 ABSEBS_Amber_Warning_Signal_Powe 1438;
BA_ "SPN" SG_ 2565865739 ASR_Brake_Control_Active 562;
BA_ "SPN" SG_ 2565865739 Source_Address_of_Controlling_De 1481;
BA_ "SPN" SG_ 2565865739 EBS_Red_Warning_Signal 1439;
BA_ "SPN" SG_ 2565865739 ASR_Engine_Control_Active 561;
BA_ "SPN" SG_ 2565865739 AntiLock_Braking_ABS_Active 563;
BA_ "SPN" SG_ 2565865739 ATCASR_Information_Signal 1793;
BA_ "SPN" SG_ 2565865739 ABS_Fully_Operational 1243;
BA_ "SPN" SG_ 2565865739 Traction_Control_Override_Switch 1238;
BA_ "SPN" SG_ 2566803211 ROP_Engine_Control_active 1816;
BA_ "SPN" SG_ 2566803211 VDC_brake_light_request 1815;
BA_ "SPN" SG_ 2566803211 YC_Brake_Control_active 1819;
BA_ "SPN" SG_ 2566803211 VDC_Information_Signal 1813;
BA_ "SPN" SG_ 2566803211 ROP_Brake_Control_active 1818;
BA_ "SPN" SG_ 2566803211 VDC_Fully_Operational 1814;
BA_ "SPN" SG_ 2566834955 Protect_Lamp_Status 987;
BA_ "SPN" SG_ 2566834955 Amber_Warning_Lamp_Status 624;
BA_ "SPN" SG_ 2566834955 Red_Stop_Lamp_Status 623;
BA_ "SPN" SG_ 2566834955 Malfunction_Indicator_Lamp_Statu 1213;
BA_ "SPN" SG_ 2566834955 Flash_Protect_Lamp 3041;
BA_ "SPN" SG_ 2566834955 Flash_Amber_Warning_Lamp_AWL 3040;
BA_ "SPN" SG_ 2566834955 Flash_Red_Stop_Lamp_RSL 3039;
BA_ "SPN" SG_ 2566834955 Flash_Malfunction_Indicator_Lamp 3038;
BA_ "SPN" SG_ 2566834955 DTC_1 999990;
BA_ "SPN" SG_ 2566834955 DTC_2 999991;
BA_ "SPN" SG_ 2566834955 DTC_3 999992;
BA_ "SPN" SG_ 2566834955 DTC_4 999993;
BA_ "SPN" SG_ 2566834955 DTC_5 999994;
BA_ "SPN" SG_ 2566834955 DTC_6 999995;
BA_ "SPN" SG_ 2566834955 DTC_7 999996;
BA_ "SPN" SG_ 2566834955 DTC_8 999997;
BA_ "SPN" SG_ 2566834955 DTC_9 999998;
BA_ "SPN" SG_ 2566834955 DTC_10 999999;
BA_ "SPN" SG_ 2566834699 Flash_Malfunction_Indicator_Lamp 3038;
BA_ "SPN" SG_ 2566834699 Malfunction_Indicator_Lamp_Statu 1213;
BA_ "SPN" SG_ 2566834699 Red_Stop_Lamp_Status 623;
BA_ "SPN" SG_ 2566834699 Amber_Warning_Lamp_Status 624;
BA_ "SPN" SG_ 2566834699 Flash_Red_Stop_Lamp_RSL 3039;
BA_ "SPN" SG_ 2566834699 Flash_Amber_Warning_Lamp_AWL 3040;
BA_ "SPN" SG_ 2566834699 Flash_Protect_Lamp 3041;
BA_ "SPN" SG_ 2566834699 Protect_Lamp_Status 987;
BA_ "SPN" SG_ 2566834699 DTC_1 999990;
BA_ "SPN" SG_ 2566834699 DTC_2 999991;
BA_ "SPN" SG_ 2566834699 DTC_3 999992;
BA_ "SPN" SG_ 2566834699 DTC_4 999993;
BA_ "SPN" SG_ 2566834699 DTC_5 999994;
BA_ "SPN" SG_ 2566834699 DTC_6 999995;
BA_ "SPN" SG_ 2566834699 DTC_7 999996;
BA_ "SPN" SG_ 2566834699 DTC_8 999997;
BA_ "SPN" SG_ 2566834699 DTC_9 999998;
BA_ "SPN" SG_ 2566834699 DTC_10 999999;
BA_ "SPN" SG_ 2566846219 Key_Switch_Battery_Potential 158;
BA_ "SPN" SG_ 2566846219 Alternator_Current 115;
BA_ "SPN" SG_ 2566846219 Charging_System_Potential_Voltag 167;
BA_ "SPN" SG_ 2566846219 SLI_Battery_1_Net_Current 114;
BA_ "SPN" SG_ 2566846219 Battery_Potential__Power_Input_1 168;
BA_ "SPN" SG_ 2365532427 pMessageCounter 516164;
BA_ "SPN" SG_ 2365532427 pAMTPumpStatus 516193;
BA_ "SPN" SG_ 2365532427 pMessageChecksum 516165;
BA_ "SPN" SG_ 2365532427 pEngine_Control_Shutdown_Request 516163;
BA_ "SPN" SG_ 2365532427 pAMTHydraulicPressure 516250;
BA_ "SPN" SG_ 2365532427 pAMTClutchStatus 516192;
BA_ "SPN" SG_ 2566831883 Relative_Speed_Rear_Axle_2_Right 910;
BA_ "SPN" SG_ 2566831883 Relative_Speed_Rear_Axle_1_Left_ 907;
BA_ "SPN" SG_ 2566831883 Relative_Speed_Front_Axle_Left_W 905;
BA_ "SPN" SG_ 2566831883 Relative_Speed_Rear_Axle_2_Left_ 909;
BA_ "SPN" SG_ 2566831883 Relative_Speed_Front_Axle_Right_ 906;
BA_ "SPN" SG_ 2566831883 Relative_Speed_Rear_Axle_1_Right 908;
BA_ "SPN" SG_ 2566831883 Front_Axle_Speed 904;
BA_ "SPN" SG_ 2566844683 Cruise_Control_Set_Speed 86;
BA_ "SPN" SG_ 2566844683 Cruise_Control_Active 595;
BA_ "SPN" SG_ 2566844683 Clutch_Switch 598;
BA_ "SPN" SG_ 2566844683 Brake_Switch 597;
BA_ "SPN" SG_ 2566844683 pCC_Message_Counter 524080;
BA_ "SPN" SG_ 2566844683 Cruise_Control_Pause_Switch 1633;
BA_ "SPN" SG_ 2566844683 Cruise_Control_Set_Switch 599;
BA_ "SPN" SG_ 2566844683 Two_Speed_Axle_Switch 69;
BA_ "SPN" SG_ 2566844683 Cruise_Control_Enable_Switch 596;
BA_ "SPN" SG_ 2566844683 pOdometer_Drive_Bit 523994;
BA_ "SPN" SG_ 2566844683 pCC_Checksum 524079;
BA_ "SPN" SG_ 2566844683 WheelBased_Vehicle_Speed 84;
BA_ "SPN" SG_ 2566844683 Cruise_Control_Resume_Switch 601;
BA_ "SPN" SG_ 2566844683 Cruise_Control_Accelerate_Switch 602;
BA_ "SPN" SG_ 2566844683 pCruise_Enable_Status 524108;
BA_ "SPN" SG_ 2566844683 Parking_Brake_Switch 70;
BA_ "SPN" SG_ 2566844683 Cruise_Control_Coast_Decelerate_ 600;
BA_ "SPN" SG_ 2365552395 pTotal_Torque_Output 524135;
BA_ "SPN" SG_ 2365552395 pRequested_Torque_Counter 524133;
BA_ "SPN" SG_ 2365552395 pRequested_Torque_Checksum 524134;
BA_ "SPN" SG_ 2365531915 pFront_Left_Wheel_Speed 520581;
BA_ "SPN" SG_ 2365531915 pWSBS_CRC 520580;
BA_ "SPN" SG_ 2365531915 pBrake_Switch_Status 520583;
BA_ "SPN" SG_ 2365531915 pDriven_Wheel_Speed 520578;
BA_ "SPN" SG_ 2365531915 pFront_Right_Wheel_Speed 520582;
BA_ "SPN" SG_ 2365531915 pWSBS_Rolling_Counter 520579;
BA_ "SPN" SG_ 2365536779 pABS_Mode_Status 516423;
BA_ "SPN" SG_ 2365536779 pESC_Mode_Status 516425;
BA_ "SPN" SG_ 2365536779 pABS_Transition_Status 516422;
BA_ "SPN" SG_ 2365536779 pTC_Mode_Status 516424;
BA_ "SPN" SG_ 2231336203 pActual_Braking_Application 520401;
BA_ "SPN" SG_ 2231336203 pEBC_Mode_Status 516426;
BA_ "SPN" SG_ 2231336203 Message_Counter 520402;
BA_ "SPN" SG_ 2231336203 Message_Checksum 520403;
BA_ "SPN" SG_ 2231336205 pActual_Braking_Application 520401;
BA_ "SPN" SG_ 2231336205 pEBC_Mode_Status 516426;
BA_ "SPN" SG_ 2231336205 Message_Counter 520402;
BA_ "SPN" SG_ 2231336205 Message_Checksum 520403;
BA_ "SPN" SG_ 2566877965 pEPS_Commanded_Var2 524113;
BA_ "SPN" SG_ 2566877965 pEPS_Commanded_Control_Mode 524111;
BA_ "SPN" SG_ 2566877965 pEPS_Commanded_Var1 524112;
BA_ "SPN" SG_ 2566846227 Key_Switch_Battery_Potential 158;
BA_ "SPN" SG_ 2566846227 Alternator_Current 115;
BA_ "SPN" SG_ 2566846227 Charging_System_Potential_Voltag 167;
BA_ "SPN" SG_ 2566846227 SLI_Battery_1_Net_Current 114;
BA_ "SPN" SG_ 2566846227 Battery_Potential__Power_Input_1 168;
BA_ "SPN" SG_ 2365547027 pEPS_Shaft_Velocity 524115;
BA_ "SPN" SG_ 2365547027 pEPS_Requested_Mode_Ack 520128;
BA_ "SPN" SG_ 2365547027 pEPS_SAS_Message_Counter 521212;
BA_ "SPN" SG_ 2365547027 pEPS_Shaft_Position 524114;
BA_ "SPN" SG_ 2365547027 pEPS_SAS_CRC8 521213;
BA_ "SPN" SG_ 2365547027 pEPS_Active_Mode 524116;
BA_ "SPN" SG_ 2566874899 pSteering_Velocity_EPAS_Steering 524006;
BA_ "SPN" SG_ 2566874899 pGeneratedCurrent 524004;
BA_ "SPN" SG_ 2566874899 pSteerAssistTq 524003;
BA_ "SPN" SG_ 2566874899 pSensed_Input_Steering_Torque 524002;
BA_ "SPN" SG_ 2566874899 pVTemp_EPAS_Steering 524005;
BA_ "SPN" SG_ 2365551635 pEPS_Operation_Status 524117;
BA_ "SPN" SG_ 2365551635 pEPS_SAS_Calibrated 524118;
BA_ "SPN" SG_ 2365551635 pEPS_Active_Mode 524116;
BA_ "SPN" SG_ 2365551635 pEPS_Shaft_Position 524114;
BA_ "SPN" SG_ 2365551635 pEPS_Shaft_Velocity 524115;
BA_ "SPN" SG_ 2566875411 pEPS_Message_Counter 524010;
BA_ "SPN" SG_ 2566875411 pSteerAssistTq 524003;
BA_ "SPN" SG_ 2566875411 pGeneratedCurrent 524004;
BA_ "SPN" SG_ 2566875411 pSensed_Input_Steering_Torque 524002;
BA_ "SPN" SG_ 2566875411 pEPS_CRC8 524011;
BA_ "SPN" SG_ 2566834707 Flash_Malfunction_Indicator_Lamp 3038;
BA_ "SPN" SG_ 2566834707 Malfunction_Indicator_Lamp_Statu 1213;
BA_ "SPN" SG_ 2566834707 Red_Stop_Lamp_Status 623;
BA_ "SPN" SG_ 2566834707 Amber_Warning_Lamp_Status 624;
BA_ "SPN" SG_ 2566834707 Flash_Red_Stop_Lamp_RSL 3039;
BA_ "SPN" SG_ 2566834707 Flash_Amber_Warning_Lamp_AWL 3040;
BA_ "SPN" SG_ 2566834707 Flash_Protect_Lamp 3041;
BA_ "SPN" SG_ 2566834707 Protect_Lamp_Status 987;
BA_ "SPN" SG_ 2566834707 DTC_1 999990;
BA_ "SPN" SG_ 2566834707 DTC_2 999991;
BA_ "SPN" SG_ 2566834707 DTC_3 999992;
BA_ "SPN" SG_ 2566834707 DTC_4 999993;
BA_ "SPN" SG_ 2566834707 DTC_5 999994;
BA_ "SPN" SG_ 2566834707 DTC_6 999995;
BA_ "SPN" SG_ 2566834707 DTC_7 999996;
BA_ "SPN" SG_ 2566834707 DTC_8 999997;
BA_ "SPN" SG_ 2566834707 DTC_9 999998;
BA_ "SPN" SG_ 2566834707 DTC_10 999999;
BA_ "SPN" SG_ 2565865751 ABS_Offroad_Switch 575;
BA_ "SPN" SG_ 2565865751 ABSEBS_Amber_Warning_Signal_Powe 1438;
BA_ "SPN" SG_ 2565865751 ASR_Brake_Control_Active 562;
BA_ "SPN" SG_ 2565865751 Source_Address_of_Controlling_De 1481;
BA_ "SPN" SG_ 2565865751 EBS_Red_Warning_Signal 1439;
BA_ "SPN" SG_ 2565865751 ASR_Engine_Control_Active 561;
BA_ "SPN" SG_ 2565865751 AntiLock_Braking_ABS_Active 563;
BA_ "SPN" SG_ 2565865751 ATCASR_Information_Signal 1793;
BA_ "SPN" SG_ 2565865751 ABS_Fully_Operational 1243;
BA_ "SPN" SG_ 2565865751 Traction_Control_Override_Switch 1238;
BA_ "SPN" SG_ 2631859991 Trip_Group_1 988;
BA_ "SPN" SG_ 2631859991 Trip_Group_2__Proprietary 989;
BA_ "SPN" SG_ 2566834711 Flash_Malfunction_Indicator_Lamp 3038;
BA_ "SPN" SG_ 2566834711 Malfunction_Indicator_Lamp_Statu 1213;
BA_ "SPN" SG_ 2566834711 Red_Stop_Lamp_Status 623;
BA_ "SPN" SG_ 2566834711 Amber_Warning_Lamp_Status 624;
BA_ "SPN" SG_ 2566834711 Flash_Red_Stop_Lamp_RSL 3039;
BA_ "SPN" SG_ 2566834711 Flash_Amber_Warning_Lamp_AWL 3040;
BA_ "SPN" SG_ 2566834711 Flash_Protect_Lamp 3041;
BA_ "SPN" SG_ 2566834711 Protect_Lamp_Status 987;
BA_ "SPN" SG_ 2566834711 DTC_1 999990;
BA_ "SPN" SG_ 2566834711 DTC_2 999991;
BA_ "SPN" SG_ 2566834711 DTC_3 999992;
BA_ "SPN" SG_ 2566834711 DTC_4 999993;
BA_ "SPN" SG_ 2566834711 DTC_5 999994;
BA_ "SPN" SG_ 2566834711 DTC_6 999995;
BA_ "SPN" SG_ 2566834711 DTC_7 999996;
BA_ "SPN" SG_ 2566834711 DTC_8 999997;
BA_ "SPN" SG_ 2566834711 DTC_9 999998;
BA_ "SPN" SG_ 2566834711 DTC_10 999999;
BA_ "SPN" SG_ 2564161303 Adjust_hours 1605;
BA_ "SPN" SG_ 2564161303 Adjust_day 1607;
BA_ "SPN" SG_ 2564161303 Adjust_local_hour_offset 1610;
BA_ "SPN" SG_ 2564161303 Adjust_seconds 1603;
BA_ "SPN" SG_ 2564161303 Adjust_month 1606;
BA_ "SPN" SG_ 2564161303 Adjust_year 1608;
BA_ "SPN" SG_ 2564161303 Adjust_local_minute_offset 1609;
BA_ "SPN" SG_ 2564161303 Adjust_minutes 1604;
BA_ "SPN" SG_ 2563833623 Illumination_Brightness_Percent 1487;
BA_ "SPN" SG_ 2566832407 Total_Vehicle_Distance_High_Reso 917;
BA_ "SPN" SG_ 2566832407 Trip_Distance_High_Resolution 918;
BA_ "SPN" SG_ 2566847511 Fuel_Level_1 96;
BA_ "SPN" SG_ 2631794455 Antitheft_Desired_Exit_Mode_Stat 1200;
BA_ "SPN" SG_ 2631794455 Antitheft_Encryption_Indicator_S 1199;
BA_ "SPN" SG_ 2631794455 Antitheft_Command_States 1201;
BA_ "SPN" SG_ 2631794455 Antitheft_Password_Representatio 1202;
BA_ "SPN" SG_ 2566845719 Ambient_Air_Temperature 171;
BA_ "SPN" SG_ 2566845719 Barometric_Pressure 108;
BA_ "SPN" SG_ 2566845719 Road_Surface_Temperature 79;
BA_ "SPN" SG_ 2566845719 Engine_Intake_1_Air_Temperature 172;
BA_ "SPN" SG_ 2432658455 pFOCC_Checksum 524081;
BA_ "SPN" SG_ 2432658455 Drive_Mode__4 524063;
BA_ "SPN" SG_ 2432658455 Drive_Mode__2 524061;
BA_ "SPN" SG_ 2432658455 pFOCC_Message_Counter 524082;
BA_ "SPN" SG_ 2432658455 Drivers_Net_Engagement 524066;
BA_ "SPN" SG_ 2432658455 Foot_On_Cruise_Control_Switch 524072;
BA_ "SPN" SG_ 2432658455 Drive_Mode__1 524060;
BA_ "SPN" SG_ 2432658455 Momentary_Driveline_Left_Press 520467;
BA_ "SPN" SG_ 2432658455 CylDeAc_Enable 521197;
BA_ "SPN" SG_ 2432658455 Work_Group_Lock_Switch 524069;
BA_ "SPN" SG_ 2432658455 Drivers_Seatbelt_Engagement 524065;
BA_ "SPN" SG_ 2432658455 Drive_Mode__3 524062;
BA_ "SPN" SG_ 2432658455 Work_Mode_Switch 524071;
BA_ "SPN" SG_ 2432658455 Momentary_Driveline_Right_Press 520468;
BA_ "SPN" SG_ 2432658455 PTO_Mode_Switch_RPM_Control 524064;
BA_ "SPN" SG_ 2432658455 Operator_Presence_Switch 524070;
BA_ "SPN" SG_ 2432658455 Tilt_Lock_Switch 524068;
BA_ "SPN" SG_ 2432658455 Engine_Brake_Enable 521198;
BA_ "SPN" SG_ 2432658455 Accessory_Relay 520469;
BA_ "SPN" SG_ 2566876439 pFarm_Mode_Set_Speed 520633;
BA_ "SPN" SG_ 2566876439 pDrive_Mode_Requested 524067;
BA_ "SPN" SG_ 2566876439 pFarm_Mode_Maximum_Speed 520631;
BA_ "SPN" SG_ 2566876439 pDrive_Mode_Commanded 524077;
BA_ "SPN" SG_ 2566876439 pEngine_Brake_Active 521200;
BA_ "SPN" SG_ 2566876439 pFarm_Mode_Minimum_Speed 520632;
BA_ "SPN" SG_ 2566876439 pFoot_On_Cruise_Enable 524073;
BA_ "SPN" SG_ 2566876439 pFarm_Mode_Speed_Decrement 520628;
BA_ "SPN" SG_ 2566876439 pEngine_Brake_Enabled 521199;
BA_ "SPN" SG_ 2566876439 pCylDeAc_Enabled 521194;
BA_ "SPN" SG_ 2566876439 pFarm_Mode_Speed_Increment 520627;
BA_ "SPN" SG_ 2566876439 pCylDeAc_Active 521195;
BA_ "SPN" SG_ 2566887959 pAntiTheft_Component_Status_Indi 521196;
BA_ "SPN" SG_ 2566887959 pAntiTheft_Command_States 521201;
BA_ "SPN" SG_ 2566887959 pAntiTheft_Pin_Presence 516227;
BA_ "SPN" SG_ 2566887959 pAntiTheft_Pin_Parameter 516228;
BA_ "SPN" SG_ 2566865687 pASL_Enable 520685;
BA_ "SPN" SG_ 2566865687 pASL_Maximum_Speed 520680;
BA_ "SPN" SG_ 2566865687 pASL_Set_Speed 520682;
BA_ "SPN" SG_ 2566865687 pASL_Speed_Decrement 520684;
BA_ "SPN" SG_ 2566865687 pASL_Speed_Increment 520683;
BA_ "SPN" SG_ 2566865687 pASL_Minimum_Speed 520681;
BA_ "SPN" SG_ 2566877463 pTemperature_Units_Selected 524266;
BA_ "SPN" SG_ 2566877463 pTPMS_Learning_Status 524104;
BA_ "SPN" SG_ 2566877463 pPressure_Units_Selected 524269;
BA_ "SPN" SG_ 2566877463 pHigh_Res_Trip_2_Distance 524264;
BA_ "SPN" SG_ 2566877463 pVolume_Units_Selected 524267;
BA_ "SPN" SG_ 2566877463 pDisplay_Status 524105;
BA_ "SPN" SG_ 2566877463 pTime_Units_Selected 524268;
BA_ "SPN" SG_ 2566877463 pDistance_Units_Selected 524265;
BA_ "SPN" SG_ 2348875548 Engine_Requested_Torque_Fraction 4191;
BA_ "SPN" SG_ 2348875548 Engine_Override_Control_Mode 695;
BA_ "SPN" SG_ 2348875548 Engine_Requested_SpeedSpeed_Limi 898;
BA_ "SPN" SG_ 2348875548 Engine_Requested_Speed_Control_C 696;
BA_ "SPN" SG_ 2348875548 TSC1_Control_Purpose 3350;
BA_ "SPN" SG_ 2348875548 Override_Control_Mode_Priority 897;
BA_ "SPN" SG_ 2348875548 TSC1_Transmission_Rate 3349;
BA_ "SPN" SG_ 2348875548 Engine_Requested_TorqueTorque_Li 518;
BA_ "SPN" SG_ 2566842396 Compass_Bearing 165;
BA_ "SPN" SG_ 2631728925 Antitheft_Random_Number 1198;
BA_ "SPN" SG_ 2631728925 Antitheft_Encryption_Seed_Presen 1194;
BA_ "SPN" SG_ 2631728925 Antitheft_Password_Valid_Indicat 1195;
BA_ "SPN" SG_ 2631728925 Antitheft_Modify_Password_States 1197;
BA_ "SPN" SG_ 2631728925 Antitheft_Component_Status_State 1196;
BA_ "SPN" SG_ 2566877469 pTemperature_Units_Selected 524266;
BA_ "SPN" SG_ 2566877469 pTPMS_Learning_Status 524104;
BA_ "SPN" SG_ 2566877469 pPressure_Units_Selected 524269;
BA_ "SPN" SG_ 2566877469 pHigh_Res_Trip_2_Distance 524264;
BA_ "SPN" SG_ 2566877469 pVolume_Units_Selected 524267;
BA_ "SPN" SG_ 2566877469 pDisplay_Status 524105;
BA_ "SPN" SG_ 2566877469 pTime_Units_Selected 524268;
BA_ "SPN" SG_ 2566877469 pDistance_Units_Selected 524265;
BA_ "SPN" SG_ 2633984541 pHeated_Grip_Enable 520366;
BA_ "SPN" SG_ 2633984541 pUser_PIN_Access_Status 516128;
BA_ "SPN" SG_ 2633984541 pActive_Descent_Control_ADC_Stat 524013;
BA_ "SPN" SG_ 2633984541 pCruise_Control_Set_Status 524097;
BA_ "SPN" SG_ 2633984541 pTether_Switch_Status 520600;
BA_ "SPN" SG_ 2633984541 pHigh_Beam_Indicator_Status 524084;
BA_ "SPN" SG_ 2633984541 pLow_Fuel_Indicator_Status 524087;
BA_ "SPN" SG_ 2633984541 pHeated_Grips_Percentage 524096;
BA_ "SPN" SG_ 2633984541 pSide_Stand_Status 524270;
BA_ "SPN" SG_ 2633984541 pTurf_Mode_Requested 524136;
BA_ "SPN" SG_ 2633984541 pEngine_Idle_Shutdown_Timer 516223;
BA_ "SPN" SG_ 2633984541 Operator_Not_in_Operating_Statio 520247;
BA_ "SPN" SG_ 2633984541 pAWD_Mode_Requested 524138;
BA_ "SPN" SG_ 2633984541 pHeated_Grips_Up_Switch_Status 516129;
BA_ "SPN" SG_ 2633984541 pTreadle_Neutral_Status 524017;
BA_ "SPN" SG_ 2633984541 pHeated_Grips_Down_Switch_Status 516130;
BA_ "SPN" SG_ 2633984541 pPark_Brake_Indicator_Status 524271;
BA_ "SPN" SG_ 2633984541 pRWD_Mode_Requested 524137;
BA_ "SPN" SG_ 2633984541 pSeat_Belt_Indicator_Status 524092;
BA_ "SPN" SG_ 2633984541 pSecurity_Light_Immobilizer_Stat 524019;
BA_ "SPN" SG_ 2633984541 ECU_Security_Status 516202;
BA_ "SPN" SG_ 2633984541 pActive_Decent_Control_ADC_Mode_ 524139;
BA_ "SPN" SG_ 2633984541 pTreadle_Reverse_Status 524018;
BA_ "SPN" SG_ 2566834717 Flash_Malfunction_Indicator_Lamp 3038;
BA_ "SPN" SG_ 2566834717 Malfunction_Indicator_Lamp_Statu 1213;
BA_ "SPN" SG_ 2566834717 Red_Stop_Lamp_Status 623;
BA_ "SPN" SG_ 2566834717 Amber_Warning_Lamp_Status 624;
BA_ "SPN" SG_ 2566834717 Flash_Red_Stop_Lamp_RSL 3039;
BA_ "SPN" SG_ 2566834717 Flash_Amber_Warning_Lamp_AWL 3040;
BA_ "SPN" SG_ 2566834717 Flash_Protect_Lamp 3041;
BA_ "SPN" SG_ 2566834717 Protect_Lamp_Status 987;
BA_ "SPN" SG_ 2566834717 DTC_1 999990;
BA_ "SPN" SG_ 2566834717 DTC_2 999991;
BA_ "SPN" SG_ 2566834717 DTC_3 999992;
BA_ "SPN" SG_ 2566834717 DTC_4 999993;
BA_ "SPN" SG_ 2566834717 DTC_5 999994;
BA_ "SPN" SG_ 2566834717 DTC_6 999995;
BA_ "SPN" SG_ 2566834717 DTC_7 999996;
BA_ "SPN" SG_ 2566834717 DTC_8 999997;
BA_ "SPN" SG_ 2566834717 DTC_9 999998;
BA_ "SPN" SG_ 2566834717 DTC_10 999999;
BA_ "SPN" SG_ 2631794461 Antitheft_Desired_Exit_Mode_Stat 1200;
BA_ "SPN" SG_ 2631794461 Antitheft_Encryption_Indicator_S 1199;
BA_ "SPN" SG_ 2631794461 Antitheft_Command_States 1201;
BA_ "SPN" SG_ 2631794461 Antitheft_Password_Representatio 1202;
BA_ "SPN" SG_ 2566845469 Tire_Temperature 242;
BA_ "SPN" SG_ 2566845469 Tire_Pressure 241;
BA_ "SPN" SG_ 2566845469 Tire_Location 929;
BA_ "SPN" SG_ 2365523485 pModule_Control_Applied_State 516096;
BA_ "SPN" SG_ 2365523485 pModule_Control_Command_Destinat 524185;
BA_ "SPN" SG_ 2365523485 pModule_Control_Command_State 524248;
BA_ "SPN" SG_ 2365523485 pModule_Control_Message_Checksum 516097;
BA_ "SPN" SG_ 2566834973 Protect_Lamp_Status 987;
BA_ "SPN" SG_ 2566834973 Amber_Warning_Lamp_Status 624;
BA_ "SPN" SG_ 2566834973 Red_Stop_Lamp_Status 623;
BA_ "SPN" SG_ 2566834973 Malfunction_Indicator_Lamp_Statu 1213;
BA_ "SPN" SG_ 2566834973 Flash_Protect_Lamp 3041;
BA_ "SPN" SG_ 2566834973 Flash_Amber_Warning_Lamp_AWL 3040;
BA_ "SPN" SG_ 2566834973 Flash_Red_Stop_Lamp_RSL 3039;
BA_ "SPN" SG_ 2566834973 Flash_Malfunction_Indicator_Lamp 3038;
BA_ "SPN" SG_ 2566834973 DTC_1 999990;
BA_ "SPN" SG_ 2566834973 DTC_2 999991;
BA_ "SPN" SG_ 2566834973 DTC_3 999992;
BA_ "SPN" SG_ 2566834973 DTC_4 999993;
BA_ "SPN" SG_ 2566834973 DTC_5 999994;
BA_ "SPN" SG_ 2566834973 DTC_6 999995;
BA_ "SPN" SG_ 2566834973 DTC_7 999996;
BA_ "SPN" SG_ 2566834973 DTC_8 999997;
BA_ "SPN" SG_ 2566834973 DTC_9 999998;
BA_ "SPN" SG_ 2566834973 DTC_10 999999;
BA_ "SPN" SG_ 2432656669 Key_Fob_Unlock_Button_Status 524044;
BA_ "SPN" SG_ 2432656669 Homelink_2 524037;
BA_ "SPN" SG_ 2432656669 Side_Stand_Switch 524098;
BA_ "SPN" SG_ 2432656669 Key_Fob_Lock_Button_Status 524043;
BA_ "SPN" SG_ 2432656669 Windshield__2_Down 524034;
BA_ "SPN" SG_ 2432656669 Turn__3_Cancel 524052;
BA_ "SPN" SG_ 2432656669 Reverse 524039;
BA_ "SPN" SG_ 2432656669 Hazard 524051;
BA_ "SPN" SG_ 2432656669 Homelink_1 524038;
BA_ "SPN" SG_ 2432656669 Windshield__1_Up 524035;
BA_ "SPN" SG_ 2432656669 Front_Brake_Switch 520322;
BA_ "SPN" SG_ 2432656669 Instrument_Cluster_Control__2 524058;
BA_ "SPN" SG_ 2432656669 Chassis_Unlock_Button_Status 524042;
BA_ "SPN" SG_ 2432656669 Power_Button 520362;
BA_ "SPN" SG_ 2432656669 RunStop_Switch 524040;
BA_ "SPN" SG_ 2432656669 Headlamp__2_High 524056;
BA_ "SPN" SG_ 2432656669 Instrument_Cluster_Control__1 524059;
BA_ "SPN" SG_ 2432656669 Clutch_Switch 524032;
BA_ "SPN" SG_ 2432656669 Start 524046;
BA_ "SPN" SG_ 2432656669 Headlamp__3_Driving 524055;
BA_ "SPN" SG_ 2432656669 Cruise__2_Set 524049;
BA_ "SPN" SG_ 2432656669 Windshield_Wiper 524041;
BA_ "SPN" SG_ 2432656669 Fog 524045;
BA_ "SPN" SG_ 2432656669 Cruise__3_Accel 524048;
BA_ "SPN" SG_ 2432656669 Horn 524047;
BA_ "SPN" SG_ 2432656669 Turn__2_Right 524053;
BA_ "SPN" SG_ 2432656669 Cruise__1_On 524050;
BA_ "SPN" SG_ 2432656669 Turn__1_Left 524054;
BA_ "SPN" SG_ 2432656669 Throttle_Safety_Switch__1 524036;
BA_ "SPN" SG_ 2432656669 Headlamp__1_Low 524057;
BA_ "SPN" SG_ 2432656669 Chassis_Lock_Switch_Status 516131;
BA_ "SPN" SG_ 2432656669 Fuel_Door_Unlock_Button_Status 516191;
BA_ "GenMsgCycleTime" BO_ 2566884352 20;
BA_ "GenMsgCycleTime" BO_ 2566876928 1000;
BA_ "GenMsgCycleTime" BO_ 2566886400 100;
BA_ "GenMsgCycleTime" BO_ 2566886912 1000;
BA_ "GenMsgCycleTime" BO_ 2348941056 50;
BA_ "GenMsgCycleTime" BO_ 2365530112 10;
BA_ "GenMsgCycleTime" BO_ 2365532416 10;
BA_ "GenMsgCycleTime" BO_ 2348941061 50;
BA_ "GenMsgCycleTime" BO_ 2348875531 50;
BA_ "GenMsgCycleTimeFast" BO_ 2348875531 10;
BA_ "GenMsgCycleTime" BO_ 2365449739 100;
BA_ "GenMsgCycleTime" BO_ 2565867787 10;
BA_ "GenMsgCycleTime" BO_ 2349465355 100;
BA_ "GenMsgCycleTime" BO_ 2565865739 100;
BA_ "GenMsgCycleTime" BO_ 2566803211 100;
BA_ "GenMsgCycleTime" BO_ 2566834699 1000;
BA_ "GenMsgCycleTime" BO_ 2566846219 1000;
BA_ "GenMsgCycleTime" BO_ 2365532427 10;
BA_ "GenMsgCycleTime" BO_ 2566831883 100;
BA_ "GenMsgCycleTime" BO_ 2566844683 100;
BA_ "GenMsgCycleTime" BO_ 2365552395 20;
BA_ "GenMsgCycleTime" BO_ 2365531915 20;
BA_ "GenMsgCycleTime" BO_ 2365536779 500;
BA_ "GenMsgCycleTimeFast" BO_ 2365536779 100;
BA_ "GenMsgCycleTime" BO_ 2231336203 100;
BA_ "GenMsgCycleTimeFast" BO_ 2231336203 10;
BA_ "GenMsgCycleTime" BO_ 2231336205 100;
BA_ "GenMsgCycleTimeFast" BO_ 2231336205 10;
BA_ "GenMsgCycleTime" BO_ 2566877965 200;
BA_ "GenMsgCycleTimeFast" BO_ 2566877965 10;
BA_ "GenMsgCycleTime" BO_ 2566846227 1000;
BA_ "GenMsgCycleTime" BO_ 2365547027 10;
BA_ "GenMsgCycleTime" BO_ 2566874899 100;
BA_ "GenMsgCycleTime" BO_ 2365551635 10;
BA_ "GenMsgCycleTime" BO_ 2566875411 100;
BA_ "GenMsgCycleTime" BO_ 2566834707 1000;
BA_ "GenMsgCycleTime" BO_ 2565865751 100;
BA_ "GenMsgCycleTime" BO_ 2566834711 1000;
BA_ "GenMsgCycleTime" BO_ 2563833623 5000;
BA_ "GenMsgCycleTimeFast" BO_ 2563833623 100;
BA_ "GenMsgCycleTime" BO_ 2566832407 1000;
BA_ "GenMsgCycleTime" BO_ 2566847511 1000;
BA_ "GenMsgCycleTime" BO_ 2566845719 1000;
BA_ "GenMsgCycleTime" BO_ 2432658455 200;
BA_ "GenMsgCycleTimeFast" BO_ 2432658455 100;
BA_ "GenMsgCycleTime" BO_ 2566876439 100;
BA_ "GenMsgCycleTimeFast" BO_ 2566876439 100;
BA_ "GenMsgCycleTime" BO_ 2566865687 100;
BA_ "GenMsgCycleTimeFast" BO_ 2566865687 10;
BA_ "GenMsgCycleTime" BO_ 2566877463 1000;
BA_ "GenMsgCycleTime" BO_ 2348875548 50;
BA_ "GenMsgCycleTimeFast" BO_ 2348875548 10;
BA_ "GenMsgCycleTimeFast" BO_ 2566842396 60000;
BA_ "GenMsgCycleTime" BO_ 2566877469 1000;
BA_ "GenMsgCycleTime" BO_ 2633984541 500;
BA_ "GenMsgCycleTimeFast" BO_ 2633984541 100;
BA_ "GenMsgCycleTime" BO_ 2566834717 1000;
BA_ "GenMsgCycleTime" BO_ 2566845469 10000;
BA_ "GenMsgCycleTime" BO_ 2365523485 5000;
BA_ "GenMsgCycleTimeFast" BO_ 2365523485 50;
BA_ "GenMsgCycleTime" BO_ 2432656669 200;
BA_ "GenMsgCycleTimeFast" BO_ 2432656669 100;
VAL_ 2566876928 pSecondary_Air_Valve_Control 2 "Error" 0 "Off" 1 "On" 3 "Not-Available" ;
VAL_ 2566886912 pBoundary_Status_Message 1 "Normal Operation" 14 "Error State" 0 "Normal Operation" 15 "Not Available" ;
VAL_ 2566886912 pVehicle_EnableDisable 1 "Normal Operation" 14 "Error State" 0 "Normal Operation" 15 "Not Available" ;
VAL_ 2566886912 pFleet_Management_Default_Vehicl 14 "Error State" 15 "Not Available " 0 "Vehicle Disable Default State" ;
VAL_ 2566886912 pUser_Authentication_Status 1 "Normal Operation" 14 "Error State" 0 "Normal Operation" 15 "Not Available" ;
VAL_ 2566887936 pAntiTheft_Component_Status_Indi 1 "Feature available, enabled, and component is Locked (do not allow to start)" 0 "Feature available, enabled, and component is Unlocked (allow to start)" 3 "Feature not available" 2 "Feature available, but disabled (allow to start)" ;
VAL_ 2566887936 pAntiTheft_Command_States 1 " Disable Feature" 3 "Toggle from Locked to Unlocked, or Unlocked to Locked" 0 "Enable Feature" 4 "Check Status" ;
VAL_ 2566887936 pAntiTheft_Pin_Presence 2 "Error" 0 "Off" 1 "On" 3 "Not-Available" ;
VAL_ 2348941056 pTransmission_Mode_5_Request 2 "Error" 0 "Off" 1 "On" 3 "Not-Available" ;
VAL_ 2365530112 pEngine_Control_Mode 14 "Error" 3 "Engine Torque Request" 2 " Engine Speed Limit" 0 "No Control Request" 15 "Not Available" 1 "Engine Speed Request" 4 "Engine Torque Limit" ;
VAL_ 2365530112 pEngine_Control_Requestor 11 "Remote Accelerator" 8 "Torque Limiting" 9 "High Speed Governor" 15 "Not available" 1 "Accelerator Pedal/Operator Selection" 4 "Road Speed Governor" 0 "Low Idle Governor/No Request" 6 "Transmission Control" 7 "ABS Control" 10 "Braking System" 2 "Cruise Control" 5 "ASR Control" 3 "PTO Governor" ;
VAL_ 2365532416 pAMTPumpStatus 2 "Error" 0 "Off" 1 "On" 3 "Not-Available" ;
VAL_ 2365532416 pEngine_Control_Shutdown_Request 2 "Error" 0 "Off" 1 "On" 3 "Not-Available" ;
VAL_ 2365532416 pAMTClutchStatus 1 "Engaging" 4 "Controller Slip" 0 "Disengaged" 2 "Engaged" 3 "Disengaging" ;
VAL_ 2348941061 pTransmission_Mode_5_Request 2 "Error" 0 "Off" 1 "On" 3 "Not-Available" ;
VAL_ 2365532427 pAMTPumpStatus 2 "Error" 0 "Off" 1 "On" 3 "Not-Available" ;
VAL_ 2365532427 pEngine_Control_Shutdown_Request 2 "Error" 0 "Off" 1 "On" 3 "Not-Available" ;
VAL_ 2365532427 pAMTClutchStatus 1 "Engaging" 4 "Controller Slip" 0 "Disengaged" 2 "Engaged" 3 "Disengaging" ;
VAL_ 2566844683 pOdometer_Drive_Bit 3 "Not Available " 2 "Error" 0 "State A" 1 "State B" ;
VAL_ 2566844683 pCruise_Enable_Status 14 "Error" 15 "Not Available " 0 "Not enabled. System must be enabled before it is set" 1 "Enable. System is ready to be set by operator. Only change state when system is enabled/disabled with on/off switch" ;
VAL_ 2365531915 pBrake_Switch_Status 2 "Error" 0 "Off" 1 "On" 3 "Not-Available" ;
VAL_ 2365536779 pABS_Mode_Status 0 " ABS Functionality OFF" 9 "ABS OFF-> ON Transition State" 3 "ABS Mode 3" 4 " ABS Mode 4" 14 "Error" 2 " ABS Mode 2" 8 "ABS ON -> OFF Transition State" 1 "ABS Mode 1" ;
VAL_ 2365536779 pESC_Mode_Status 4 "Mode 4" 1 "Mode 1" 8 "ON -> OFF Transition State" 2 "Mode 2" 14 "Error" 3 "Mode 3" 9 "OFF-> ON Transition State" 0 "Functionality OFF" ;
VAL_ 2365536779 pABS_Transition_Status 2 "Error" 0 "Off" 1 "On" 3 "Not-Available" ;
VAL_ 2365536779 pTC_Mode_Status 4 "Mode 4" 1 "Mode 1" 8 "ON -> OFF Transition State" 2 "Mode 2" 14 "Error" 3 "Mode 3" 9 "OFF-> ON Transition State" 0 "Functionality OFF" ;
VAL_ 2231336203 pEBC_Mode_Status 4 "Reserved" 5 "Reserved" 6 "Error" 1 "Manned NonAssist" 2 "Remote Mode" 3 "Reserved" 0 "Manned Assist Mode" 7 "NA" ;
VAL_ 2231336205 pEBC_Mode_Status 4 "Reserved" 5 "Reserved" 6 "Error" 1 "Manned NonAssist" 2 "Remote Mode" 3 "Reserved" 0 "Manned Assist Mode" 7 "NA" ;
VAL_ 2566877965 pEPS_Commanded_Control_Mode 3 "Speed: mosfets powered, unit responds to hold or attain a given speed and direction." 0 "Off: all mosfet drivers are off, control motor is freely back driven." 5 "Position w/ Speed: mosfets powered, unit responds to hold or attain a given angular position without exceeding a given angular speed." 2 "Torque Assist: mosfets powered, unit responds to torque input, current command is generated using the programmed assist curve." 16 "Set Position: all Mosfets drivers are off, sets the unit current position to the given value then transfers to off mode." 4 "Position: mosfets powered, unit responds to hold or attain a given angular position." ;
VAL_ 2365547027 pEPS_Requested_Mode_Ack 10 "EPS Assist Mode 1 (MY20)" 0 "Assist Off" 15 "Not Available" 12 "EPS Assist Mode 3 (MY20)" 11 "EPS Assist Mode 2 (MY20)" ;
VAL_ 2365547027 pEPS_Active_Mode 13 "0x0D EPS Assist Mode 4" 0 "Assist Off: all mosfet drivers are off, control motor is freely back driven" 7 "Initializing" 8 " Fault – No Assist" 11 "0x0B EPS Assist Mode 2" 10 "0x0A EPS Assist Mode 1" 12 "0x0C EPS Assist Mode 3" 9 "Default Assist Mode/No Requests" ;
VAL_ 2365551635 pEPS_Operation_Status 1 "Backup Mode" 7 "Not Available" 0 "Fully Functional" 5 "Error (non-functional with DM1)" 2 "Limp Home Mode" ;
VAL_ 2365551635 pEPS_SAS_Calibrated 2 "Error" 0 "Off" 1 "On" 3 "Not-Available" ;
VAL_ 2365551635 pEPS_Active_Mode 13 "0x0D EPS Assist Mode 4" 0 "Assist Off: all mosfet drivers are off, control motor is freely back driven" 7 "Initializing" 8 " Fault – No Assist" 11 "0x0B EPS Assist Mode 2" 10 "0x0A EPS Assist Mode 1" 12 "0x0C EPS Assist Mode 3" 9 "Default Assist Mode/No Requests" ;
VAL_ 2432658455 Drive_Mode__4 2 "Error" 0 "Off" 1 "On" 3 "Not-Available" ;
VAL_ 2432658455 Drive_Mode__2 2 "Error" 0 "Off" 1 "On" 3 "Not-Available" ;
VAL_ 2432658455 Drivers_Net_Engagement 2 "Error" 0 "Off" 1 "On" 3 "Not-Available" ;
VAL_ 2432658455 Foot_On_Cruise_Control_Switch 2 "Error" 0 "Off" 1 "On" 3 "Not-Available" ;
VAL_ 2432658455 Drive_Mode__1 2 "Error" 0 "Off" 1 "On" 3 "Not-Available" ;
VAL_ 2432658455 Momentary_Driveline_Left_Press 2 "Error" 0 "Off" 1 "On" 3 "Not-Available" ;
VAL_ 2432658455 CylDeAc_Enable 2 "Error" 0 "Off" 1 "On" 3 "Not-Available" ;
VAL_ 2432658455 Work_Group_Lock_Switch 2 "Error" 0 "Off" 1 "On" 3 "Not-Available" ;
VAL_ 2432658455 Drivers_Seatbelt_Engagement 2 "Error" 0 "Off" 1 "On" 3 "Not-Available" ;
VAL_ 2432658455 Drive_Mode__3 2 "Error" 0 "Off" 1 "On" 3 "Not-Available" ;
VAL_ 2432658455 Work_Mode_Switch 2 "Error" 0 "Off" 1 "On" 3 "Not-Available" ;
VAL_ 2432658455 Momentary_Driveline_Right_Press 2 "Error" 0 "Off" 1 "On" 3 "Not-Available" ;
VAL_ 2432658455 PTO_Mode_Switch_RPM_Control 2 "Error" 0 "Off" 1 "On" 3 "Not-Available" ;
VAL_ 2432658455 Operator_Presence_Switch 2 "Error" 0 "Off" 1 "On" 3 "Not-Available" ;
VAL_ 2432658455 Tilt_Lock_Switch 2 "Error" 0 "Off" 1 "On" 3 "Not-Available" ;
VAL_ 2432658455 Engine_Brake_Enable 2 "Error" 0 "Off" 1 "On" 3 "Not-Available" ;
VAL_ 2432658455 Accessory_Relay 0 "Energize" 1 "De-energize" 3 "Not Available" ;
VAL_ 2566876439 pEngine_Brake_Active 2 "Error" 0 "Off" 1 "On" 3 "Not-Available" ;
VAL_ 2566876439 pFoot_On_Cruise_Enable 2 "Error" 0 "Off" 1 "On" 3 "Not-Available" ;
VAL_ 2566876439 pFarm_Mode_Speed_Decrement 2 "Error" 0 "Off" 1 "On" 3 "Not-Available" ;
VAL_ 2566876439 pEngine_Brake_Enabled 2 "Error" 0 "Off" 1 "On" 3 "Not-Available" ;
VAL_ 2566876439 pCylDeAc_Enabled 2 "Error" 0 "Off" 1 "On" 3 "Not-Available" ;
VAL_ 2566876439 pFarm_Mode_Speed_Increment 2 "Error" 0 "Off" 1 "On" 3 "Not-Available" ;
VAL_ 2566876439 pCylDeAc_Active 2 "Error" 0 "Off" 1 "On" 3 "Not-Available" ;
VAL_ 2566887959 pAntiTheft_Component_Status_Indi 1 "Feature available, enabled, and component is Locked (do not allow to start)" 0 "Feature available, enabled, and component is Unlocked (allow to start)" 3 "Feature not available" 2 "Feature available, but disabled (allow to start)" ;
VAL_ 2566887959 pAntiTheft_Command_States 1 " Disable Feature" 3 "Toggle from Locked to Unlocked, or Unlocked to Locked" 0 "Enable Feature" 4 "Check Status" ;
VAL_ 2566887959 pAntiTheft_Pin_Presence 2 "Error" 0 "Off" 1 "On" 3 "Not-Available" ;
VAL_ 2566865687 pASL_Enable 2 "Error" 0 "Off" 1 "On" 3 "Not-Available" ;
VAL_ 2566865687 pASL_Speed_Decrement 2 "Error" 0 "Off" 1 "On" 3 "Not-Available" ;
VAL_ 2566865687 pASL_Speed_Increment 2 "Error" 0 "Off" 1 "On" 3 "Not-Available" ;
VAL_ 2566877463 pTemperature_Units_Selected 0 "Fahrenheit" 1 "Celsius" 3 "Not Available" 2 "Error" ;
VAL_ 2566877463 pTPMS_Learning_Status 7 "Learning Spare Tire" 3 "Learning right front" 1 "Request to start" 13 "Request to end learning process" 14 "Error failed to complete learning process" 2 "Learning left front" 0 "Not started" 5 "Learning right rear" 4 "Learning left rear" 6 "Learning processes successfully completed" 12 "Erase TPMS Sensors" 15 "Not Available" ;
VAL_ 2566877463 pPressure_Units_Selected 3 "Not Available" 1 "Kilopascal (KPa)" 2 "Error" 0 "Pounds Per Square Inch (PSI)" ;
VAL_ 2566877463 pVolume_Units_Selected 6 "Error" 1 "Liters" 0 "Gallons" 7 "Not Avialable" 2 "Imperial Gallons" ;
VAL_ 2566877463 pDisplay_Status 2 "Infotainment can override to full screen" 1 "User has requested full screen" 0 "Infotainment cannot override to full screen" 14 "Infotainment data not being shown" 15 "Not Available" ;
VAL_ 2566877463 pTime_Units_Selected 1 "24 Hour" 3 "Not Available" 0 "12 Hour" 2 "Error" ;
VAL_ 2566877463 pDistance_Units_Selected 1 "Kilometers" 0 "Miles" 3 "Not Available " 2 "Error" ;
VAL_ 2631728925 Antitheft_Password_Valid_Indicat 3 "Not available" 2 "Error" 1 "Password is a validated password" 0 "Password is not a validated password" ;
VAL_ 2566877469 pTemperature_Units_Selected 0 "Fahrenheit" 1 "Celsius" 3 "Not Available" 2 "Error" ;
VAL_ 2566877469 pTPMS_Learning_Status 7 "Learning Spare Tire" 3 "Learning right front" 1 "Request to start" 13 "Request to end learning process" 14 "Error failed to complete learning process" 2 "Learning left front" 0 "Not started" 5 "Learning right rear" 4 "Learning left rear" 6 "Learning processes successfully completed" 12 "Erase TPMS Sensors" 15 "Not Available" ;
VAL_ 2566877469 pPressure_Units_Selected 3 "Not Available" 1 "Kilopascal (KPa)" 2 "Error" 0 "Pounds Per Square Inch (PSI)" ;
VAL_ 2566877469 pVolume_Units_Selected 6 "Error" 1 "Liters" 0 "Gallons" 7 "Not Avialable" 2 "Imperial Gallons" ;
VAL_ 2566877469 pDisplay_Status 2 "Infotainment can override to full screen" 1 "User has requested full screen" 0 "Infotainment cannot override to full screen" 14 "Infotainment data not being shown" 15 "Not Available" ;
VAL_ 2566877469 pTime_Units_Selected 1 "24 Hour" 3 "Not Available" 0 "12 Hour" 2 "Error" ;
VAL_ 2566877469 pDistance_Units_Selected 1 "Kilometers" 0 "Miles" 3 "Not Available " 2 "Error" ;
VAL_ 2633984541 pHeated_Grip_Enable 2 "Error" 0 "Off" 1 "On" 3 "Not-Available" ;
VAL_ 2633984541 pUser_PIN_Access_Status 2 "Error" 0 "Off" 1 "On" 3 "Not-Available" ;
VAL_ 2633984541 pActive_Descent_Control_ADC_Stat 2 "Error" 0 "Off" 1 "On" 3 "Not-Available" ;
VAL_ 2633984541 pCruise_Control_Set_Status 2 "Error" 0 "Off" 1 "On" 3 "Not-Available" ;
VAL_ 2633984541 pTether_Switch_Status 2 "Error" 0 "Off" 1 "On" 3 "Not-Available" ;
VAL_ 2633984541 pHigh_Beam_Indicator_Status 2 "Error" 0 "Off" 1 "On" 3 "Not-Available" ;
VAL_ 2633984541 pLow_Fuel_Indicator_Status 2 "Error" 0 "Off" 1 "On" 3 "Not-Available" ;
VAL_ 2633984541 pSide_Stand_Status 2 "Error" 1 "Side Stand Extended" 0 "Side Stand Retracted" 3 "Not Available" ;
VAL_ 2633984541 pTurf_Mode_Requested 2 "Error" 0 "Off" 1 "On" 3 "Not-Available" ;
VAL_ 2633984541 Operator_Not_in_Operating_Statio 2 "Error" 0 "Off" 1 "On" 3 "Not-Available" ;
VAL_ 2633984541 pAWD_Mode_Requested 2 "Error" 0 "Off" 1 "On" 3 "Not-Available" ;
VAL_ 2633984541 pHeated_Grips_Up_Switch_Status 2 "Error" 0 "Off" 1 "On" 3 "Not-Available" ;
VAL_ 2633984541 pTreadle_Neutral_Status 2 "Error" 0 "Off" 1 "On" 3 "Not-Available" ;
VAL_ 2633984541 pHeated_Grips_Down_Switch_Status 2 "Error" 0 "Off" 1 "On" 3 "Not-Available" ;
VAL_ 2633984541 pPark_Brake_Indicator_Status 2 "Slow Flash (1 Hz, 50% duty cycle)" 7 "Not Available" 1 "On" 3 "Fast Flash (2 HZ or faster, 50% Duty Cycle)" 0 "Off" 6 "Error" ;
VAL_ 2633984541 pRWD_Mode_Requested 2 "Error" 0 "Off" 1 "On" 3 "Not-Available" ;
VAL_ 2633984541 pSeat_Belt_Indicator_Status 2 "Slow Flash (1 Hz, 50% duty cycle)" 7 "Not Available" 1 "On" 3 "Fast Flash (2 HZ or faster, 50% Duty Cycle)" 0 "Off" 6 "Error" ;
VAL_ 2633984541 pSecurity_Light_Immobilizer_Stat 2 "Error" 0 "Off" 1 "On" 3 "Not-Available" ;
VAL_ 2633984541 ECU_Security_Status 1 "Locked, Awaiting Unlock" 3 " Locked, system will shut down" 0 "Unlocked" 7 "Not Available" 2 "Locked, System will not shut down" 6 "Error" ;
VAL_ 2633984541 pActive_Decent_Control_ADC_Mode_ 2 "Error" 0 "Off" 1 "On" 3 "Not-Available" ;
VAL_ 2633984541 pTreadle_Reverse_Status 2 "Error" 0 "Off" 1 "On" 3 "Not-Available" ;
VAL_ 2365523485 pModule_Control_Applied_State 1 "Partial Wakeup Applied " 0 "No Change Applied" 2 "Full Wakeup Applied" 3 "Power Down Applied " 13 "No Change - Checksum Error " 4 "Stay Awake Applied " 14 "Error State" 15 "Not Available" 5 "Alarm Activation Applied " ;
VAL_ 2365523485 pModule_Control_Command_State 3 "Power Down Requested" 2 "Full Wakeup Requested" 15 "Not Available" 14 "Error" 5 "Alarm Activation Requested" 1 "Partial Wakeup Requested" 4 "Stay Awake Requested" 0 "No Change Requested" ;
VAL_ 2432656669 Key_Fob_Unlock_Button_Status 2 "Error" 0 "Off" 1 "On" 3 "Not-Available" ;
VAL_ 2432656669 Homelink_2 2 "Error" 0 "Off" 1 "On" 3 "Not-Available" ;
VAL_ 2432656669 Side_Stand_Switch 2 "Error" 0 "Off" 1 "On" 3 "Not-Available" ;
VAL_ 2432656669 Key_Fob_Lock_Button_Status 2 "Error" 0 "Off" 1 "On" 3 "Not-Available" ;
VAL_ 2432656669 Windshield__2_Down 2 "Error" 0 "Off" 1 "On" 3 "Not-Available" ;
VAL_ 2432656669 Turn__3_Cancel 2 "Error" 0 "Off" 1 "On" 3 "Not-Available" ;
VAL_ 2432656669 Reverse 2 "Error" 0 "Off" 1 "On" 3 "Not-Available" ;
VAL_ 2432656669 Hazard 2 "Error" 0 "Off" 1 "On" 3 "Not-Available" ;
VAL_ 2432656669 Homelink_1 2 "Error" 0 "Off" 1 "On" 3 "Not-Available" ;
VAL_ 2432656669 Windshield__1_Up 2 "Error" 0 "Off" 1 "On" 3 "Not-Available" ;
VAL_ 2432656669 Front_Brake_Switch 2 "Error" 0 "Off" 1 "On" 3 "Not-Available" ;
VAL_ 2432656669 Instrument_Cluster_Control__2 2 "Error" 0 "Off" 1 "On" 3 "Not-Available" ;
VAL_ 2432656669 Chassis_Unlock_Button_Status 2 "Error" 0 "Off" 1 "On" 3 "Not-Available" ;
VAL_ 2432656669 Power_Button 2 "Error" 0 "Off" 1 "On" 3 "Not-Available" ;
VAL_ 2432656669 RunStop_Switch 2 "Error" 0 "Off" 1 "On" 3 "Not-Available" ;
VAL_ 2432656669 Headlamp__2_High 2 "Error" 0 "Off" 1 "On" 3 "Not-Available" ;
VAL_ 2432656669 Instrument_Cluster_Control__1 2 "Error" 0 "Off" 1 "On" 3 "Not-Available" ;
VAL_ 2432656669 Clutch_Switch 2 "Error" 0 "Off" 1 "On" 3 "Not-Available" ;
VAL_ 2432656669 Start 2 "Error" 0 "Off" 1 "On" 3 "Not-Available" ;
VAL_ 2432656669 Headlamp__3_Driving 2 "Error" 0 "Off" 1 "On" 3 "Not-Available" ;
VAL_ 2432656669 Cruise__2_Set 2 "Error" 0 "Off" 1 "On" 3 "Not-Available" ;
VAL_ 2432656669 Windshield_Wiper 2 "Error" 0 "Off" 1 "On" 3 "Not-Available" ;
VAL_ 2432656669 Fog 2 "Error" 0 "Off" 1 "On" 3 "Not-Available" ;
VAL_ 2432656669 Cruise__3_Accel 2 "Error" 0 "Off" 1 "On" 3 "Not-Available" ;
VAL_ 2432656669 Horn 2 "Error" 0 "Off" 1 "On" 3 "Not-Available" ;
VAL_ 2432656669 Turn__2_Right 2 "Error" 0 "Off" 1 "On" 3 "Not-Available" ;
VAL_ 2432656669 Cruise__1_On 2 "Error" 0 "Off" 1 "On" 3 "Not-Available" ;
VAL_ 2432656669 Turn__1_Left 2 "Error" 0 "Off" 1 "On" 3 "Not-Available" ;
VAL_ 2432656669 Throttle_Safety_Switch__1 2 "Error" 0 "Off" 1 "On" 3 "Not-Available" ;
VAL_ 2432656669 Headlamp__1_Low 2 "Error" 0 "Off" 1 "On" 3 "Not-Available" ;
VAL_ 2432656669 Fuel_Door_Unlock_Button_Status 2 "Error Indicator" 3 "Not Available" 1 "Button pressed" 0 "Button not pressed" ;
